VERSION ""

NS_ :

BS_:

BU_: External_Tool CADM LRRF MRRRL MRRRR

BO_ 954 MRR_RL_Radar_Reset_Msg: 1 MRRRL
 SG_ MRR_RL_Radar_Reset : 7|1@0+ (1,0) [0|1] ""  CADM

BO_ 1978 MRR_RR_Radar_Reset_msg: 1 MRRRR
 SG_ MRR_RR_Radar_Reset : 7|1@0+ (1,0) [0|1] ""  CADM

BO_ 93 LRRF1_Radar_Reset_Msg: 1 LRRF
 SG_ LRRF1_Radar_Reset : 7|1@0+ (1,0) [0|1] ""  CADM

BO_ 1698 MRR_RR_Radar_PartNumber: 64 MRRRR
 SG_ MRR_RR_EBOM_SW_PN_Part2 : 367|40@0+ (1,0) [0|1099511627775] ""  CADM
 SG_ MRR_RR_EBOM_SW_PN_Part1 : 327|40@0+ (1,0) [0|1099511627775] ""  CADM
 SG_ MRR_RR_ECU_SerialNumber_Part2 : 159|56@0+ (1,0) [0|7.20575940379279E+016] ""  CADM
 SG_ MRR_RR_ECU_SerialNumber_Part1 : 95|64@0+ (1,0) [0|1.84467440737096E+019] ""  CADM
 SG_ MRR_RR_EBOM_ECU_PN_Part2 : 447|40@0+ (1,0) [0|1099511627775] ""  CADM
 SG_ MRR_RR_EBOM_ECU_PN_Part1 : 407|40@0+ (1,0) [0|1099511627775] ""  CADM
 SG_ MRR_RR_SupplManuf_ECU_SW_VesrNum : 311|16@0+ (1,0) [0|65535] ""  CADM
 SG_ MRR_RR_SupplManuf_ECU_HW_VesrNum : 303|8@0+ (1,0) [0|255] ""  CADM
 SG_ MRR_RR_SupplManuf_ECU_SW_PN_2 : 263|40@0+ (1,0) [0|1099511627775] ""  CADM
 SG_ MRR_RR_SupplManuf_ECU_SW_PN_1 : 215|48@0+ (1,0) [0|281474976710655] ""  CADM
 SG_ MRR_RR_SupplManuf_ECU_HW_PN_2 : 55|40@0+ (1,0) [0|1099511627775] ""  CADM
 SG_ MRR_RR_SupplManuf_ECU_HW_PN_1 : 7|48@0+ (1,0) [0|281474976710655] ""  CADM

BO_ 690 MRR_RL_Radar_PartNumber: 64 MRRRL
 SG_ MRR_RL_EBOM_SW_PN_Part2 : 367|40@0+ (1,0) [0|1099511627775] ""  CADM
 SG_ MRR_RL_EBOM_SW_PN_Part1 : 327|40@0+ (1,0) [0|1099511627775] ""  CADM
 SG_ MRR_RL_ECU_SerialNumber_Part2 : 159|56@0+ (1,0) [0|7.20575940379279E+016] ""  CADM
 SG_ MRR_RL_ECU_SerialNumber_Part1 : 95|64@0+ (1,0) [0|1.84467440737096E+019] ""  CADM
 SG_ MRR_RL_EBOM_ECU_PN_Part2 : 447|40@0+ (1,0) [0|1099511627775] ""  CADM
 SG_ MRR_RL_EBOM_ECU_PN_Part1 : 407|40@0+ (1,0) [0|1099511627775] ""  CADM
 SG_ MRR_RL_SupplManuf_ECU_SW_VesrNum : 311|16@0+ (1,0) [0|65535] ""  CADM
 SG_ MRR_RL_SupplManuf_ECU_HW_VesrNum : 303|8@0+ (1,0) [0|255] ""  CADM
 SG_ MRR_RL_SupplManuf_ECU_SW_PN_2 : 263|40@0+ (1,0) [0|1099511627775] ""  CADM
 SG_ MRR_RL_SupplManuf_ECU_SW_PN_1 : 215|48@0+ (1,0) [0|281474976710655] ""  CADM
 SG_ MRR_RL_SupplManuf_ECU_HW_PN_2 : 55|40@0+ (1,0) [0|1099511627775] ""  CADM
 SG_ MRR_RL_SupplManuf_ECU_HW_PN_1 : 7|48@0+ (1,0) [0|281474976710655] ""  CADM

BO_ 94 LRRF1_Radar_PartNumber: 64 LRRF
 SG_ LRRF1_EBOM_SW_PN_Part2 : 367|40@0+ (1,0) [0|1099511627775] ""  CADM
 SG_ LRRF1_EBOM_SW_PN_Part1 : 327|40@0+ (1,0) [0|1099511627775] ""  CADM
 SG_ LRRF1_ECU_SerialNumber_Part2 : 159|56@0+ (1,0) [0|7.20575940379279E+016] ""  CADM
 SG_ LRRF1_ECU_SerialNumber_Part1 : 95|64@0+ (1,0) [0|1.84467440737096E+019] ""  CADM
 SG_ LRRF1_EBOM_ECU_PN_Part2 : 447|40@0+ (1,0) [0|1099511627775] ""  CADM
 SG_ LRRF1_EBOM_ECU_PN_Part1 : 407|40@0+ (1,0) [0|1099511627775] ""  CADM
 SG_ LRRF1_SupplManuf_ECU_SW_VesrNum : 311|16@0+ (1,0) [0|65535] ""  CADM
 SG_ LRRF1_SupplManuf_ECU_HW_VesrNum : 303|8@0+ (1,0) [0|255] ""  CADM
 SG_ LRRF1_SupplManuf_ECU_SW_PN_2 : 263|40@0+ (1,0) [0|1099511627775] ""  CADM
 SG_ LRRF1_SupplManuf_ECU_SW_PN_1 : 215|48@0+ (1,0) [0|281474976710655] ""  CADM
 SG_ LRRF1_SupplManuf_ECU_HW_PN_2 : 55|40@0+ (1,0) [0|1099511627775] ""  CADM
 SG_ LRRF1_SupplManuf_ECU_HW_PN_1 : 7|48@0+ (1,0) [0|281474976710655] ""  CADM

BO_ 39 MRR_RR_Angle_Adjustment_Table: 20 CADM
 SG_ MRR_RR_AAT_CRC : 151|16@0+ (1,0) [0|65535] ""  MRRRR
 SG_ MRR_RR_AAT_MC : 139|4@0+ (1,0) [0|15] ""  MRRRR
 SG_ MRR_RR_POS_80 : 135|8@0- (0.1,0) [-5|5] "deg"  MRRRR
 SG_ MRR_RR_POS_70 : 127|8@0- (0.1,0) [-5|5] "deg"  MRRRR
 SG_ MRR_RR_POS_60 : 119|8@0- (0.1,0) [-5|5] "deg"  MRRRR
 SG_ MRR_RR_POS_50 : 111|8@0- (0.1,0) [-5|5] "deg"  MRRRR
 SG_ MRR_RR_POS_40 : 103|8@0- (0.1,0) [-5|5] "deg"  MRRRR
 SG_ MRR_RR_POS_30 : 95|8@0- (0.1,0) [-5|5] "deg"  MRRRR
 SG_ MRR_RR_POS_20 : 87|8@0- (0.1,0) [-5|5] "deg"  MRRRR
 SG_ MRR_RR_POS_10 : 79|8@0- (0.1,0) [-5|5] "deg"  MRRRR
 SG_ MRR_RR_0 : 71|8@0- (0.1,0) [-5|5] "deg"  MRRRR
 SG_ MRR_RR_NEG_10 : 63|8@0- (0.1,0) [-5|5] "deg"  MRRRR
 SG_ MRR_RR_NEG_20 : 55|8@0- (0.1,0) [-5|5] "deg"  MRRRR
 SG_ MRR_RR_NEG_30 : 47|8@0- (0.1,0) [-5|5] "deg"  MRRRR
 SG_ MRR_RR_NEG_40 : 39|8@0- (0.1,0) [-5|5] "deg"  MRRRR
 SG_ MRR_RR_NEG_50 : 31|8@0- (0.1,0) [-5|5] "deg"  MRRRR
 SG_ MRR_RR_NEG_60 : 23|8@0- (0.1,0) [-5|5] "deg"  MRRRR
 SG_ MRR_RR_NEG_70 : 15|8@0- (0.1,0) [-5|5] "deg"  MRRRR
 SG_ MRR_RR_NEG_80 : 7|8@0- (0.1,0) [-5|5] "deg"  MRRRR

BO_ 38 MRR_RL_Angle_Adjustment_Table: 20 CADM
 SG_ MRR_RL_AAT_CRC : 151|16@0+ (1,0) [0|65535] ""  MRRRL
 SG_ MRR_RL_AAT_MC : 139|4@0+ (1,0) [0|15] ""  MRRRL
 SG_ MRR_RL_POS_80 : 135|8@0- (0.1,0) [-5|5] "deg"  MRRRL
 SG_ MRR_RL_POS_70 : 127|8@0- (0.1,0) [-5|5] "deg"  MRRRL
 SG_ MRR_RL_POS_60 : 119|8@0- (0.1,0) [-5|5] "deg"  MRRRL
 SG_ MRR_RL_POS_50 : 111|8@0- (0.1,0) [-5|5] "deg"  MRRRL
 SG_ MRR_RL_POS_40 : 103|8@0- (0.1,0) [-5|5] "deg"  MRRRL
 SG_ MRR_RL_POS_30 : 95|8@0- (0.1,0) [-5|5] "deg"  MRRRL
 SG_ MRR_RL_POS_20 : 87|8@0- (0.1,0) [-5|5] "deg"  MRRRL
 SG_ MRR_RL_POS_10 : 79|8@0- (0.1,0) [-5|5] "deg"  MRRRL
 SG_ MRR_RL_0 : 71|8@0- (0.1,0) [-5|5] "deg"  MRRRL
 SG_ MRR_RL_NEG_10 : 63|8@0- (0.1,0) [-5|5] "deg"  MRRRL
 SG_ MRR_RL_NEG_20 : 55|8@0- (0.1,0) [-5|5] "deg"  MRRRL
 SG_ MRR_RL_NEG_30 : 47|8@0- (0.1,0) [-5|5] "deg"  MRRRL
 SG_ MRR_RL_NEG_40 : 39|8@0- (0.1,0) [-5|5] "deg"  MRRRL
 SG_ MRR_RL_NEG_50 : 31|8@0- (0.1,0) [-5|5] "deg"  MRRRL
 SG_ MRR_RL_NEG_60 : 23|8@0- (0.1,0) [-5|5] "deg"  MRRRL
 SG_ MRR_RL_NEG_70 : 15|8@0- (0.1,0) [-5|5] "deg"  MRRRL
 SG_ MRR_RL_NEG_80 : 7|8@0- (0.1,0) [-5|5] "deg"  MRRRL

BO_ 35 LRRF1_Error_Status: 24 LRRF
 SG_ LRRF1_XBAR_cfg_failure : 191|1@0+ (1,0) [0|1] ""  External_Tool
 SG_ LRRF1_Stack_OVF_fault_reason : 183|3@0+ (1,0) [0|7] ""  External_Tool
 SG_ LRRF1_App_flash_checksum_reason : 180|3@0+ (1,0) [0|7] ""  External_Tool
 SG_ LRRF1_KAM_fault_reason : 177|2@0+ (1,0) [0|3] ""  External_Tool
 SG_ LRRF1_RRU_Self_Test_Faults_reaso : 175|8@0+ (1,0) [0|255] ""  External_Tool
 SG_ LRRF1_RRU_Core_Faults_reason3 : 167|8@0+ (1,0) [0|255] ""  External_Tool
 SG_ LRRF1_RRU_Core_Faults_reason2 : 103|64@0+ (1,0) [0|1.84467440737096E+019] ""  External_Tool
 SG_ LRRF1_RRU_Core_Faults_reason1 : 39|64@0+ (1,0) [0|1.84467440737096E+019] ""  External_Tool
 SG_ LRRF1_Rx_Radar_Mount_Msg_Fault : 25|1@0+ (1,0) [0|1] ""  External_Tool
 SG_ LRRF1_USC_Fault_Flag : 24|1@0+ (1,0) [0|1] ""  External_Tool
 SG_ LRRF1_SMC_Fault_Flag : 31|1@0+ (1,0) [0|1] ""  External_Tool
 SG_ LRRF1_Dolphin_Fault_Detection : 23|8@0+ (1,0) [0|63] ""  External_Tool
 SG_ LRRF1_RRU_Self_Test_Faults__0000 : 15|8@0+ (1,0) [0|255] ""  External_Tool
 SG_ LRRF1_RRU_Core_Faults_reason0 : 7|8@0+ (1,0) [0|255] ""  External_Tool

BO_ 69 LRRF1_HW_ID: 64 LRRF
 SG_ LRRF1_CAN_TX_HW_VERSION : 391|4@0+ (1,0) [0|15] ""  CADM
 SG_ LRRF1_Dolphin_Chip_ID_Part2 : 327|64@0+ (1,0) [0|1.84467440737096E+019] ""  CADM
 SG_ LRRF1_Dolphin_Chip_ID_Part1 : 263|64@0+ (1,0) [0|1.84467440737096E+019] ""  CADM
 SG_ LRRF1_RRU_Chip_ID_Part4 : 199|64@0+ (1,0) [0|1.84467440737096E+019] ""  CADM
 SG_ LRRF1_RRU_Chip_ID_Part3 : 135|64@0+ (1,0) [0|1.84467440737096E+019] ""  CADM
 SG_ LRRF1_RRU_Chip_ID_Part2 : 71|64@0+ (1,0) [0|1.84467440737096E+019] ""  CADM
 SG_ LRRF1_RRU_Chip_ID_Part1 : 7|64@0+ (1,0) [0|1.84467440737096E+019] ""  CADM

BO_ 1797 LRRF1_Radar_Cfg_Parameters: 24 CADM
 SG_ LRRF1_FA_HorizMisalignLim : 175|8@0+ (0.1,0) [0|13] "deg"  LRRF
 SG_ LRRF1_FA_TstTolerancePlateAngPos : 167|8@0+ (0.1,0) [0|13] "dBsm"  LRRF
 SG_ LRRF1_FA_TstTolerancePlateAng0 : 159|8@0+ (0.1,0) [0|13] "dBsm"  LRRF
 SG_ LRRF1_FA_TstTolerancePlateAngNeg : 151|8@0+ (0.1,0) [0|13] "dBsm"  LRRF
 SG_ LRRF1_FA_Negative_Angle : 141|6@0+ (0.1,-4) [-4|0] "deg"  LRRF
 SG_ LRRF1_FA_Positive_Angle : 133|6@0+ (0.1,0) [0|4] "deg"  LRRF
 SG_ LRRF1_FA_Target_Range2Mirror : 118|7@0+ (0.0625,0) [0|4] "m"  LRRF
 SG_ LRRF1_FA_Bdgt_Fascia_Attenuation : 126|7@0+ (0.1,-5) [-5|5] "dB"  LRRF
 SG_ LRRF1_Radar_CfgType : 33|2@0+ (1,0) [0|3] ""  LRRF
 SG_ SensorCfg_LRRF_AlignRngTolVert : 111|8@0- (0.0625,0) [-8|7.9375] "deg"  LRRF
 SG_ SensorCfg_LRRF_AlignRngTolHorz : 103|8@0- (0.0625,0) [-8|7.9375] "deg"  LRRF
 SG_ LRRF1_SENSR_CFG_CRC : 183|16@0+ (1,0) [0|65535] ""  LRRF
 SG_ SensorCfg_LRRF_LatPos : 63|16@0- (1,0) [-1000|1000] "mm"  LRRF
 SG_ SensorCfg_LRRF_LongPos : 79|16@0- (1,0) [-32768|32767] "mm"  LRRF
 SG_ SensorCfg_LRRF_VertPos : 47|16@0+ (1,0) [0|2550] "mm"  LRRF
 SG_ SensorCfg_LRRF_Pitch : 23|20@0- (1.526E-005,0) [-6|6] "deg"  LRRF
 SG_ SensorCfg_LRRF_Yaw : 7|16@0- (0.01,0) [-5|5] "deg"  LRRF
 SG_ SensorCfg_LRRF_Orientation : 95|8@0- (1,0) [-1|1] ""  LRRF

BO_ 81 LRRF1_Detection_050_056: 64 LRRF
 SG_ LRRF1_CAN_DET_Near_TARGET_56 : 454|1@0+ (1,0) [0|1] ""  CADM
 SG_ LRRF1_CAN_DET_Near_TARGET_55 : 453|1@0+ (1,0) [0|1] ""  CADM
 SG_ LRRF1_CAN_DET_Near_TARGET_54 : 452|1@0+ (1,0) [0|1] ""  CADM
 SG_ LRRF1_CAN_DET_Near_TARGET_53 : 451|1@0+ (1,0) [0|1] ""  CADM
 SG_ LRRF1_CAN_DET_Near_TARGET_52 : 450|1@0+ (1,0) [0|1] ""  CADM
 SG_ LRRF1_CAN_DET_Near_TARGET_51 : 449|1@0+ (1,0) [0|1] ""  CADM
 SG_ LRRF1_CAN_DET_Near_TARGET_50 : 448|1@0+ (1,0) [0|1] ""  CADM
 SG_ LRRF1_CAN_DET_VALID_LEVEL_51 : 64|1@0+ (1,0) [0|1] ""  CADM
 SG_ LRRF1_CAN_DET_VALID_LEVEL_52 : 128|1@0+ (1,0) [0|1] ""  CADM
 SG_ LRRF1_CAN_DET_VALID_LEVEL_53 : 192|1@0+ (1,0) [0|1] ""  CADM
 SG_ LRRF1_CAN_DET_VALID_LEVEL_54 : 256|1@0+ (1,0) [0|1] ""  CADM
 SG_ LRRF1_CAN_DET_VALID_LEVEL_55 : 320|1@0+ (1,0) [0|1] ""  CADM
 SG_ LRRF1_CAN_DET_VALID_LEVEL_56 : 384|1@0+ (1,0) [0|1] ""  CADM
 SG_ LRRF1_CAN_DET_AMPLITUDE_51 : 71|7@0+ (1,-64) [-64|63] "dBsm"  CADM
 SG_ LRRF1_CAN_DET_AMPLITUDE_52 : 135|7@0+ (1,-64) [-64|63] "dBsm"  CADM
 SG_ LRRF1_CAN_DET_AMPLITUDE_53 : 199|7@0+ (1,-64) [-64|63] "dBsm"  CADM
 SG_ LRRF1_CAN_DET_AMPLITUDE_54 : 263|7@0+ (1,-64) [-64|63] "dBsm"  CADM
 SG_ LRRF1_CAN_DET_AMPLITUDE_55 : 327|7@0+ (1,-64) [-64|63] "dBsm"  CADM
 SG_ LRRF1_CAN_DET_AMPLITUDE_56 : 391|7@0+ (1,-64) [-64|63] "dBsm"  CADM
 SG_ LRRF1_CAN_DET_AZIMUTH_51 : 111|14@0+ (0.0003834,-3.1416) [-3.1416|3.1396422] "rad"  CADM
 SG_ LRRF1_CAN_DET_AZIMUTH_52 : 175|14@0+ (0.0003834,-3.1416) [-3.1416|3.1396422] "rad"  CADM
 SG_ LRRF1_CAN_DET_AZIMUTH_53 : 239|14@0+ (0.0003834,-3.1416) [-3.1416|3.1396422] "rad"  CADM
 SG_ LRRF1_CAN_DET_AZIMUTH_54 : 303|14@0+ (0.0003834,-3.1416) [-3.1416|3.1396422] "rad"  CADM
 SG_ LRRF1_CAN_DET_AZIMUTH_55 : 367|14@0+ (0.0003834,-3.1416) [-3.1416|3.1396422] "rad"  CADM
 SG_ LRRF1_CAN_DET_AZIMUTH_56 : 431|14@0+ (0.0003834,-3.1416) [-3.1416|3.1396422] "rad"  CADM
 SG_ LRRF1_CAN_DET_CONFID_AZIMUTH_51 : 97|2@0+ (1,0) [0|3] ""  CADM
 SG_ LRRF1_CAN_DET_CONFID_AZIMUTH_52 : 161|2@0+ (1,0) [0|3] ""  CADM
 SG_ LRRF1_CAN_DET_CONFID_AZIMUTH_53 : 225|2@0+ (1,0) [0|3] ""  CADM
 SG_ LRRF1_CAN_DET_CONFID_AZIMUTH_54 : 289|2@0+ (1,0) [0|3] ""  CADM
 SG_ LRRF1_CAN_DET_CONFID_AZIMUTH_55 : 353|2@0+ (1,0) [0|3] ""  CADM
 SG_ LRRF1_CAN_DET_CONFID_AZIMUTH_56 : 417|2@0+ (1,0) [0|3] ""  CADM
 SG_ LRRF1_CAN_DET_CONFID_ELEVATION_5 : 120|1@0+ (1,0) [0|1] ""  CADM
 SG_ LRRF1_CAN_DET_CONFID_ELEVAT_0000 : 184|1@0+ (1,0) [0|1] ""  CADM
 SG_ LRRF1_CAN_DET_CONFID_ELEVAT_0001 : 248|1@0+ (1,0) [0|1] ""  CADM
 SG_ LRRF1_CAN_DET_CONFID_ELEVAT_0002 : 312|1@0+ (1,0) [0|1] ""  CADM
 SG_ LRRF1_CAN_DET_CONFID_ELEVAT_0003 : 376|1@0+ (1,0) [0|1] ""  CADM
 SG_ LRRF1_CAN_DET_CONFID_ELEVAT_0004 : 440|1@0+ (1,0) [0|1] ""  CADM
 SG_ LRRF1_CAN_DET_ELEVATION_51 : 127|7@0+ (0.002748,-0.1745) [-0.1745|0.174496] "rad"  CADM
 SG_ LRRF1_CAN_DET_ELEVATION_52 : 191|7@0+ (0.002748,-0.1745) [-0.1745|0.174496] "rad"  CADM
 SG_ LRRF1_CAN_DET_ELEVATION_53 : 255|7@0+ (0.002748,-0.1745) [-0.1745|0.174496] "rad"  CADM
 SG_ LRRF1_CAN_DET_ELEVATION_54 : 319|7@0+ (0.002748,-0.1745) [-0.1745|0.174496] "rad"  CADM
 SG_ LRRF1_CAN_DET_ELEVATION_55 : 383|7@0+ (0.002748,-0.1745) [-0.1745|0.174496] "rad"  CADM
 SG_ LRRF1_CAN_DET_ELEVATION_56 : 447|7@0+ (0.002748,-0.1745) [-0.1745|0.174496] "rad"  CADM
 SG_ LRRF1_CAN_DET_HOST_VEH_CLUTTER_5 : 113|1@0+ (1,0) [0|1] ""  CADM
 SG_ LRRF1_CAN_DET_HOST_VEH_CLUT_0000 : 177|1@0+ (1,0) [0|1] ""  CADM
 SG_ LRRF1_CAN_DET_HOST_VEH_CLUT_0001 : 241|1@0+ (1,0) [0|1] ""  CADM
 SG_ LRRF1_CAN_DET_HOST_VEH_CLUT_0002 : 305|1@0+ (1,0) [0|1] ""  CADM
 SG_ LRRF1_CAN_DET_HOST_VEH_CLUT_0003 : 369|1@0+ (1,0) [0|1] ""  CADM
 SG_ LRRF1_CAN_DET_HOST_VEH_CLUT_0004 : 433|1@0+ (1,0) [0|1] ""  CADM
 SG_ LRRF1_CAN_DET_SUPER_RES_TARGET_5 : 112|1@0+ (1,0) [0|1] ""  CADM
 SG_ LRRF1_CAN_DET_SUPER_RES_TAR_0000 : 176|1@0+ (1,0) [0|1] ""  CADM
 SG_ LRRF1_CAN_DET_SUPER_RES_TAR_0001 : 240|1@0+ (1,0) [0|1] ""  CADM
 SG_ LRRF1_CAN_DET_SUPER_RES_TAR_0002 : 304|1@0+ (1,0) [0|1] ""  CADM
 SG_ LRRF1_CAN_DET_SUPER_RES_TAR_0003 : 368|1@0+ (1,0) [0|1] ""  CADM
 SG_ LRRF1_CAN_DET_SUPER_RES_TAR_0004 : 432|1@0+ (1,0) [0|1] ""  CADM
 SG_ LRRF1_CAN_DET_RANGE_51 : 95|14@0+ (0.015625,0) [0|255.984375] "m"  CADM
 SG_ LRRF1_CAN_DET_RANGE_52 : 159|14@0+ (0.015625,0) [0|255.984375] "m"  CADM
 SG_ LRRF1_CAN_DET_RANGE_53 : 223|14@0+ (0.015625,0) [0|255.984375] "m"  CADM
 SG_ LRRF1_CAN_DET_RANGE_54 : 287|14@0+ (0.015625,0) [0|255.984375] "m"  CADM
 SG_ LRRF1_CAN_DET_RANGE_55 : 351|14@0+ (0.015625,0) [0|255.984375] "m"  CADM
 SG_ LRRF1_CAN_DET_RANGE_56 : 415|14@0+ (0.015625,0) [0|255.984375] "m"  CADM
 SG_ LRRF1_CAN_DET_RANGE_RATE_51 : 79|14@0+ (0.015625,-128) [-128|127.984375] "m/s"  CADM
 SG_ LRRF1_CAN_DET_RANGE_RATE_52 : 143|14@0+ (0.015625,-128) [-128|127.984375] "m/s"  CADM
 SG_ LRRF1_CAN_DET_RANGE_RATE_53 : 207|14@0+ (0.015625,-128) [-128|127.984375] "m/s"  CADM
 SG_ LRRF1_CAN_DET_RANGE_RATE_54 : 271|14@0+ (0.015625,-128) [-128|127.984375] "m/s"  CADM
 SG_ LRRF1_CAN_DET_RANGE_RATE_55 : 335|14@0+ (0.015625,-128) [-128|127.984375] "m/s"  CADM
 SG_ LRRF1_CAN_DET_RANGE_RATE_56 : 399|14@0+ (0.015625,-128) [-128|127.984375] "m/s"  CADM
 SG_ LRRF1_CAN_SCAN_INDEX_2LSB_51 : 81|2@0+ (1,0) [0|3] ""  CADM
 SG_ LRRF1_CAN_SCAN_INDEX_2LSB_52 : 145|2@0+ (1,0) [0|3] ""  CADM
 SG_ LRRF1_CAN_SCAN_INDEX_2LSB_53 : 209|2@0+ (1,0) [0|3] ""  CADM
 SG_ LRRF1_CAN_SCAN_INDEX_2LSB_54 : 273|2@0+ (1,0) [0|3] ""  CADM
 SG_ LRRF1_CAN_SCAN_INDEX_2LSB_55 : 337|2@0+ (1,0) [0|3] ""  CADM
 SG_ LRRF1_CAN_SCAN_INDEX_2LSB_56 : 401|2@0+ (1,0) [0|3] ""  CADM
 SG_ LRRF1_Det_MC_08 : 491|4@0+ (1,0) [0|15] ""  CADM
 SG_ LRRF1_Det_CRC_08 : 503|16@0+ (1,0) [0|65535] ""  CADM
 SG_ LRRF1_CAN_SCAN_INDEX_2LSB_50 : 17|2@0+ (1,0) [0|3] ""  CADM
 SG_ LRRF1_CAN_DET_AMPLITUDE_50 : 7|7@0+ (1,-64) [-64|63] "dBsm"  CADM
 SG_ LRRF1_CAN_DET_RANGE_RATE_50 : 15|14@0+ (0.015625,-128) [-128|127.984375] "m/s"  CADM
 SG_ LRRF1_CAN_DET_RANGE_50 : 31|14@0+ (0.015625,0) [0|255.984375] "m"  CADM
 SG_ LRRF1_CAN_DET_AZIMUTH_50 : 47|14@0+ (0.0003834,-3.1416) [-3.1416|3.1396422] "rad"  CADM
 SG_ LRRF1_CAN_DET_VALID_LEVEL_50 : 0|1@0+ (1,0) [0|1] ""  CADM
 SG_ LRRF1_CAN_DET_HOST_VEH_CLUT_0005 : 49|1@0+ (1,0) [0|1] ""  CADM
 SG_ LRRF1_CAN_DET_CONFID_ELEVAT_0005 : 48|1@0+ (1,0) [0|1] ""  CADM
 SG_ LRRF1_CAN_DET_SUPER_RES_TAR_0005 : 56|1@0+ (1,0) [0|1] ""  CADM
 SG_ LRRF1_CAN_DET_CONFID_AZIMUTH_50 : 33|2@0+ (1,0) [0|3] ""  CADM
 SG_ LRRF1_CAN_DET_ELEVATION_50 : 63|7@0+ (0.002748,-0.1745) [-0.1745|0.174496] "rad"  CADM

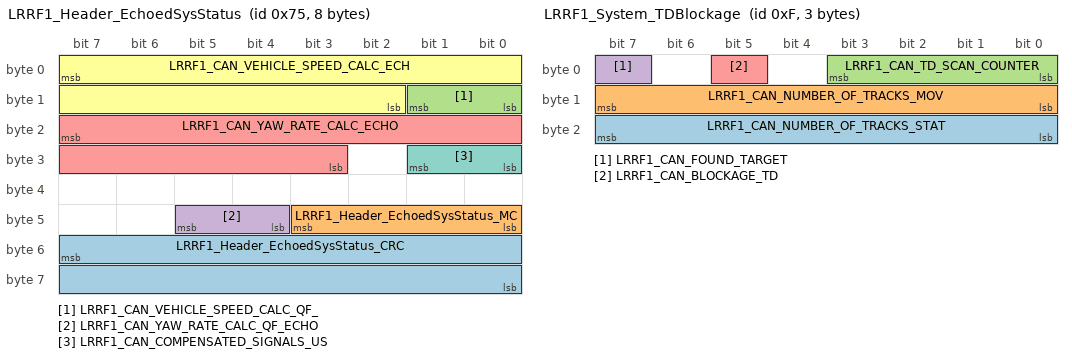
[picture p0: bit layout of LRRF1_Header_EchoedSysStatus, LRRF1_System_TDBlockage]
BO_ 117 LRRF1_Header_EchoedSysStatus: 8 LRRF
 SG_ LRRF1_Header_EchoedSysStatus_CRC : 55|16@0+ (1,0) [0|65535] ""  CADM
 SG_ LRRF1_Header_EchoedSysStatus_MC : 43|4@0+ (1,0) [0|15] ""  CADM
 SG_ LRRF1_CAN_VEHICLE_SPEED_CALC_QF_ : 9|2@0+ (1,0) [0|3] ""  CADM
 SG_ LRRF1_CAN_YAW_RATE_CALC_QF_ECHO : 45|2@0+ (1,0) [0|3] ""  CADM
 SG_ LRRF1_CAN_YAW_RATE_CALC_ECHO : 23|13@0+ (0.03125,-100) [-100|100] "deg/s"  CADM
 SG_ LRRF1_CAN_VEHICLE_SPEED_CALC_ECH : 7|14@0+ (0.01,0) [0|100] "m/s"  CADM
 SG_ LRRF1_CAN_COMPENSATED_SIGNALS_US : 25|2@0+ (1,0) [0|2] ""  CADM

BO_ 126 LRRF1_CADM_TracksChange: 1 CADM
 SG_ LRRF1_f_Radar_Unreasonable : 7|1@0+ (1,0) [0|1] ""  LRRF

BO_ 33 LRRF1_Active_Faults_Status: 20 LRRF
 SG_ LRRF2_SgnlRationalityCk_Flt : 114|1@0+ (1,0) [0|1] ""  External_Tool,CADM
 SG_ LRRF2_PCANDataRangeChk_Flt : 113|1@0+ (1,0) [0|1] ""  CADM,External_Tool
 SG_ LRRF2_PCANBusOff_Flt : 17|1@0+ (1,0) [0|1] ""  CADM,External_Tool
 SG_ LRRF1_TO_CADMSWVersion_Flt : 95|1@0+ (1,0) [0|1] ""  CADM,External_Tool
 SG_ LRRF2_TO_RADARCfgParameter_Flt : 112|1@0+ (1,0) [0|1] ""  CADM,External_Tool
 SG_ LRRF1_Active_Fault_Status_CRC : 151|16@0+ (1,0) [0|65535] ""  CADM,External_Tool
 SG_ LRRF1_Active_Fault_Status_MC : 139|4@0+ (1,0) [0|15] ""  CADM,External_Tool
 SG_ LRRF2_TO_SATCADMVIN_Flt : 111|1@0+ (1,0) [0|1] ""  CADM,External_Tool
 SG_ LRRF2_TO_CADMTracksChange_Flt : 110|1@0+ (1,0) [0|1] ""  CADM,External_Tool
 SG_ LRRF2_TO_CADMSWVersion_Flt : 109|1@0+ (1,0) [0|1] ""  CADM,External_Tool
 SG_ LRRF2_TO_TDBlockage_Flt : 106|1@0+ (1,0) [0|1] ""  CADM,External_Tool
 SG_ LRRF2_TO_CADMSgnlActlVal_Flt : 105|1@0+ (1,0) [0|1] ""  CADM,External_Tool
 SG_ LRRF2_TO_TrigControl_Flt : 104|1@0+ (1,0) [0|1] ""  CADM,External_Tool
 SG_ LRRF2_TO_VehicleState_Flt : 103|1@0+ (1,0) [0|1] ""  CADM,External_Tool
 SG_ LRRF2_MC_VehicleState_Flt : 102|1@0+ (1,0) [0|1] ""  CADM,External_Tool
 SG_ LRRF2_CRC_VehicleState_Flt : 101|1@0+ (1,0) [0|1] ""  CADM,External_Tool
 SG_ LRRF2_MC_TrigControl_Flt : 100|1@0+ (1,0) [0|1] ""  CADM,External_Tool
 SG_ LRRF2_CRC_TrigControl_Flt : 99|1@0+ (1,0) [0|1] ""  CADM,External_Tool
 SG_ LRRF2_CRC_RadarCfgParameter_Flt : 98|1@0+ (1,0) [0|1] ""  CADM,External_Tool
 SG_ LRRF2_MC_CADMSgnlActlVal_Flt : 97|1@0+ (1,0) [0|1] ""  CADM,External_Tool
 SG_ LRRF2_CRC_CADMSgnlActlVal_Flt : 96|1@0+ (1,0) [0|1] ""  CADM,External_Tool
 SG_ LRRF1_TO_RADARCfgParameter_Flt : 94|1@0+ (1,0) [0|1] ""  CADM,External_Tool
 SG_ LRRF1_TO_SATCADMVIN_Flt : 93|1@0+ (1,0) [0|1] ""  CADM,External_Tool
 SG_ LRRF1_TO_CADMTracksChange_Flt : 92|1@0+ (1,0) [0|1] ""  CADM,External_Tool
 SG_ LRRF1_TO_SystemTDBlockage_Flt : 87|1@0+ (1,0) [0|1] ""  CADM,External_Tool
 SG_ LRRF1_TO_CADMSgnlActlVal_Flt : 86|1@0+ (1,0) [0|1] ""  CADM,External_Tool
 SG_ LRRF1_TO_TrigControl_Flt : 85|1@0+ (1,0) [0|1] ""  CADM,External_Tool
 SG_ LRRF1_TO_VehicleState_Flt : 84|1@0+ (1,0) [0|1] ""  CADM,External_Tool
 SG_ LRRF1_MC_VehicleState_Flt : 81|1@0+ (1,0) [0|1] ""  CADM,External_Tool
 SG_ LRRF1_CRC_VehicleState_Flt : 80|1@0+ (1,0) [0|1] ""  CADM,External_Tool
 SG_ LRRF1_MC_TrigControl_Flt : 79|1@0+ (1,0) [0|1] ""  CADM,External_Tool
 SG_ LRRF1_CRC_TrigControl_Flt : 78|1@0+ (1,0) [0|1] ""  CADM,External_Tool
 SG_ LRRF1_CRC_RadarCfgParameter_Flt : 75|1@0+ (1,0) [0|1] ""  CADM,External_Tool
 SG_ LRRF1_MC_CADMSgnlActlVal_Flt : 74|1@0+ (1,0) [0|1] ""  CADM,External_Tool
 SG_ LRRF1_CRC_CADMSgnlActlVal_Flt : 73|1@0+ (1,0) [0|1] ""  CADM,External_Tool
 SG_ LRRF1_RRUBIST_Flt : 72|1@0+ (1,0) [0|1] ""  CADM,External_Tool
 SG_ LRRF1_Dolphin_Flt : 71|1@0+ (1,0) [0|1] ""  CADM,External_Tool
 SG_ LRRF1_RRUCore_Flt : 70|1@0+ (1,0) [0|1] ""  CADM,External_Tool
 SG_ LRRF1_PCANDataRangeChk_Flt : 68|1@0+ (1,0) [0|1] ""  CADM,External_Tool
 SG_ LRRF1_VINSignalCompare_Flt : 66|1@0+ (1,0) [0|1] ""  CADM,External_Tool
 SG_ LRRF1_BatteryLow_Flt : 63|1@0+ (1,0) [0|1] ""  CADM,External_Tool
 SG_ LRRF1_BatteryHigh_Flt : 62|1@0+ (1,0) [0|1] ""  CADM,External_Tool
 SG_ LRRF1_Core1_To_Core0_IPC_Flt : 61|1@0+ (1,0) [0|1] ""  CADM,External_Tool
 SG_ LRRF1_Core0_To_Core1_IPC_Flt : 60|1@0+ (1,0) [0|1] ""  CADM,External_Tool
 SG_ LRRF1_Core1_To_Core2_IPC_Flt : 59|1@0+ (1,0) [0|1] ""  CADM,External_Tool
 SG_ LRRF1_Core2_To_Core1_IPC_Flt : 58|1@0+ (1,0) [0|1] ""  CADM,External_Tool
 SG_ LRRF1_Core2_To_Core0_IPC_Flt : 57|1@0+ (1,0) [0|1] ""  CADM,External_Tool
 SG_ LRRF1_Core2Halted_Flt : 19|1@0+ (1,0) [0|1] ""  External_Tool,CADM
 SG_ LRRF1_Core1Halted_Flt : 18|1@0+ (1,0) [0|1] ""  External_Tool,CADM
 SG_ LRRF1_LocalOscPower_Flt : 50|1@0+ (1,0) [0|1] ""  External_Tool,CADM
 SG_ LRRF1_DSPLoopOverrun_Flt : 54|1@0+ (1,0) [0|1] ""  External_Tool,CADM
 SG_ LRRF1_TransmitterPower_Flt : 49|1@0+ (1,0) [0|1] ""  External_Tool,CADM
 SG_ LRRF1_Core0_To_Core2_IPC_Flt : 56|1@0+ (1,0) [0|1] ""  External_Tool,CADM
 SG_ LRRF1_XCVRDeviceSPI_Flt : 45|1@0+ (1,0) [0|1] ""  External_Tool,CADM
 SG_ LRRF1_SidelobeBlockage_Flt : 42|1@0+ (1,0) [0|1] ""  External_Tool,CADM
 SG_ LRRF1_MNRBlockage_Flt : 40|1@0+ (1,0) [0|1] ""  External_Tool,CADM
 SG_ LRRF1_TransmitterTempHigh_Flt : 38|1@0+ (1,0) [0|1] ""  External_Tool,CADM
 SG_ LRRF1_AlignRoutineFailed_Flt : 37|1@0+ (1,0) [0|1] ""  External_Tool,CADM
 SG_ LRRF1_MicroTempHigh_Flt : 35|1@0+ (1,0) [0|1] ""  External_Tool,CADM
 SG_ LRRF1_FactoryAlignmentMode_Flt : 32|1@0+ (1,0) [0|1] ""  External_Tool,CADM
 SG_ LRRF1_VAlignOutofRange_Flt : 34|1@0+ (1,0) [0|1] ""  External_Tool,CADM
 SG_ LRRF1_HAlignOutofRange_Flt : 33|1@0+ (1,0) [0|1] ""  External_Tool,CADM
 SG_ LRRF1_v1p1_SupplyOutOfRange_Flt : 30|1@0+ (1,0) [0|1] ""  External_Tool,CADM
 SG_ LRRF1_v1p25_SupplyOutOfRange_Flt : 29|1@0+ (1,0) [0|1] ""  External_Tool,CADM
 SG_ LRRF1_v1p8_SupplyOutOfRange_Flt : 28|1@0+ (1,0) [0|1] ""  External_Tool,CADM
 SG_ LRRF1_v2p3_SupplyOutOfRange_Flt : 27|1@0+ (1,0) [0|1] ""  External_Tool,CADM
 SG_ LRRF1_v_5_SupplyOutOfRange_Flt : 24|1@0+ (1,0) [0|1] ""  External_Tool,CADM
 SG_ LRRF1_TransmitterID_Flt : 23|1@0+ (1,0) [0|1] ""  External_Tool,CADM
 SG_ LRRF1_PCANBusOff_Flt : 16|1@0+ (1,0) [0|1] ""  External_Tool,CADM
 SG_ LRRF1_InstructionSetCheck_Flt : 13|1@0+ (1,0) [0|1] ""  External_Tool,CADM
 SG_ LRRF1_StackOverflow_Flt : 12|1@0+ (1,0) [0|1] ""  External_Tool,CADM
 SG_ LRRF1_Watchdog_Flt : 11|1@0+ (1,0) [0|1] ""  External_Tool,CADM
 SG_ LRRF1_PLLLock_Flt : 10|1@0+ (1,0) [0|1] ""  External_Tool,CADM
 SG_ LRRF1_RAMMemoryTest_Flt : 8|1@0+ (1,0) [0|1] ""  External_Tool,CADM
 SG_ LRRF1_USCValidation_Flt : 7|1@0+ (1,0) [0|1] ""  External_Tool,CADM
 SG_ LRRF1_SMC_Checksum_Flt : 4|1@0+ (1,0) [0|1] ""  External_Tool,CADM
 SG_ LRRF1_KeepAliveChecksum_Flt : 2|1@0+ (1,0) [0|1] ""  External_Tool,CADM
 SG_ LRRF1_ApplicationFlashChksum_Flt : 0|1@0+ (1,0) [0|1] ""  External_Tool,CADM

BO_ 122 LRRF1_XCP_DAQ_Resp: 64 LRRF
 SG_ LRRF1_XCP_DAQ_Resp_byte63 : 511|8@0+ (1,0) [0|255] ""  External_Tool
 SG_ LRRF1_XCP_DAQ_Resp_byte62 : 503|8@0+ (1,0) [0|255] ""  External_Tool
 SG_ LRRF1_XCP_DAQ_Resp_byte61 : 495|8@0+ (1,0) [0|255] ""  External_Tool
 SG_ LRRF1_XCP_DAQ_Resp_byte60 : 487|8@0+ (1,0) [0|255] ""  External_Tool
 SG_ LRRF1_XCP_DAQ_Resp_byte59 : 479|8@0+ (1,0) [0|255] ""  External_Tool
 SG_ LRRF1_XCP_DAQ_Resp_byte58 : 471|8@0+ (1,0) [0|255] ""  External_Tool
 SG_ LRRF1_XCP_DAQ_Resp_byte57 : 463|8@0+ (1,0) [0|255] ""  External_Tool
 SG_ LRRF1_XCP_DAQ_Resp_byte56 : 455|8@0+ (1,0) [0|255] ""  External_Tool
 SG_ LRRF1_XCP_DAQ_Resp_byte55 : 447|8@0+ (1,0) [0|255] ""  External_Tool
 SG_ LRRF1_XCP_DAQ_Resp_byte54 : 439|8@0+ (1,0) [0|255] ""  External_Tool
 SG_ LRRF1_XCP_DAQ_Resp_byte53 : 431|8@0+ (1,0) [0|255] ""  External_Tool
 SG_ LRRF1_XCP_DAQ_Resp_byte52 : 423|8@0+ (1,0) [0|255] ""  External_Tool
 SG_ LRRF1_XCP_DAQ_Resp_byte51 : 415|8@0+ (1,0) [0|255] ""  External_Tool
 SG_ LRRF1_XCP_DAQ_Resp_byte50 : 407|8@0+ (1,0) [0|255] ""  External_Tool
 SG_ LRRF1_XCP_DAQ_Resp_byte49 : 399|8@0+ (1,0) [0|255] ""  External_Tool
 SG_ LRRF1_XCP_DAQ_Resp_byte48 : 391|8@0+ (1,0) [0|255] ""  External_Tool
 SG_ LRRF1_XCP_DAQ_Resp_byte47 : 383|8@0+ (1,0) [0|255] ""  External_Tool
 SG_ LRRF1_XCP_DAQ_Resp_byte46 : 375|8@0+ (1,0) [0|255] ""  External_Tool
 SG_ LRRF1_XCP_DAQ_Resp_byte45 : 367|8@0+ (1,0) [0|255] ""  External_Tool
 SG_ LRRF1_XCP_DAQ_Resp_byte44 : 359|8@0+ (1,0) [0|255] ""  External_Tool
 SG_ LRRF1_XCP_DAQ_Resp_byte43 : 351|8@0+ (1,0) [0|255] ""  External_Tool
 SG_ LRRF1_XCP_DAQ_Resp_byte42 : 343|8@0+ (1,0) [0|255] ""  External_Tool
 SG_ LRRF1_XCP_DAQ_Resp_byte41 : 335|8@0+ (1,0) [0|255] ""  External_Tool
 SG_ LRRF1_XCP_DAQ_Resp_byte40 : 327|8@0+ (1,0) [0|255] ""  External_Tool
 SG_ LRRF1_XCP_DAQ_Resp_byte39 : 319|8@0+ (1,0) [0|255] ""  External_Tool
 SG_ LRRF1_XCP_DAQ_Resp_byte38 : 311|8@0+ (1,0) [0|255] ""  External_Tool
 SG_ LRRF1_XCP_DAQ_Resp_byte37 : 303|8@0+ (1,0) [0|255] ""  External_Tool
 SG_ LRRF1_XCP_DAQ_Resp_byte36 : 295|8@0+ (1,0) [0|255] ""  External_Tool
 SG_ LRRF1_XCP_DAQ_Resp_byte35 : 287|8@0+ (1,0) [0|255] ""  External_Tool
 SG_ LRRF1_XCP_DAQ_Resp_byte34 : 279|8@0+ (1,0) [0|255] ""  External_Tool
 SG_ LRRF1_XCP_DAQ_Resp_byte33 : 271|8@0+ (1,0) [0|255] ""  External_Tool
 SG_ LRRF1_XCP_DAQ_Resp_byte32 : 263|8@0+ (1,0) [0|255] ""  External_Tool
 SG_ LRRF1_XCP_DAQ_Resp_byte31 : 255|8@0+ (1,0) [0|255] ""  External_Tool
 SG_ LRRF1_XCP_DAQ_Resp_byte30 : 247|8@0+ (1,0) [0|255] ""  External_Tool
 SG_ LRRF1_XCP_DAQ_Resp_byte29 : 239|8@0+ (1,0) [0|255] ""  External_Tool
 SG_ LRRF1_XCP_DAQ_Resp_byte28 : 231|8@0+ (1,0) [0|255] ""  External_Tool
 SG_ LRRF1_XCP_DAQ_Resp_byte27 : 223|8@0+ (1,0) [0|255] ""  External_Tool
 SG_ LRRF1_XCP_DAQ_Resp_byte26 : 215|8@0+ (1,0) [0|255] ""  External_Tool
 SG_ LRRF1_XCP_DAQ_Resp_byte25 : 207|8@0+ (1,0) [0|255] ""  External_Tool
 SG_ LRRF1_XCP_DAQ_Resp_byte24 : 199|8@0+ (1,0) [0|255] ""  External_Tool
 SG_ LRRF1_XCP_DAQ_Resp_byte23 : 191|8@0+ (1,0) [0|255] ""  External_Tool
 SG_ LRRF1_XCP_DAQ_Resp_byte22 : 183|8@0+ (1,0) [0|255] ""  External_Tool
 SG_ LRRF1_XCP_DAQ_Resp_byte21 : 175|8@0+ (1,0) [0|255] ""  External_Tool
 SG_ LRRF1_XCP_DAQ_Resp_byte20 : 167|8@0+ (1,0) [0|255] ""  External_Tool
 SG_ LRRF1_XCP_DAQ_Resp_byte19 : 159|8@0+ (1,0) [0|255] ""  External_Tool
 SG_ LRRF1_XCP_DAQ_Resp_byte18 : 151|8@0+ (1,0) [0|255] ""  External_Tool
 SG_ LRRF1_XCP_DAQ_Resp_byte17 : 143|8@0+ (1,0) [0|255] ""  External_Tool
 SG_ LRRF1_XCP_DAQ_Resp_byte16 : 135|8@0+ (1,0) [0|255] ""  External_Tool
 SG_ LRRF1_XCP_DAQ_Resp_byte15 : 127|8@0+ (1,0) [0|255] ""  External_Tool
 SG_ LRRF1_XCP_DAQ_Resp_byte14 : 119|8@0+ (1,0) [0|255] ""  External_Tool
 SG_ LRRF1_XCP_DAQ_Resp_byte13 : 111|8@0+ (1,0) [0|255] ""  External_Tool
 SG_ LRRF1_XCP_DAQ_Resp_byte12 : 103|8@0+ (1,0) [0|255] ""  External_Tool
 SG_ LRRF1_XCP_DAQ_Resp_byte11 : 95|8@0+ (1,0) [0|255] ""  External_Tool
 SG_ LRRF1_XCP_DAQ_Resp_byte10 : 87|8@0+ (1,0) [0|255] ""  External_Tool
 SG_ LRRF1_XCP_DAQ_Resp_byte9 : 79|8@0+ (1,0) [0|255] ""  External_Tool
 SG_ LRRF1_XCP_DAQ_Resp_byte8 : 71|8@0+ (1,0) [0|255] ""  External_Tool
 SG_ LRRF1_XCP_DAQ_Resp_byte7 : 63|8@0+ (1,0) [0|255] ""  External_Tool
 SG_ LRRF1_XCP_DAQ_Resp_byte6 : 55|8@0+ (1,0) [0|255] ""  External_Tool
 SG_ LRRF1_XCP_DAQ_Resp_byte5 : 47|8@0+ (1,0) [0|255] ""  External_Tool
 SG_ LRRF1_XCP_DAQ_Resp_byte4 : 39|8@0+ (1,0) [0|255] ""  External_Tool
 SG_ LRRF1_XCP_DAQ_Resp_byte3 : 31|8@0+ (1,0) [0|255] ""  External_Tool
 SG_ LRRF1_XCP_DAQ_Resp_byte2 : 23|8@0+ (1,0) [0|255] ""  External_Tool
 SG_ LRRF1_XCP_DAQ_Resp_byte1 : 15|8@0+ (1,0) [0|255] ""  External_Tool
 SG_ LRRF1_XCP_DAQ_Resp_byte0 : 7|8@0+ (1,0) [0|255] ""  External_Tool

BO_ 121 LRRF1_XCP_DTO_Resp: 64 LRRF
 SG_ LRRF1_XCP_DTO_Resp_byte63 : 511|8@0+ (1,0) [0|255] ""  External_Tool
 SG_ LRRF1_XCP_DTO_Resp_byte62 : 503|8@0+ (1,0) [0|255] ""  External_Tool
 SG_ LRRF1_XCP_DTO_Resp_byte61 : 495|8@0+ (1,0) [0|255] ""  External_Tool
 SG_ LRRF1_XCP_DTO_Resp_byte60 : 487|8@0+ (1,0) [0|255] ""  External_Tool
 SG_ LRRF1_XCP_DTO_Resp_byte59 : 479|8@0+ (1,0) [0|255] ""  External_Tool
 SG_ LRRF1_XCP_DTO_Resp_byte58 : 471|8@0+ (1,0) [0|255] ""  External_Tool
 SG_ LRRF1_XCP_DTO_Resp_byte57 : 463|8@0+ (1,0) [0|255] ""  External_Tool
 SG_ LRRF1_XCP_DTO_Resp_byte56 : 455|8@0+ (1,0) [0|255] ""  External_Tool
 SG_ LRRF1_XCP_DTO_Resp_byte55 : 447|8@0+ (1,0) [0|255] ""  External_Tool
 SG_ LRRF1_XCP_DTO_Resp_byte54 : 439|8@0+ (1,0) [0|255] ""  External_Tool
 SG_ LRRF1_XCP_DTO_Resp_byte53 : 431|8@0+ (1,0) [0|255] ""  External_Tool
 SG_ LRRF1_XCP_DTO_Resp_byte52 : 423|8@0+ (1,0) [0|255] ""  External_Tool
 SG_ LRRF1_XCP_DTO_Resp_byte51 : 415|8@0+ (1,0) [0|255] ""  External_Tool
 SG_ LRRF1_XCP_DTO_Resp_byte50 : 407|8@0+ (1,0) [0|255] ""  External_Tool
 SG_ LRRF1_XCP_DTO_Resp_byte49 : 399|8@0+ (1,0) [0|255] ""  External_Tool
 SG_ LRRF1_XCP_DTO_Resp_byte48 : 391|8@0+ (1,0) [0|255] ""  External_Tool
 SG_ LRRF1_XCP_DTO_Resp_byte47 : 383|8@0+ (1,0) [0|255] ""  External_Tool
 SG_ LRRF1_XCP_DTO_Resp_byte46 : 375|8@0+ (1,0) [0|255] ""  External_Tool
 SG_ LRRF1_XCP_DTO_Resp_byte45 : 367|8@0+ (1,0) [0|255] ""  External_Tool
 SG_ LRRF1_XCP_DTO_Resp_byte44 : 359|8@0+ (1,0) [0|255] ""  External_Tool
 SG_ LRRF1_XCP_DTO_Resp_byte43 : 351|8@0+ (1,0) [0|255] ""  External_Tool
 SG_ LRRF1_XCP_DTO_Resp_byte42 : 343|8@0+ (1,0) [0|255] ""  External_Tool
 SG_ LRRF1_XCP_DTO_Resp_byte41 : 335|8@0+ (1,0) [0|255] ""  External_Tool
 SG_ LRRF1_XCP_DTO_Resp_byte40 : 327|8@0+ (1,0) [0|255] ""  External_Tool
 SG_ LRRF1_XCP_DTO_Resp_byte39 : 319|8@0+ (1,0) [0|255] ""  External_Tool
 SG_ LRRF1_XCP_DTO_Resp_byte38 : 311|8@0+ (1,0) [0|255] ""  External_Tool
 SG_ LRRF1_XCP_DTO_Resp_byte37 : 303|8@0+ (1,0) [0|255] ""  External_Tool
 SG_ LRRF1_XCP_DTO_Resp_byte36 : 295|8@0+ (1,0) [0|255] ""  External_Tool
 SG_ LRRF1_XCP_DTO_Resp_byte35 : 287|8@0+ (1,0) [0|255] ""  External_Tool
 SG_ LRRF1_XCP_DTO_Resp_byte34 : 279|8@0+ (1,0) [0|255] ""  External_Tool
 SG_ LRRF1_XCP_DTO_Resp_byte33 : 271|8@0+ (1,0) [0|255] ""  External_Tool
 SG_ LRRF1_XCP_DTO_Resp_byte32 : 263|8@0+ (1,0) [0|255] ""  External_Tool
 SG_ LRRF1_XCP_DTO_Resp_byte31 : 255|8@0+ (1,0) [0|255] ""  External_Tool
 SG_ LRRF1_XCP_DTO_Resp_byte30 : 247|8@0+ (1,0) [0|255] ""  External_Tool
 SG_ LRRF1_XCP_DTO_Resp_byte29 : 239|8@0+ (1,0) [0|255] ""  External_Tool
 SG_ LRRF1_XCP_DTO_Resp_byte28 : 231|8@0+ (1,0) [0|255] ""  External_Tool
 SG_ LRRF1_XCP_DTO_Resp_byte27 : 223|8@0+ (1,0) [0|255] ""  External_Tool
 SG_ LRRF1_XCP_DTO_Resp_byte26 : 215|8@0+ (1,0) [0|255] ""  External_Tool
 SG_ LRRF1_XCP_DTO_Resp_byte25 : 207|8@0+ (1,0) [0|255] ""  External_Tool
 SG_ LRRF1_XCP_DTO_Resp_byte24 : 199|8@0+ (1,0) [0|255] ""  External_Tool
 SG_ LRRF1_XCP_DTO_Resp_byte23 : 191|8@0+ (1,0) [0|255] ""  External_Tool
 SG_ LRRF1_XCP_DTO_Resp_byte22 : 183|8@0+ (1,0) [0|255] ""  External_Tool
 SG_ LRRF1_XCP_DTO_Resp_byte21 : 175|8@0+ (1,0) [0|255] ""  External_Tool
 SG_ LRRF1_XCP_DTO_Resp_byte20 : 167|8@0+ (1,0) [0|255] ""  External_Tool
 SG_ LRRF1_XCP_DTO_Resp_byte19 : 159|8@0+ (1,0) [0|255] ""  External_Tool
 SG_ LRRF1_XCP_DTO_Resp_byte18 : 151|8@0+ (1,0) [0|255] ""  External_Tool
 SG_ LRRF1_XCP_DTO_Resp_byte17 : 143|8@0+ (1,0) [0|255] ""  External_Tool
 SG_ LRRF1_XCP_DTO_Resp_byte16 : 135|8@0+ (1,0) [0|255] ""  External_Tool
 SG_ LRRF1_XCP_DTO_Resp_byte15 : 127|8@0+ (1,0) [0|255] ""  External_Tool
 SG_ LRRF1_XCP_DTO_Resp_byte14 : 119|8@0+ (1,0) [0|255] ""  External_Tool
 SG_ LRRF1_XCP_DTO_Resp_byte13 : 111|8@0+ (1,0) [0|255] ""  External_Tool
 SG_ LRRF1_XCP_DTO_Resp_byte12 : 103|8@0+ (1,0) [0|255] ""  External_Tool
 SG_ LRRF1_XCP_DTO_Resp_byte11 : 95|8@0+ (1,0) [0|255] ""  External_Tool
 SG_ LRRF1_XCP_DTO_Resp_byte10 : 87|8@0+ (1,0) [0|255] ""  External_Tool
 SG_ LRRF1_XCP_DTO_Resp_byte9 : 79|8@0+ (1,0) [0|255] ""  External_Tool
 SG_ LRRF1_XCP_DTO_Resp_byte8 : 71|8@0+ (1,0) [0|255] ""  External_Tool
 SG_ LRRF1_XCP_DTO_Resp_byte7 : 63|8@0+ (1,0) [0|255] ""  External_Tool
 SG_ LRRF1_XCP_DTO_Resp_byte6 : 55|8@0+ (1,0) [0|255] ""  External_Tool
 SG_ LRRF1_XCP_DTO_Resp_byte5 : 47|8@0+ (1,0) [0|255] ""  External_Tool
 SG_ LRRF1_XCP_DTO_Resp_byte4 : 39|8@0+ (1,0) [0|255] ""  External_Tool
 SG_ LRRF1_XCP_DTO_Resp_byte3 : 31|8@0+ (1,0) [0|255] ""  External_Tool
 SG_ LRRF1_XCP_DTO_Resp_byte2 : 23|8@0+ (1,0) [0|255] ""  External_Tool
 SG_ LRRF1_XCP_DTO_Resp_byte1 : 15|8@0+ (1,0) [0|255] ""  External_Tool
 SG_ LRRF1_XCP_DTO_Resp_byte0 : 7|8@0+ (1,0) [0|255] ""  External_Tool

BO_ 120 LRRF1_XCP_DTO_Req: 64 External_Tool
 SG_ LRRF1_XCP_DTO_CMD_byte63 : 511|8@0+ (1,0) [0|255] ""  LRRF
 SG_ LRRF1_XCP_DTO_CMD_byte62 : 503|8@0+ (1,0) [0|255] ""  LRRF
 SG_ LRRF1_XCP_DTO_CMD_byte61 : 495|8@0+ (1,0) [0|255] ""  LRRF
 SG_ LRRF1_XCP_DTO_CMD_byte60 : 487|8@0+ (1,0) [0|255] ""  LRRF
 SG_ LRRF1_XCP_DTO_CMD_byte59 : 479|8@0+ (1,0) [0|255] ""  LRRF
 SG_ LRRF1_XCP_DTO_CMD_byte58 : 471|8@0+ (1,0) [0|255] ""  LRRF
 SG_ LRRF1_XCP_DTO_CMD_byte57 : 463|8@0+ (1,0) [0|255] ""  LRRF
 SG_ LRRF1_XCP_DTO_CMD_byte56 : 455|8@0+ (1,0) [0|255] ""  LRRF
 SG_ LRRF1_XCP_DTO_CMD_byte55 : 447|8@0+ (1,0) [0|255] ""  LRRF
 SG_ LRRF1_XCP_DTO_CMD_byte54 : 439|8@0+ (1,0) [0|255] ""  LRRF
 SG_ LRRF1_XCP_DTO_CMD_byte53 : 431|8@0+ (1,0) [0|255] ""  LRRF
 SG_ LRRF1_XCP_DTO_CMD_byte52 : 423|8@0+ (1,0) [0|255] ""  LRRF
 SG_ LRRF1_XCP_DTO_CMD_byte51 : 415|8@0+ (1,0) [0|255] ""  LRRF
 SG_ LRRF1_XCP_DTO_CMD_byte50 : 407|8@0+ (1,0) [0|255] ""  LRRF
 SG_ LRRF1_XCP_DTO_CMD_byte49 : 399|8@0+ (1,0) [0|255] ""  LRRF
 SG_ LRRF1_XCP_DTO_CMD_byte48 : 391|8@0+ (1,0) [0|255] ""  LRRF
 SG_ LRRF1_XCP_DTO_CMD_byte47 : 383|8@0+ (1,0) [0|255] ""  LRRF
 SG_ LRRF1_XCP_DTO_CMD_byte46 : 375|8@0+ (1,0) [0|255] ""  LRRF
 SG_ LRRF1_XCP_DTO_CMD_byte45 : 367|8@0+ (1,0) [0|255] ""  LRRF
 SG_ LRRF1_XCP_DTO_CMD_byte44 : 359|8@0+ (1,0) [0|255] ""  LRRF
 SG_ LRRF1_XCP_DTO_CMD_byte43 : 351|8@0+ (1,0) [0|255] ""  LRRF
 SG_ LRRF1_XCP_DTO_CMD_byte42 : 343|8@0+ (1,0) [0|255] ""  LRRF
 SG_ LRRF1_XCP_DTO_CMD_byte41 : 335|8@0+ (1,0) [0|255] ""  LRRF
 SG_ LRRF1_XCP_DTO_CMD_byte40 : 327|8@0+ (1,0) [0|255] ""  LRRF
 SG_ LRRF1_XCP_DTO_CMD_byte39 : 319|8@0+ (1,0) [0|255] ""  LRRF
 SG_ LRRF1_XCP_DTO_CMD_byte38 : 311|8@0+ (1,0) [0|255] ""  LRRF
 SG_ LRRF1_XCP_DTO_CMD_byte37 : 303|8@0+ (1,0) [0|255] ""  LRRF
 SG_ LRRF1_XCP_DTO_CMD_byte36 : 295|8@0+ (1,0) [0|255] ""  LRRF
 SG_ LRRF1_XCP_DTO_CMD_byte35 : 287|8@0+ (1,0) [0|255] ""  LRRF
 SG_ LRRF1_XCP_DTO_CMD_byte34 : 279|8@0+ (1,0) [0|255] ""  LRRF
 SG_ LRRF1_XCP_DTO_CMD_byte33 : 271|8@0+ (1,0) [0|255] ""  LRRF
 SG_ LRRF1_XCP_DTO_CMD_byte32 : 263|8@0+ (1,0) [0|255] ""  LRRF
 SG_ LRRF1_XCP_DTO_CMD_byte31 : 255|8@0+ (1,0) [0|255] ""  LRRF
 SG_ LRRF1_XCP_DTO_CMD_byte30 : 247|8@0+ (1,0) [0|255] ""  LRRF
 SG_ LRRF1_XCP_DTO_CMD_byte29 : 239|8@0+ (1,0) [0|255] ""  LRRF
 SG_ LRRF1_XCP_DTO_CMD_byte28 : 231|8@0+ (1,0) [0|255] ""  LRRF
 SG_ LRRF1_XCP_DTO_CMD_byte27 : 223|8@0+ (1,0) [0|255] ""  LRRF
 SG_ LRRF1_XCP_DTO_CMD_byte26 : 215|8@0+ (1,0) [0|255] ""  LRRF
 SG_ LRRF1_XCP_DTO_CMD_byte25 : 207|8@0+ (1,0) [0|255] ""  LRRF
 SG_ LRRF1_XCP_DTO_CMD_byte24 : 199|8@0+ (1,0) [0|255] ""  LRRF
 SG_ LRRF1_XCP_DTO_CMD_byte23 : 191|8@0+ (1,0) [0|255] ""  LRRF
 SG_ LRRF1_XCP_DTO_CMD_byte22 : 183|8@0+ (1,0) [0|255] ""  LRRF
 SG_ LRRF1_XCP_DTO_CMD_byte21 : 175|8@0+ (1,0) [0|255] ""  LRRF
 SG_ LRRF1_XCP_DTO_CMD_byte20 : 167|8@0+ (1,0) [0|255] ""  LRRF
 SG_ LRRF1_XCP_DTO_CMD_byte19 : 159|8@0+ (1,0) [0|255] ""  LRRF
 SG_ LRRF1_XCP_DTO_CMD_byte18 : 151|8@0+ (1,0) [0|255] ""  LRRF
 SG_ LRRF1_XCP_DTO_CMD_byte17 : 143|8@0+ (1,0) [0|255] ""  LRRF
 SG_ LRRF1_XCP_DTO_CMD_byte16 : 135|8@0+ (1,0) [0|255] ""  LRRF
 SG_ LRRF1_XCP_DTO_CMD_byte15 : 127|8@0+ (1,0) [0|255] ""  LRRF
 SG_ LRRF1_XCP_DTO_CMD_byte14 : 119|8@0+ (1,0) [0|255] ""  LRRF
 SG_ LRRF1_XCP_DTO_CMD_byte13 : 111|8@0+ (1,0) [0|255] ""  LRRF
 SG_ LRRF1_XCP_DTO_CMD_byte12 : 103|8@0+ (1,0) [0|255] ""  LRRF
 SG_ LRRF1_XCP_DTO_CMD_byte11 : 95|8@0+ (1,0) [0|255] ""  LRRF
 SG_ LRRF1_XCP_DTO_CMD_byte10 : 87|8@0+ (1,0) [0|255] ""  LRRF
 SG_ LRRF1_XCP_DTO_CMD_byte9 : 79|8@0+ (1,0) [0|255] ""  LRRF
 SG_ LRRF1_XCP_DTO_CMD_byte8 : 71|8@0+ (1,0) [0|255] ""  LRRF
 SG_ LRRF1_XCP_DTO_CMD_byte7 : 63|8@0+ (1,0) [0|255] ""  LRRF
 SG_ LRRF1_XCP_DTO_CMD_byte6 : 55|8@0+ (1,0) [0|255] ""  LRRF
 SG_ LRRF1_XCP_DTO_CMD_byte5 : 47|8@0+ (1,0) [0|255] ""  LRRF
 SG_ LRRF1_XCP_DTO_CMD_byte4 : 39|8@0+ (1,0) [0|255] ""  LRRF
 SG_ LRRF1_XCP_DTO_CMD_byte3 : 31|8@0+ (1,0) [0|255] ""  LRRF
 SG_ LRRF1_XCP_DTO_CMD_byte2 : 23|8@0+ (1,0) [0|255] ""  LRRF
 SG_ LRRF1_XCP_DTO_CMD_byte1 : 15|8@0+ (1,0) [0|255] ""  LRRF
 SG_ LRRF1_XCP_DTO_CMD_byte0 : 7|8@0+ (1,0) [0|255] ""  LRRF

BO_ 119 LRRF1_XCP_CTO_Resp: 64 LRRF
 SG_ LRRF1_XCP_CTO_Resp_byte63 : 511|8@0+ (1,0) [0|255] ""  External_Tool
 SG_ LRRF1_XCP_CTO_Resp_byte62 : 503|8@0+ (1,0) [0|255] ""  External_Tool
 SG_ LRRF1_XCP_CTO_Resp_byte61 : 495|8@0+ (1,0) [0|255] ""  External_Tool
 SG_ LRRF1_XCP_CTO_Resp_byte60 : 487|8@0+ (1,0) [0|255] ""  External_Tool
 SG_ LRRF1_XCP_CTO_Resp_byte59 : 479|8@0+ (1,0) [0|255] ""  External_Tool
 SG_ LRRF1_XCP_CTO_Resp_byte58 : 471|8@0+ (1,0) [0|255] ""  External_Tool
 SG_ LRRF1_XCP_CTO_Resp_byte57 : 463|8@0+ (1,0) [0|255] ""  External_Tool
 SG_ LRRF1_XCP_CTO_Resp_byte56 : 455|8@0+ (1,0) [0|255] ""  External_Tool
 SG_ LRRF1_XCP_CTO_Resp_byte55 : 447|8@0+ (1,0) [0|255] ""  External_Tool
 SG_ LRRF1_XCP_CTO_Resp_byte54 : 439|8@0+ (1,0) [0|255] ""  External_Tool
 SG_ LRRF1_XCP_CTO_Resp_byte53 : 431|8@0+ (1,0) [0|255] ""  External_Tool
 SG_ LRRF1_XCP_CTO_Resp_byte52 : 423|8@0+ (1,0) [0|255] ""  External_Tool
 SG_ LRRF1_XCP_CTO_Resp_byte51 : 415|8@0+ (1,0) [0|255] ""  External_Tool
 SG_ LRRF1_XCP_CTO_Resp_byte50 : 407|8@0+ (1,0) [0|255] ""  External_Tool
 SG_ LRRF1_XCP_CTO_Resp_byte49 : 399|8@0+ (1,0) [0|255] ""  External_Tool
 SG_ LRRF1_XCP_CTO_Resp_byte48 : 391|8@0+ (1,0) [0|255] ""  External_Tool
 SG_ LRRF1_XCP_CTO_Resp_byte47 : 383|8@0+ (1,0) [0|255] ""  External_Tool
 SG_ LRRF1_XCP_CTO_Resp_byte46 : 375|8@0+ (1,0) [0|255] ""  External_Tool
 SG_ LRRF1_XCP_CTO_Resp_byte45 : 367|8@0+ (1,0) [0|255] ""  External_Tool
 SG_ LRRF1_XCP_CTO_Resp_byte44 : 359|8@0+ (1,0) [0|255] ""  External_Tool
 SG_ LRRF1_XCP_CTO_Resp_byte43 : 351|8@0+ (1,0) [0|255] ""  External_Tool
 SG_ LRRF1_XCP_CTO_Resp_byte42 : 343|8@0+ (1,0) [0|255] ""  External_Tool
 SG_ LRRF1_XCP_CTO_Resp_byte41 : 335|8@0+ (1,0) [0|255] ""  External_Tool
 SG_ LRRF1_XCP_CTO_Resp_byte40 : 327|8@0+ (1,0) [0|255] ""  External_Tool
 SG_ LRRF1_XCP_CTO_Resp_byte39 : 319|8@0+ (1,0) [0|255] ""  External_Tool
 SG_ LRRF1_XCP_CTO_Resp_byte38 : 311|8@0+ (1,0) [0|255] ""  External_Tool
 SG_ LRRF1_XCP_CTO_Resp_byte37 : 303|8@0+ (1,0) [0|255] ""  External_Tool
 SG_ LRRF1_XCP_CTO_Resp_byte36 : 295|8@0+ (1,0) [0|255] ""  External_Tool
 SG_ LRRF1_XCP_CTO_Resp_byte35 : 287|8@0+ (1,0) [0|255] ""  External_Tool
 SG_ LRRF1_XCP_CTO_Resp_byte34 : 279|8@0+ (1,0) [0|255] ""  External_Tool
 SG_ LRRF1_XCP_CTO_Resp_byte33 : 271|8@0+ (1,0) [0|255] ""  External_Tool
 SG_ LRRF1_XCP_CTO_Resp_byte32 : 263|8@0+ (1,0) [0|255] ""  External_Tool
 SG_ LRRF1_XCP_CTO_Resp_byte31 : 255|8@0+ (1,0) [0|255] ""  External_Tool
 SG_ LRRF1_XCP_CTO_Resp_byte30 : 247|8@0+ (1,0) [0|255] ""  External_Tool
 SG_ LRRF1_XCP_CTO_Resp_byte29 : 239|8@0+ (1,0) [0|255] ""  External_Tool
 SG_ LRRF1_XCP_CTO_Resp_byte28 : 231|8@0+ (1,0) [0|255] ""  External_Tool
 SG_ LRRF1_XCP_CTO_Resp_byte27 : 223|8@0+ (1,0) [0|255] ""  External_Tool
 SG_ LRRF1_XCP_CTO_Resp_byte26 : 215|8@0+ (1,0) [0|255] ""  External_Tool
 SG_ LRRF1_XCP_CTO_Resp_byte25 : 207|8@0+ (1,0) [0|255] ""  External_Tool
 SG_ LRRF1_XCP_CTO_Resp_byte24 : 199|8@0+ (1,0) [0|255] ""  External_Tool
 SG_ LRRF1_XCP_CTO_Resp_byte23 : 191|8@0+ (1,0) [0|255] ""  External_Tool
 SG_ LRRF1_XCP_CTO_Resp_byte22 : 183|8@0+ (1,0) [0|255] ""  External_Tool
 SG_ LRRF1_XCP_CTO_Resp_byte21 : 175|8@0+ (1,0) [0|255] ""  External_Tool
 SG_ LRRF1_XCP_CTO_Resp_byte20 : 167|8@0+ (1,0) [0|255] ""  External_Tool
 SG_ LRRF1_XCP_CTO_Resp_byte19 : 159|8@0+ (1,0) [0|255] ""  External_Tool
 SG_ LRRF1_XCP_CTO_Resp_byte18 : 151|8@0+ (1,0) [0|255] ""  External_Tool
 SG_ LRRF1_XCP_CTO_Resp_byte17 : 143|8@0+ (1,0) [0|255] ""  External_Tool
 SG_ LRRF1_XCP_CTO_Resp_byte16 : 135|8@0+ (1,0) [0|255] ""  External_Tool
 SG_ LRRF1_XCP_CTO_Resp_byte15 : 127|8@0+ (1,0) [0|255] ""  External_Tool
 SG_ LRRF1_XCP_CTO_Resp_byte14 : 119|8@0+ (1,0) [0|255] ""  External_Tool
 SG_ LRRF1_XCP_CTO_Resp_byte13 : 111|8@0+ (1,0) [0|255] ""  External_Tool
 SG_ LRRF1_XCP_CTO_Resp_byte12 : 103|8@0+ (1,0) [0|255] ""  External_Tool
 SG_ LRRF1_XCP_CTO_Resp_byte11 : 95|8@0+ (1,0) [0|255] ""  External_Tool
 SG_ LRRF1_XCP_CTO_Resp_byte10 : 87|8@0+ (1,0) [0|255] ""  External_Tool
 SG_ LRRF1_XCP_CTO_Resp_byte9 : 79|8@0+ (1,0) [0|255] ""  External_Tool
 SG_ LRRF1_XCP_CTO_Resp_byte8 : 71|8@0+ (1,0) [0|255] ""  External_Tool
 SG_ LRRF1_XCP_CTO_Resp_byte7 : 63|8@0+ (1,0) [0|255] ""  External_Tool
 SG_ LRRF1_XCP_CTO_Resp_byte6 : 55|8@0+ (1,0) [0|255] ""  External_Tool
 SG_ LRRF1_XCP_CTO_Resp_byte5 : 47|8@0+ (1,0) [0|255] ""  External_Tool
 SG_ LRRF1_XCP_CTO_Resp_byte4 : 39|8@0+ (1,0) [0|255] ""  External_Tool
 SG_ LRRF1_XCP_CTO_Resp_byte3 : 31|8@0+ (1,0) [0|255] ""  External_Tool
 SG_ LRRF1_XCP_CTO_Resp_byte2 : 23|8@0+ (1,0) [0|255] ""  External_Tool
 SG_ LRRF1_XCP_CTO_Resp_byte1 : 15|8@0+ (1,0) [0|255] ""  External_Tool
 SG_ LRRF1_XCP_CTO_Resp_byte0 : 7|8@0+ (1,0) [0|255] ""  External_Tool

BO_ 118 LRRF1_XCP_CTO_Req: 64 External_Tool
 SG_ LRRF1_XCP_CTO_CMD_byte63 : 511|8@0+ (1,0) [0|255] ""  LRRF
 SG_ LRRF1_XCP_CTO_CMD_byte62 : 503|8@0+ (1,0) [0|255] ""  LRRF
 SG_ LRRF1_XCP_CTO_CMD_byte61 : 495|8@0+ (1,0) [0|255] ""  LRRF
 SG_ LRRF1_XCP_CTO_CMD_byte60 : 487|8@0+ (1,0) [0|255] ""  LRRF
 SG_ LRRF1_XCP_CTO_CMD_byte59 : 479|8@0+ (1,0) [0|255] ""  LRRF
 SG_ LRRF1_XCP_CTO_CMD_byte58 : 471|8@0+ (1,0) [0|255] ""  LRRF
 SG_ LRRF1_XCP_CTO_CMD_byte57 : 463|8@0+ (1,0) [0|255] ""  LRRF
 SG_ LRRF1_XCP_CTO_CMD_byte56 : 455|8@0+ (1,0) [0|255] ""  LRRF
 SG_ LRRF1_XCP_CTO_CMD_byte55 : 447|8@0+ (1,0) [0|255] ""  LRRF
 SG_ LRRF1_XCP_CTO_CMD_byte54 : 439|8@0+ (1,0) [0|255] ""  LRRF
 SG_ LRRF1_XCP_CTO_CMD_byte53 : 431|8@0+ (1,0) [0|255] ""  LRRF
 SG_ LRRF1_XCP_CTO_CMD_byte52 : 423|8@0+ (1,0) [0|255] ""  LRRF
 SG_ LRRF1_XCP_CTO_CMD_byte51 : 415|8@0+ (1,0) [0|255] ""  LRRF
 SG_ LRRF1_XCP_CTO_CMD_byte50 : 407|8@0+ (1,0) [0|255] ""  LRRF
 SG_ LRRF1_XCP_CTO_CMD_byte49 : 399|8@0+ (1,0) [0|255] ""  LRRF
 SG_ LRRF1_XCP_CTO_CMD_byte48 : 391|8@0+ (1,0) [0|255] ""  LRRF
 SG_ LRRF1_XCP_CTO_CMD_byte47 : 383|8@0+ (1,0) [0|255] ""  LRRF
 SG_ LRRF1_XCP_CTO_CMD_byte46 : 375|8@0+ (1,0) [0|255] ""  LRRF
 SG_ LRRF1_XCP_CTO_CMD_byte45 : 367|8@0+ (1,0) [0|255] ""  LRRF
 SG_ LRRF1_XCP_CTO_CMD_byte44 : 359|8@0+ (1,0) [0|255] ""  LRRF
 SG_ LRRF1_XCP_CTO_CMD_byte43 : 351|8@0+ (1,0) [0|255] ""  LRRF
 SG_ LRRF1_XCP_CTO_CMD_byte42 : 343|8@0+ (1,0) [0|255] ""  LRRF
 SG_ LRRF1_XCP_CTO_CMD_byte41 : 335|8@0+ (1,0) [0|255] ""  LRRF
 SG_ LRRF1_XCP_CTO_CMD_byte40 : 327|8@0+ (1,0) [0|255] ""  LRRF
 SG_ LRRF1_XCP_CTO_CMD_byte39 : 319|8@0+ (1,0) [0|255] ""  LRRF
 SG_ LRRF1_XCP_CTO_CMD_byte38 : 311|8@0+ (1,0) [0|255] ""  LRRF
 SG_ LRRF1_XCP_CTO_CMD_byte37 : 303|8@0+ (1,0) [0|255] ""  LRRF
 SG_ LRRF1_XCP_CTO_CMD_byte36 : 295|8@0+ (1,0) [0|255] ""  LRRF
 SG_ LRRF1_XCP_CTO_CMD_byte35 : 287|8@0+ (1,0) [0|255] ""  LRRF
 SG_ LRRF1_XCP_CTO_CMD_byte34 : 279|8@0+ (1,0) [0|255] ""  LRRF
 SG_ LRRF1_XCP_CTO_CMD_byte33 : 271|8@0+ (1,0) [0|255] ""  LRRF
 SG_ LRRF1_XCP_CTO_CMD_byte32 : 263|8@0+ (1,0) [0|255] ""  LRRF
 SG_ LRRF1_XCP_CTO_CMD_byte31 : 255|8@0+ (1,0) [0|255] ""  LRRF
 SG_ LRRF1_XCP_CTO_CMD_byte30 : 247|8@0+ (1,0) [0|255] ""  LRRF
 SG_ LRRF1_XCP_CTO_CMD_byte29 : 239|8@0+ (1,0) [0|255] ""  LRRF
 SG_ LRRF1_XCP_CTO_CMD_byte28 : 231|8@0+ (1,0) [0|255] ""  LRRF
 SG_ LRRF1_XCP_CTO_CMD_byte27 : 223|8@0+ (1,0) [0|255] ""  LRRF
 SG_ LRRF1_XCP_CTO_CMD_byte26 : 215|8@0+ (1,0) [0|255] ""  LRRF
 SG_ LRRF1_XCP_CTO_CMD_byte25 : 207|8@0+ (1,0) [0|255] ""  LRRF
 SG_ LRRF1_XCP_CTO_CMD_byte24 : 199|8@0+ (1,0) [0|255] ""  LRRF
 SG_ LRRF1_XCP_CTO_CMD_byte23 : 191|8@0+ (1,0) [0|255] ""  LRRF
 SG_ LRRF1_XCP_CTO_CMD_byte22 : 183|8@0+ (1,0) [0|255] ""  LRRF
 SG_ LRRF1_XCP_CTO_CMD_byte21 : 175|8@0+ (1,0) [0|255] ""  LRRF
 SG_ LRRF1_XCP_CTO_CMD_byte20 : 167|8@0+ (1,0) [0|255] ""  LRRF
 SG_ LRRF1_XCP_CTO_CMD_byte19 : 159|8@0+ (1,0) [0|255] ""  LRRF
 SG_ LRRF1_XCP_CTO_CMD_byte18 : 151|8@0+ (1,0) [0|255] ""  LRRF
 SG_ LRRF1_XCP_CTO_CMD_byte17 : 143|8@0+ (1,0) [0|255] ""  LRRF
 SG_ LRRF1_XCP_CTO_CMD_byte16 : 135|8@0+ (1,0) [0|255] ""  LRRF
 SG_ LRRF1_XCP_CTO_CMD_byte15 : 127|8@0+ (1,0) [0|255] ""  LRRF
 SG_ LRRF1_XCP_CTO_CMD_byte14 : 119|8@0+ (1,0) [0|255] ""  LRRF
 SG_ LRRF1_XCP_CTO_CMD_byte13 : 111|8@0+ (1,0) [0|255] ""  LRRF
 SG_ LRRF1_XCP_CTO_CMD_byte12 : 103|8@0+ (1,0) [0|255] ""  LRRF
 SG_ LRRF1_XCP_CTO_CMD_byte11 : 95|8@0+ (1,0) [0|255] ""  LRRF
 SG_ LRRF1_XCP_CTO_CMD_byte10 : 87|8@0+ (1,0) [0|255] ""  LRRF
 SG_ LRRF1_XCP_CTO_CMD_byte9 : 79|8@0+ (1,0) [0|255] ""  LRRF
 SG_ LRRF1_XCP_CTO_CMD_byte8 : 71|8@0+ (1,0) [0|255] ""  LRRF
 SG_ LRRF1_XCP_CTO_CMD_byte7 : 63|8@0+ (1,0) [0|255] ""  LRRF
 SG_ LRRF1_XCP_CTO_CMD_byte6 : 55|8@0+ (1,0) [0|255] ""  LRRF
 SG_ LRRF1_XCP_CTO_CMD_byte5 : 47|8@0+ (1,0) [0|255] ""  LRRF
 SG_ LRRF1_XCP_CTO_CMD_byte4 : 39|8@0+ (1,0) [0|255] ""  LRRF
 SG_ LRRF1_XCP_CTO_CMD_byte3 : 31|8@0+ (1,0) [0|255] ""  LRRF
 SG_ LRRF1_XCP_CTO_CMD_byte2 : 23|8@0+ (1,0) [0|255] ""  LRRF
 SG_ LRRF1_XCP_CTO_CMD_byte1 : 15|8@0+ (1,0) [0|255] ""  LRRF
 SG_ LRRF1_XCP_CTO_CMD_byte0 : 7|8@0+ (1,0) [0|255] ""  LRRF

BO_ 1900 LRRF1_Diag_Resp_Phys: 64 LRRF
 SG_ LRRF1_TesterPhysicalResLRRF : 7|64@0+ (1,0) [0|1.84467E+019] ""  CADM

BO_ 1892 LRRF1_Diag_Req_Phys: 64 CADM
 SG_ LRRF1_TesterPhysicalReqLRRF : 7|64@0+ (1,0) [0|1.84467E+019] ""  LRRF

BO_ 185 VEHICLE_STATE_MSG: 24 CADM
 SG_ CAN_CADM_Master : 57|2@0+ (1,0) [0|3] ""  External_Tool,LRRF,MRRRL,MRRRR
 SG_ CAN_STEERING_ANGLE : 119|14@0+ (0.1,0) [0|1638.3] "deg"  MRRRR,MRRRL,External_Tool,LRRF
 SG_ CAN_WIPER_STATUS : 42|1@0+ (1,0) [0|1] ""  MRRRR,MRRRL,External_Tool,LRRF
 SG_ CAN_VEHICLE_MODE : 107|4@0+ (1,0) [0|15] ""  MRRRR,MRRRL,External_Tool,LRRF
 SG_ CAN_YAW_RATE : 103|12@0+ (0.0625,-128) [-128|127.9375] "deg/s"  MRRRR,MRRRL,External_Tool,LRRF
 SG_ CAN_YAW_RATE_VALIDITY : 5|1@0+ (1,0) [0|1] ""  MRRRR,MRRRL,External_Tool,LRRF
 SG_ CAN_STEERING_ANGLE_SIGN : 7|1@0+ (1,0) [0|1] ""  MRRRR,MRRRL,External_Tool,LRRF
 SG_ CAN_VEHICLE_SPEED : 135|11@0+ (0.0625,0) [0|127.9375] "m/s"  MRRRR,MRRRL,External_Tool,LRRF
 SG_ CAN_VEHICLE_SPEED_DIRECTION : 10|1@0+ (1,0) [0|1] ""  MRRRR,MRRRL,External_Tool,LRRF
 SG_ CAN_VEHICLE_SPEED_VALIDITY : 11|1@0+ (1,0) [0|1] ""  MRRRR,MRRRL,External_Tool,LRRF
 SG_ CAN_CADM_DrivingDirection : 9|2@0+ (1,0) [0|1] ""  MRRRR,MRRRL,External_Tool,LRRF
 SG_ CAN_VEHICLE_STAT : 6|1@0+ (1,0) [0|1] ""  MRRRR,MRRRL,External_Tool,LRRF
 SG_ CAN_VEHICLE_SPEED_CALC : 87|14@0+ (0.01,0) [0|100] "m/s"  MRRRR,MRRRL,External_Tool,LRRF
 SG_ CAN_VEHICLE_SPEED_CALC_QF : 41|2@0+ (1,0) [0|3] ""  MRRRR,MRRRL,External_Tool,LRRF
 SG_ CAN_YAW_RATE_CALC : 71|13@0+ (0.03125,-100) [-100|100] "deg/s"  MRRRR,MRRRL,External_Tool,LRRF
 SG_ CAN_YAW_RATE_CALC_QF : 59|2@0+ (1,0) [0|3] ""  MRRRR,MRRRL,External_Tool,LRRF
 SG_ VEH_STATE_MSG_CRC : 183|16@0+ (1,0) [0|65535] ""  MRRRR,MRRRL,External_Tool,LRRF
 SG_ VEH_STATE_MSG_MC : 171|4@0+ (1,0) [0|15] ""  MRRRR,MRRRL,External_Tool,LRRF
 SG_ Yaw_Rate_Reference_Valid : 12|1@0+ (1,0) [0|1] "boolean"  MRRRR,MRRRL,LRRF,External_Tool
 SG_ Yaw_Rate_Reference : 55|12@0- (0.03663,0) [-75|75] "deg/s"  MRRRR,MRRRL,LRRF,External_Tool
 SG_ CAN_VEH_LONG_ACCEL_QF : 14|2@0+ (1,0) [0|3] ""  MRRRR,MRRRL,LRRF,External_Tool
 SG_ CAN_VEH_LONG_ACCEL : 39|13@0+ (0.01,-40) [-40|41.89] "m/s^2"  MRRRR,MRRRL,LRRF,External_Tool
 SG_ CAN_STEERING_WHL_ANGLE : 23|15@0+ (0.1,-1600) [-1600|1676.7] "deg"  MRRRR,MRRRL,LRRF,External_Tool
 SG_ CAN_STEERING_WHL_ANGLE_QF : 2|1@0+ (1,0) [0|1] ""  MRRRR,MRRRL,LRRF,External_Tool
 SG_ CAN_BRAKE_PEDAL : 1|2@0+ (1,0) [0|2] ""  MRRRR,MRRRL,LRRF,External_Tool
 SG_ CAN_TURN_SIGNAL_STATUS : 4|2@0+ (1,0) [0|3] ""  MRRRR,MRRRL,LRRF,External_Tool

BO_ 66 LRRF1_Status_SerialNumber: 8 LRRF
 SG_ LRRF1_CAN_SEQUENCE_NUMBER : 55|16@0+ (1,0) [0|65535] ""  External_Tool
 SG_ LRRF1_CAN_SERIAL_NUMBER : 7|40@0+ (1,0) [0|1099511627800] ""  External_Tool

BO_ 12 LRRF1_System_Control: 8 External_Tool
 SG_ LRRF1_CAN_INST_MODE : 23|16@0+ (1,0) [0|65535] ""  LRRF

BO_ 67 LRRF1_Status_SwVersion: 32 LRRF
 SG_ LRRF1_CAN_USC_SECTION_COMPTBLITY : 207|16@0+ (1,0) [0|65535] ""  CADM,External_Tool
 SG_ LRRF1_CAN_PCAN_PROMOTE_LRRF1 : 199|8@0+ (1,0) [0|255] ""  CADM,External_Tool
 SG_ LRRF1_CAN_PCAN_MINOR_LRRF1 : 191|8@0+ (1,0) [0|255] ""  CADM,External_Tool
 SG_ LRRF1_CAN_PCAN_MAJOR_LRRF1 : 183|8@0+ (1,0) [0|255] ""  CADM,External_Tool
 SG_ LRRF1_Core_Radar_BB_Version_Majo : 127|8@0+ (1,0) [0|255] ""  CADM,External_Tool
 SG_ LRRF1_CAN_Dyn_Align_Algorithm_Ve : 175|8@0+ (1,0) [0|255] ""  CADM,External_Tool
 SG_ LRRF1_CAN_Dyn_Align_Algorit_0000 : 167|8@0+ (1,0) [0|255] ""  CADM,External_Tool
 SG_ LRRF1_CAN_Dyn_Align_Algorit_0001 : 159|8@0+ (1,0) [0|255] ""  CADM,External_Tool
 SG_ LRRF1_Core_Radar_BB_Version_Fiel : 151|8@0+ (1,0) [0|255] ""  CADM,External_Tool
 SG_ LRRF1_Core_Radar_BB_Version_Prom : 143|8@0+ (1,0) [0|255] ""  CADM,External_Tool
 SG_ LRRF1_Core_Radar_BB_Version_Mino : 135|8@0+ (1,0) [0|255] ""  CADM,External_Tool
 SG_ LRRF1_CAN_USC_Field : 119|8@0+ (1,0) [0|255] ""  CADM,External_Tool
 SG_ LRRF1_CAN_SMC_Field : 87|8@0+ (1,0) [0|255] ""  CADM,External_Tool
 SG_ LRRF1_CAN_USC_Major : 95|8@0+ (1,0) [0|255] ""  CADM,External_Tool
 SG_ LRRF1_CAN_USC_Minor : 103|8@0+ (1,0) [0|255] ""  CADM,External_Tool
 SG_ LRRF1_CAN_USC_Promote : 111|8@0+ (1,0) [0|255] ""  CADM,External_Tool
 SG_ LRRF1_CAN_SMC_Major : 63|8@0+ (1,0) [0|255] ""  CADM,External_Tool
 SG_ LRRF1_CAN_SMC_Minor : 71|8@0+ (1,0) [0|255] ""  CADM,External_Tool
 SG_ LRRF1_CAN_SMC_Promote : 79|8@0+ (1,0) [0|255] ""  CADM,External_Tool
 SG_ LRRF1_CAN_PBL_Field_Revision : 55|8@0+ (1,0) [0|255] ""  CADM,External_Tool
 SG_ LRRF1_CAN_PBL_Promote_Revision : 47|8@0+ (1,0) [0|255] ""  CADM,External_Tool
 SG_ LRRF1_CAN_SW_Field_Revision : 23|8@0+ (1,0) [0|255] ""  CADM,External_Tool
 SG_ LRRF1_CAN_SW_Promote_Revision : 15|8@0+ (1,0) [0|255] ""  CADM,External_Tool
 SG_ LRRF1_CAN_SW_Field : 31|8@0+ (1,0) [0|255] ""  CADM,External_Tool
 SG_ LRRF1_CAN_SW_Release_Revision : 7|8@0+ (1,0) [0|255] ""  CADM,External_Tool
 SG_ LRRF1_CAN_PBL_Release_Revision : 39|8@0+ (1,0) [0|255] ""  CADM,External_Tool

BO_ 15 LRRF1_System_TDBlockage: 3 CADM
 SG_ LRRF1_CAN_NUMBER_OF_TRACKS_STAT : 23|8@0+ (1,0) [0|255] ""  LRRF,External_Tool
 SG_ LRRF1_CAN_NUMBER_OF_TRACKS_MOV : 15|8@0+ (1,0) [0|255] ""  LRRF,External_Tool
 SG_ LRRF1_CAN_TD_SCAN_COUNTER : 3|4@0+ (1,0) [0|15] ""  External_Tool,LRRF
 SG_ LRRF1_CAN_FOUND_TARGET : 7|1@0+ (1,0) [0|1] ""  External_Tool,LRRF
 SG_ LRRF1_CAN_BLOCKAGE_TD : 5|1@0+ (1,0) [0|1] ""  External_Tool,LRRF

BO_ 1795 SAT_CADM_VIN: 32 CADM
 SG_ k_radar_azimuth_polarity : 207|8@0- (1,0) [-2|1] ""  MRRRL,MRRRR,LRRF
 SG_ CAN_FA_VERT_UPPER_LIMIT : 199|8@0- (0.0625,0) [-8|7.9375] ""  MRRRL,MRRRR,LRRF
 SG_ CAN_FA_VERT_LOWER_LIMIT : 191|8@0- (0.0625,0) [-8|7.9375] ""  MRRRL,MRRRR,LRRF
 SG_ CAN_FA_VERT_GROUND_OFFSET : 183|8@0- (0.0625,0) [-8|7.9375] ""  MRRRL,MRRRR,LRRF
 SG_ SAT_CAN_ODOMETER : 143|20@0+ (1,0) [0|1048575] "km"  LRRF,MRRRL,MRRRR
 SG_ SAT_VIN_part3 : 135|8@0+ (1,0) [0|255] ""  MRRRR,MRRRL,LRRF
 SG_ SAT_VIN_part2 : 71|64@0+ (1,0) [0|1.84467E+019] ""  MRRRR,MRRRL,LRRF
 SG_ SAT_VIN_part1 : 7|64@0+ (1,0) [0|1.84467E+019] ""  MRRRR,MRRRL,LRRF

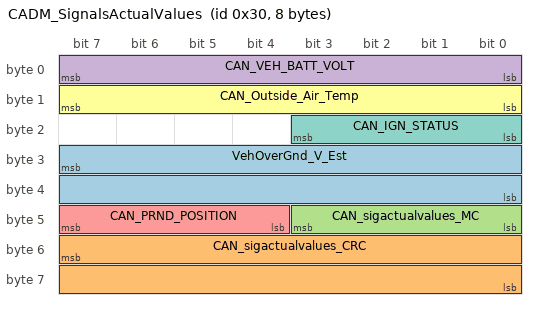
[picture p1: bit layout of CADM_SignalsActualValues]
BO_ 48 CADM_SignalsActualValues: 8 CADM
 SG_ VehOverGnd_V_Est : 31|16@0+ (0.01,0) [0|655.35] "kph"  MRRRR,MRRRL,External_Tool,LRRF
 SG_ CAN_sigactualvalues_CRC : 55|16@0+ (1,0) [0|65535] ""  MRRRR,MRRRL,LRRF
 SG_ CAN_sigactualvalues_MC : 43|4@0+ (1,0) [0|15] ""  MRRRR,MRRRL,LRRF
 SG_ CAN_VEH_BATT_VOLT : 7|8@0+ (0.0625,0) [0|15.875] "V"  MRRRR,MRRRL,LRRF
 SG_ CAN_PRND_POSITION : 47|4@0+ (1,0) [0|15] ""  MRRRR,MRRRL,LRRF
 SG_ CAN_Outside_Air_Temp : 15|8@0+ (0.5,-40) [-40|87.5] "C"  MRRRR,MRRRL,LRRF
 SG_ CAN_IGN_STATUS : 19|4@0+ (1,0) [0|15] ""  MRRRR,MRRRL,LRRF

BO_ 72 LRRF1_Header_SensorCoverage: 12 LRRF
 SG_ LRRF1_Header_SensorCoverage_CRC : 87|16@0+ (1,0) [0|65535] ""  CADM
 SG_ LRRF1_Header_SensorCoverage_MC : 75|4@0+ (1,0) [0|15] ""  CADM
 SG_ LRRF1_CAN_SENSOR_FOV_VER : 23|8@0+ (1,0) [0|255] "deg"  CADM
 SG_ LRRF1_CAN_SENSOR_FOV_HOR : 47|8@0+ (1,0) [0|255] "deg"  CADM
 SG_ LRRF1_CAN_DOPPLER_COVERAGE : 31|16@0- (0.0078125,0) [-256|255.9921875] "m/s"  CADM
 SG_ LRRF1_CAN_RANGE_COVERAGE : 7|16@0+ (0.0078125,0) [0|511.9921875] "m"  CADM

BO_ 70 LRRF1_Header_AlignmentState: 16 LRRF
 SG_ LRRF1_CAN_VRTCL_ALIGN_UPDATES_Nb : 71|16@0+ (1,0) [0|65535] ""  CADM,External_Tool
 SG_ LRRF1_CAN_HRZNTL_ALIGN_UPDATES_N : 87|16@0+ (1,0) [0|65535] ""  CADM,External_Tool
 SG_ LRRF1_Header_AlignmentState_CRC : 119|16@0+ (1,0) [0|65535] ""  CADM,External_Tool
 SG_ LRRF1_Header_AlignmentState_MC : 107|4@0+ (1,0) [0|15] ""  CADM,External_Tool
 SG_ LRRF1_Horizontal_Alignment_Statu : 27|4@0+ (1,0) [0|15] ""  CADM,External_Tool
 SG_ LRRF1_Vertical_Alignment_Status : 59|4@0+ (1,0) [0|15] ""  CADM,External_Tool
 SG_ LRRF1_Vertical_Alignment_State : 44|3@0+ (1,0) [0|7] ""  CADM,External_Tool
 SG_ LRRF1_Horizontal_Alignment_State : 12|3@0+ (1,0) [0|7] ""  CADM,External_Tool
 SG_ LRRF1_Align_Vertical_Ref : 55|10@0+ (0.000170608920038546,-0.0872664625997165) [-0.0872664625997165|0.0872664625997165] "Rad"  CADM,External_Tool
 SG_ LRRF1_Align_Vertical_QF : 41|2@0+ (1,0) [0|3] ""  CADM,External_Tool
 SG_ LRRF1_Align_Vertical_Angle : 39|10@0+ (0.000170608920038546,-0.0872664625997165) [-0.0872664625997165|0.0872664625997165] "Rad"  CADM,External_Tool
 SG_ LRRF1_Align_Horizontal_Angle : 7|10@0+ (0.000341217840077093,-0.174532925199433) [-0.174532925199433|0.174532925199433] "Rad"  CADM,External_Tool
 SG_ LRRF1_Align_Horizontal_Ref : 23|10@0+ (0.000341217840077093,-0.174532925199433) [-0.174532925199433|0.174532925199433] "Rad"  CADM,External_Tool
 SG_ LRRF1_Align_Horizontal_QF : 9|2@0+ (1,0) [0|3] ""  CADM,External_Tool

BO_ 71 LRRF1_Header_Timestamps: 16 LRRF
 SG_ LRRF1_CAN_NUMBER_OF_DET : 103|8@0+ (1,0) [0|255] ""  CADM
 SG_ LRRF1_LRRF1_CAN_SCAN_INDEX : 87|16@0+ (1,0) [0|65535] ""  CADM
 SG_ LRRF1_CAN_LOOK_INDEX : 71|16@0+ (1,0) [0|65535] ""  CADM
 SG_ LRRF1_CAN_LOOK_ID : 44|3@0+ (1,0) [0|7] ""  CADM
 SG_ LRRF1_Header_Timestamps_CRC : 119|16@0+ (1,0) [0|65535] ""  CADM
 SG_ LRRF1_Header_Timestamps_MC : 107|4@0+ (1,0) [0|15] ""  CADM
 SG_ LRRF1_CAN_ReSync_counter : 55|16@0+ (1,0) [0|65535] ""  CADM
 SG_ LRRF1_CAN_DET_TIME_SINCE_MEAS : 39|11@0+ (0.1,0) [0|204.7] "ms"  CADM
 SG_ LRRF1_CAN_SENSOR_TIME_STAMP : 7|32@0+ (1,0) [0|4294967295] "us"  CADM

BO_ 68 LRRF1_Status_Temp_Volt: 12 LRRF
 SG_ LRRF1_CAN_Dolphin_AFC : 87|8@0+ (1,-50) [-50|205] "C"  CADM,External_Tool
 SG_ LRRF1_CAN_Dolphin_Tx3 : 79|8@0+ (1,-50) [-50|205] "C"  CADM,External_Tool
 SG_ LRRF1_CAN_Dolphin_Tx2 : 71|8@0+ (1,-50) [-50|205] "C"  CADM,External_Tool
 SG_ LRRF1_CAN_1_8_V : 23|8@0+ (0.08,0) [0|20.4] "V"  External_Tool
 SG_ LRRF1_CAN_BATT_VOLTS : 63|8@0+ (0.08,0) [0|20.4] "V"  External_Tool
 SG_ LRRF1_CAN_1_25_V : 55|8@0+ (0.08,0) [0|20.4] "V"  External_Tool
 SG_ LRRF1_CAN_5_V : 47|8@0+ (0.08,0) [0|20.4] "V"  External_Tool
 SG_ LRRF1_CAN_1_1_V : 31|8@0+ (0.08,0) [0|20.4] "V"  External_Tool
 SG_ LRRF1_CAN_2_3_V : 15|8@0+ (0.08,0) [0|20.4] "V"  External_Tool
 SG_ LRRF1_CAN_Dolphin_Tx1 : 39|8@0+ (1,-50) [-50|205] "C"  CADM,External_Tool
 SG_ LRRF1_CAN_RRU_Temp1 : 7|8@0+ (1,-50) [-50|205] "C"  CADM,External_Tool

BO_ 92 LRRF1_Detection_127_128: 20 LRRF
 SG_ LRRF1_CAN_DET_Near_TARGET_128 : 129|1@0+ (1,0) [0|1] ""  CADM
 SG_ LRRF1_CAN_DET_Near_TARGET_127 : 128|1@0+ (1,0) [0|1] ""  CADM
 SG_ LRRF1_Det_CRC_19 : 151|16@0+ (1,0) [0|65535] ""  CADM
 SG_ LRRF1_Det_MC_19 : 139|4@0+ (1,0) [0|15] ""  CADM
 SG_ LRRF1_CAN_DET_ELEVATION_128 : 127|7@0+ (0.002748,-0.1745) [-0.1745|0.174496] "rad"  CADM
 SG_ LRRF1_CAN_DET_SUPER_RES_TARGET_1 : 120|1@0+ (1,0) [0|1] ""  CADM
 SG_ LRRF1_CAN_DET_AZIMUTH_128 : 111|14@0+ (0.0003834,-3.1416) [-3.1416|3.1396422] "rad"  CADM
 SG_ LRRF1_CAN_DET_HOST_VEH_CLUTTER_1 : 113|1@0+ (1,0) [0|1] ""  CADM
 SG_ LRRF1_CAN_DET_CONFID_ELEVATION_1 : 112|1@0+ (1,0) [0|1] ""  CADM
 SG_ LRRF1_CAN_DET_RANGE_128 : 95|14@0+ (0.015625,0) [0|255.984375] "m"  CADM
 SG_ LRRF1_CAN_DET_CONFID_AZIMUTH_128 : 97|2@0+ (1,0) [0|3] ""  CADM
 SG_ LRRF1_CAN_DET_RANGE_RATE_128 : 79|14@0+ (0.015625,-128) [-128|127.984375] "m/s"  CADM
 SG_ LRRF1_CAN_SCAN_INDEX_2LSB_128 : 81|2@0+ (1,0) [0|3] ""  CADM
 SG_ LRRF1_CAN_DET_AMPLITUDE_128 : 71|7@0+ (1,-64) [-64|63] "dBsm"  CADM
 SG_ LRRF1_CAN_DET_VALID_LEVEL_128 : 64|1@0+ (1,0) [0|1] ""  CADM
 SG_ LRRF1_CAN_DET_ELEVATION_127 : 63|7@0+ (0.002748,-0.1745) [-0.1745|0.174496] "rad"  CADM
 SG_ LRRF1_CAN_DET_CONFID_AZIMUTH_127 : 33|2@0+ (1,0) [0|3] ""  CADM
 SG_ LRRF1_CAN_DET_SUPER_RES_TAR_0006 : 56|1@0+ (1,0) [0|1] ""  CADM
 SG_ LRRF1_CAN_DET_CONFID_ELEVAT_0006 : 48|1@0+ (1,0) [0|1] ""  CADM
 SG_ LRRF1_CAN_DET_HOST_VEH_CLUT_0006 : 49|1@0+ (1,0) [0|1] ""  CADM
 SG_ LRRF1_CAN_DET_VALID_LEVEL_127 : 0|1@0+ (1,0) [0|1] ""  CADM
 SG_ LRRF1_CAN_DET_AZIMUTH_127 : 47|14@0+ (0.0003834,-3.1416) [-3.1416|3.1396422] "rad"  CADM
 SG_ LRRF1_CAN_DET_RANGE_127 : 31|14@0+ (0.015625,0) [0|255.984375] "m"  CADM
 SG_ LRRF1_CAN_DET_RANGE_RATE_127 : 15|14@0+ (0.015625,-128) [-128|127.984375] "m/s"  CADM
 SG_ LRRF1_CAN_DET_AMPLITUDE_127 : 7|7@0+ (1,-64) [-64|63] "dBsm"  CADM
 SG_ LRRF1_CAN_SCAN_INDEX_2LSB_127 : 17|2@0+ (1,0) [0|3] ""  CADM

CM_ "CAN bus that communicates the Short Range Radars with CADM";
BA_DEF_ SG_  "NWM_WakeupAllowed" ENUM  "0 No","1 Yes";
BA_DEF_ BO_  "GenMsgTimeoutTime" INT 0 2500;
BA_DEF_ BO_  "WakeupMessage" ENUM  "0 No","1 Yes";
BA_DEF_ BU_  "NmNodeType" ENUM  "0 Master","1 Slave15","2 Slave30","3 None";
BA_DEF_ SG_  "SignalDescription" STRING ;
BA_DEF_ SG_  "GenSigTimeoutTime_ABS_ESC" INT 0 100000;
BA_DEF_ SG_  "UsedOnPgmDBC" ENUM  "No","Yes";
BA_DEF_ BU_  "IL" ENUM  "No","Yes";
BA_DEF_  "VersionNumber_B" STRING ;
BA_DEF_ BU_  "NodeLayerModules" STRING ;
BA_DEF_ BO_  "VFrameFormat" ENUM  "StandardCAN","ExtendedCAN","reserved","reserved","reserved","reserved","reserved","reserved","reserved","reserved","reserved","reserved","reserved","reserved","StandardCAN_FD","ExtendedCAN_FD";
BA_DEF_ BO_  "DiagConnection" INT 0 65535;
BA_DEF_ BO_  "CanTpBs" INT 0 255;
BA_DEF_ BO_  "EventRateOfChange" INT 10 10000;
BA_DEF_ BO_  "DiagState" ENUM  "No","Yes";
BA_DEF_ BO_  "DiagRequest" ENUM  "No","Yes";
BA_DEF_ BO_  "DiagResponse" ENUM  "No","Yes";
BA_DEF_ BU_  "NmNode" ENUM  "No","Yes";
BA_DEF_ BU_  "TpOwnSystemEcuNumber" HEX 0 255;
BA_DEF_  "NetworkSpeed" ENUM  "500kBits/s","125kBit/s","2MBits/s";
BA_DEF_  "NmAsrMessageCount" INT 1 256;
BA_DEF_  "NmAsrBaseAddress" HEX 1280 1343;
BA_DEF_  "VersionDay" INT 1 31;
BA_DEF_  "Manufacturer" STRING ;
BA_DEF_  "VersionMonth" INT 1 12;
BA_DEF_  "VersionYear" INT 2000 3000;
BA_DEF_ SG_  "GenSigCycleTime" INT 0 0;
BA_DEF_ SG_  "GenSigMarked" STRING ;
BA_DEF_ SG_  "GenSigVtName" STRING ;
BA_DEF_ SG_  "GenSigVtEn" STRING ;
BA_DEF_  "GenNetworkMuxEn" STRING ;
BA_DEF_  "GenNetworkBaudrate" STRING ;
BA_DEF_  "GenNetworkName" STRING ;
BA_DEF_ SG_  "GenSigCmt" STRING ;
BA_DEF_  "GenRevisionDate" STRING ;
BA_DEF_  "GenRevision" STRING ;
BA_DEF_  "GenDescription" STRING ;
BA_DEF_  "GenCompany" STRING ;
BA_DEF_  "GenAuthor" STRING ;
BA_DEF_ SG_  "GenSigSendType" ENUM  "Cyclic","OnWrite","vector_leerstring","OnChange","vector_leerstring","IfActive","vector_leerstring","NoSigSendType";
BA_DEF_ SG_  "GenSigInactiveValue" INT 0 100000;
BA_DEF_ SG_  "GenSigMissingSourceValue" INT 0 1000000000;
BA_DEF_ SG_  "GenSigStartValue" INT 0 1000000000;
BA_DEF_ BO_  "GenMsgILSupport" ENUM  "No","Yes";
BA_DEF_ BO_  "GenMsgSendType" ENUM  "FixedPeriodic","Event","EnabledPeriodic","NotUsed","NotUsed","EventPeriodic","NotUsed","NotUsed","NoMsgSendType";
BA_DEF_ BO_  "GenMsgCycleTime" INT 0 100000;
BA_DEF_ BO_  "GenMsgDelayTime" INT 0 10000;
BA_DEF_ BO_  "GenMsgNrOfRepetition" INT 0 100;
BA_DEF_ BO_  "GenMsgStartDelayTime" INT 0 10000;
BA_DEF_ BO_  "NetworkInitialization" ENUM  "No","Yes";
BA_DEF_ BU_  "PowerType" ENUM  "Switched","Latched","Sleep","vector_leerstring","vector_leerstring";
BA_DEF_ BU_  "NodeStartUpTime" INT 0 10000;
BA_DEF_ BU_  "NodeWakeUpTime" INT 0 10000;
BA_DEF_  "DBName" STRING ;
BA_DEF_  "BusType" STRING ;
BA_DEF_ SG_  "SystemSignalLongSymbol" STRING ;
BA_DEF_DEF_  "NWM_WakeupAllowed" "0 No";
BA_DEF_DEF_  "GenMsgTimeoutTime" 2500;
BA_DEF_DEF_  "WakeupMessage" "0 No";
BA_DEF_DEF_  "NmNodeType" "3 None";
BA_DEF_DEF_  "SignalDescription" "";
BA_DEF_DEF_  "GenSigTimeoutTime_ABS_ESC" 0;
BA_DEF_DEF_  "UsedOnPgmDBC" "Yes";
BA_DEF_DEF_  "IL" "Yes";
BA_DEF_DEF_  "VersionNumber_B" "B_1";
BA_DEF_DEF_  "NodeLayerModules" "CANoeILNLFiat.dll";
BA_DEF_DEF_  "VFrameFormat" "StandardCAN_FD";
BA_DEF_DEF_  "DiagConnection" 0;
BA_DEF_DEF_  "CanTpBs" 255;
BA_DEF_DEF_  "EventRateOfChange" 10000;
BA_DEF_DEF_  "DiagState" "No";
BA_DEF_DEF_  "DiagRequest" "No";
BA_DEF_DEF_  "DiagResponse" "No";
BA_DEF_DEF_  "NmNode" "Yes";
BA_DEF_DEF_  "TpOwnSystemEcuNumber" 0;
BA_DEF_DEF_  "NetworkSpeed" "2MBits/s";
BA_DEF_DEF_  "NmAsrMessageCount" 256;
BA_DEF_DEF_  "NmAsrBaseAddress" 1280;
BA_DEF_DEF_  "VersionDay" 29;
BA_DEF_DEF_  "Manufacturer" "FCA";
BA_DEF_DEF_  "VersionMonth" 6;
BA_DEF_DEF_  "VersionYear" 2020;
BA_DEF_DEF_  "GenSigCycleTime" 0;
BA_DEF_DEF_  "GenSigMarked" "";
BA_DEF_DEF_  "GenSigVtName" "";
BA_DEF_DEF_  "GenSigVtEn" "";
BA_DEF_DEF_  "GenNetworkMuxEn" "FALSE";
BA_DEF_DEF_  "GenNetworkBaudrate" "500 kbps";
BA_DEF_DEF_  "GenNetworkName" "CADM_PCAN_SB1";
BA_DEF_DEF_  "GenSigCmt" "";
BA_DEF_DEF_  "GenRevisionDate" "29th June 2020";
BA_DEF_DEF_  "GenRevision" "v07.01.00";
BA_DEF_DEF_  "GenDescription" "SB1 CAN bus that supports communication between Radars and CADM";
BA_DEF_DEF_  "GenCompany" "APTIV";
BA_DEF_DEF_  "GenAuthor" "Pradyumna Vasudevan";
BA_DEF_DEF_  "GenSigSendType" "NoSigSendType";
BA_DEF_DEF_  "GenSigInactiveValue" 0;
BA_DEF_DEF_  "GenSigMissingSourceValue" 0;
BA_DEF_DEF_  "GenSigStartValue" 0;
BA_DEF_DEF_  "GenMsgILSupport" "Yes";
BA_DEF_DEF_  "GenMsgSendType" "NoMsgSendType";
BA_DEF_DEF_  "GenMsgCycleTime" 0;
BA_DEF_DEF_  "GenMsgDelayTime" 0;
BA_DEF_DEF_  "GenMsgNrOfRepetition" 0;
BA_DEF_DEF_  "GenMsgStartDelayTime" 0;
BA_DEF_DEF_  "NetworkInitialization" "No";
BA_DEF_DEF_  "PowerType" "Switched";
BA_DEF_DEF_  "NodeStartUpTime" 250;
BA_DEF_DEF_  "NodeWakeUpTime" 10;
BA_DEF_DEF_  "DBName" "";
BA_DEF_DEF_  "BusType" "CAN FD";
BA_DEF_DEF_  "SystemSignalLongSymbol" "";
BA_ "GenAuthor" "Bipin Radadiya";
BA_ "GenCompany" "Aptiv";
BA_ "GenDescription" "The CAN that communicates  data between Corner Radars/long range Radar and CADM";
BA_ "GenNetworkBaudrate" "500000";
BA_ "GenRevisionDate" "November 3rd 2020";
BA_ "VersionDay" 3;
BA_ "VersionMonth" 11;
BA_ "GenRevision" "v07.02.00";
BA_ "DBName" "CADM_PCAN_SB1";
BA_ "GenMsgTimeoutTime" BO_ 954 0;
BA_ "GenMsgSendType" BO_ 954 0;
BA_ "GenMsgCycleTime" BO_ 954 100;
BA_ "GenMsgTimeoutTime" BO_ 1978 0;
BA_ "GenMsgSendType" BO_ 1978 0;
BA_ "GenMsgCycleTime" BO_ 1978 100;
BA_ "GenMsgTimeoutTime" BO_ 93 0;
BA_ "GenMsgCycleTime" BO_ 93 100;
BA_ "GenMsgSendType" BO_ 93 0;
BA_ "GenMsgTimeoutTime" BO_ 1698 0;
BA_ "GenMsgSendType" BO_ 1698 0;
BA_ "GenMsgCycleTime" BO_ 1698 1000;
BA_ "GenMsgTimeoutTime" BO_ 690 0;
BA_ "GenMsgSendType" BO_ 690 0;
BA_ "GenMsgCycleTime" BO_ 690 1000;
BA_ "GenMsgTimeoutTime" BO_ 94 0;
BA_ "GenMsgSendType" BO_ 94 0;
BA_ "GenMsgCycleTime" BO_ 94 1000;
BA_ "GenMsgTimeoutTime" BO_ 39 0;
BA_ "GenMsgSendType" BO_ 39 0;
BA_ "GenMsgCycleTime" BO_ 39 50;
BA_ "GenMsgTimeoutTime" BO_ 38 0;
BA_ "GenMsgSendType" BO_ 38 0;
BA_ "GenMsgCycleTime" BO_ 38 50;
BA_ "GenMsgCycleTime" BO_ 35 20;
BA_ "GenMsgSendType" BO_ 35 0;
BA_ "GenMsgTimeoutTime" BO_ 35 0;
BA_ "GenMsgTimeoutTime" BO_ 69 0;
BA_ "GenMsgSendType" BO_ 69 0;
BA_ "GenMsgCycleTime" BO_ 69 1000;
BA_ "GenMsgTimeoutTime" BO_ 1797 0;
BA_ "GenMsgSendType" BO_ 1797 0;
BA_ "GenMsgCycleTime" BO_ 1797 1000;
BA_ "GenMsgTimeoutTime" BO_ 81 0;
BA_ "GenMsgSendType" BO_ 81 1;
BA_ "GenMsgDelayTime" BO_ 81 20;
BA_ "GenMsgTimeoutTime" BO_ 117 0;
BA_ "NetworkInitialization" BO_ 117 1;
BA_ "GenMsgSendType" BO_ 117 1;
BA_ "GenMsgTimeoutTime" BO_ 126 0;
BA_ "GenMsgSendType" BO_ 126 0;
BA_ "GenMsgCycleTime" BO_ 126 1000;
BA_ "GenMsgTimeoutTime" BO_ 33 0;
BA_ "GenMsgSendType" BO_ 33 0;
BA_ "GenMsgCycleTime" BO_ 33 20;
BA_ "GenMsgTimeoutTime" BO_ 122 0;
BA_ "GenMsgSendType" BO_ 122 1;
BA_ "GenMsgTimeoutTime" BO_ 121 0;
BA_ "GenMsgSendType" BO_ 121 1;
BA_ "GenMsgTimeoutTime" BO_ 120 0;
BA_ "GenMsgSendType" BO_ 120 1;
BA_ "GenMsgTimeoutTime" BO_ 119 0;
BA_ "GenMsgSendType" BO_ 119 1;
BA_ "GenMsgTimeoutTime" BO_ 118 0;
BA_ "GenMsgSendType" BO_ 118 1;
BA_ "GenMsgTimeoutTime" BO_ 1900 0;
BA_ "DiagResponse" BO_ 1900 1;
BA_ "GenMsgSendType" BO_ 1900 1;
BA_ "GenMsgTimeoutTime" BO_ 1892 0;
BA_ "DiagRequest" BO_ 1892 1;
BA_ "GenMsgSendType" BO_ 1892 1;
BA_ "GenMsgTimeoutTime" BO_ 185 0;
BA_ "GenMsgCycleTime" BO_ 185 10;
BA_ "GenMsgSendType" BO_ 185 0;
BA_ "GenMsgTimeoutTime" BO_ 66 0;
BA_ "GenMsgCycleTime" BO_ 66 1000;
BA_ "GenMsgSendType" BO_ 66 0;
BA_ "GenMsgTimeoutTime" BO_ 12 0;
BA_ "GenMsgSendType" BO_ 12 1;
BA_ "GenMsgTimeoutTime" BO_ 67 0;
BA_ "GenMsgSendType" BO_ 67 0;
BA_ "GenMsgCycleTime" BO_ 67 1000;
BA_ "GenMsgTimeoutTime" BO_ 15 0;
BA_ "GenMsgSendType" BO_ 15 0;
BA_ "GenMsgCycleTime" BO_ 15 25;
BA_ "GenMsgTimeoutTime" BO_ 1795 0;
BA_ "GenMsgCycleTime" BO_ 1795 1000;
BA_ "GenMsgSendType" BO_ 1795 0;
BA_ "GenMsgTimeoutTime" BO_ 48 0;
BA_ "GenMsgSendType" BO_ 48 0;
BA_ "GenMsgCycleTime" BO_ 48 25;
BA_ "GenMsgTimeoutTime" BO_ 72 0;
BA_ "GenMsgSendType" BO_ 72 1;
BA_ "GenMsgTimeoutTime" BO_ 70 0;
BA_ "GenMsgSendType" BO_ 70 1;
BA_ "GenMsgTimeoutTime" BO_ 71 0;
BA_ "GenMsgSendType" BO_ 71 1;
BA_ "GenMsgTimeoutTime" BO_ 68 0;
BA_ "GenMsgCycleTime" BO_ 68 100;
BA_ "GenMsgSendType" BO_ 68 0;
BA_ "GenMsgTimeoutTime" BO_ 92 0;
BA_ "GenMsgSendType" BO_ 92 1;
BA_ "GenSigSendType" SG_ 954 MRR_RL_Radar_Reset 0;
BA_ "GenSigCycleTime" SG_ 954 MRR_RL_Radar_Reset 100;
BA_ "GenSigSendType" SG_ 1978 MRR_RR_Radar_Reset 0;
BA_ "GenSigCycleTime" SG_ 1978 MRR_RR_Radar_Reset 100;
BA_ "GenSigCycleTime" SG_ 93 LRRF1_Radar_Reset 100;
BA_ "GenSigSendType" SG_ 93 LRRF1_Radar_Reset 0;
BA_ "GenSigSendType" SG_ 1698 MRR_RR_EBOM_SW_PN_Part2 0;
BA_ "GenSigCycleTime" SG_ 1698 MRR_RR_EBOM_SW_PN_Part2 1000;
BA_ "GenSigCycleTime" SG_ 1698 MRR_RR_EBOM_SW_PN_Part1 1000;
BA_ "GenSigSendType" SG_ 1698 MRR_RR_EBOM_SW_PN_Part1 0;
BA_ "GenSigCycleTime" SG_ 1698 MRR_RR_ECU_SerialNumber_Part2 1000;
BA_ "GenSigSendType" SG_ 1698 MRR_RR_ECU_SerialNumber_Part2 0;
BA_ "GenSigCycleTime" SG_ 1698 MRR_RR_ECU_SerialNumber_Part1 1000;
BA_ "GenSigSendType" SG_ 1698 MRR_RR_ECU_SerialNumber_Part1 0;
BA_ "GenSigCycleTime" SG_ 1698 MRR_RR_EBOM_ECU_PN_Part2 1000;
BA_ "GenSigSendType" SG_ 1698 MRR_RR_EBOM_ECU_PN_Part2 0;
BA_ "GenSigCycleTime" SG_ 1698 MRR_RR_EBOM_ECU_PN_Part1 1000;
BA_ "GenSigSendType" SG_ 1698 MRR_RR_EBOM_ECU_PN_Part1 0;
BA_ "GenSigSendType" SG_ 1698 MRR_RR_SupplManuf_ECU_SW_VesrNum 0;
BA_ "GenSigCycleTime" SG_ 1698 MRR_RR_SupplManuf_ECU_SW_VesrNum 1000;
BA_ "GenSigCycleTime" SG_ 1698 MRR_RR_SupplManuf_ECU_HW_VesrNum 1000;
BA_ "GenSigSendType" SG_ 1698 MRR_RR_SupplManuf_ECU_HW_VesrNum 0;
BA_ "GenSigCycleTime" SG_ 1698 MRR_RR_SupplManuf_ECU_SW_PN_2 1000;
BA_ "GenSigSendType" SG_ 1698 MRR_RR_SupplManuf_ECU_SW_PN_2 0;
BA_ "GenSigCycleTime" SG_ 1698 MRR_RR_SupplManuf_ECU_SW_PN_1 1000;
BA_ "GenSigSendType" SG_ 1698 MRR_RR_SupplManuf_ECU_SW_PN_1 0;
BA_ "GenSigCycleTime" SG_ 1698 MRR_RR_SupplManuf_ECU_HW_PN_2 1000;
BA_ "GenSigSendType" SG_ 1698 MRR_RR_SupplManuf_ECU_HW_PN_2 0;
BA_ "GenSigCycleTime" SG_ 1698 MRR_RR_SupplManuf_ECU_HW_PN_1 1000;
BA_ "GenSigSendType" SG_ 1698 MRR_RR_SupplManuf_ECU_HW_PN_1 0;
BA_ "GenSigSendType" SG_ 690 MRR_RL_EBOM_SW_PN_Part2 0;
BA_ "GenSigCycleTime" SG_ 690 MRR_RL_EBOM_SW_PN_Part2 1000;
BA_ "GenSigCycleTime" SG_ 690 MRR_RL_EBOM_SW_PN_Part1 1000;
BA_ "GenSigSendType" SG_ 690 MRR_RL_EBOM_SW_PN_Part1 0;
BA_ "GenSigCycleTime" SG_ 690 MRR_RL_ECU_SerialNumber_Part2 1000;
BA_ "GenSigSendType" SG_ 690 MRR_RL_ECU_SerialNumber_Part2 0;
BA_ "GenSigCycleTime" SG_ 690 MRR_RL_ECU_SerialNumber_Part1 1000;
BA_ "GenSigSendType" SG_ 690 MRR_RL_ECU_SerialNumber_Part1 0;
BA_ "GenSigCycleTime" SG_ 690 MRR_RL_EBOM_ECU_PN_Part2 1000;
BA_ "GenSigSendType" SG_ 690 MRR_RL_EBOM_ECU_PN_Part2 0;
BA_ "GenSigCycleTime" SG_ 690 MRR_RL_EBOM_ECU_PN_Part1 1000;
BA_ "GenSigSendType" SG_ 690 MRR_RL_EBOM_ECU_PN_Part1 0;
BA_ "GenSigSendType" SG_ 690 MRR_RL_SupplManuf_ECU_SW_VesrNum 0;
BA_ "GenSigCycleTime" SG_ 690 MRR_RL_SupplManuf_ECU_SW_VesrNum 1000;
BA_ "GenSigCycleTime" SG_ 690 MRR_RL_SupplManuf_ECU_HW_VesrNum 1000;
BA_ "GenSigSendType" SG_ 690 MRR_RL_SupplManuf_ECU_HW_VesrNum 0;
BA_ "GenSigCycleTime" SG_ 690 MRR_RL_SupplManuf_ECU_SW_PN_2 1000;
BA_ "GenSigSendType" SG_ 690 MRR_RL_SupplManuf_ECU_SW_PN_2 0;
BA_ "GenSigCycleTime" SG_ 690 MRR_RL_SupplManuf_ECU_SW_PN_1 1000;
BA_ "GenSigSendType" SG_ 690 MRR_RL_SupplManuf_ECU_SW_PN_1 0;
BA_ "GenSigCycleTime" SG_ 690 MRR_RL_SupplManuf_ECU_HW_PN_2 1000;
BA_ "GenSigSendType" SG_ 690 MRR_RL_SupplManuf_ECU_HW_PN_2 0;
BA_ "GenSigCycleTime" SG_ 690 MRR_RL_SupplManuf_ECU_HW_PN_1 1000;
BA_ "GenSigSendType" SG_ 690 MRR_RL_SupplManuf_ECU_HW_PN_1 0;
BA_ "GenSigSendType" SG_ 94 LRRF1_EBOM_SW_PN_Part2 0;
BA_ "GenSigCycleTime" SG_ 94 LRRF1_EBOM_SW_PN_Part2 1000;
BA_ "GenSigCycleTime" SG_ 94 LRRF1_EBOM_SW_PN_Part1 1000;
BA_ "GenSigSendType" SG_ 94 LRRF1_EBOM_SW_PN_Part1 0;
BA_ "GenSigCycleTime" SG_ 94 LRRF1_ECU_SerialNumber_Part2 1000;
BA_ "GenSigSendType" SG_ 94 LRRF1_ECU_SerialNumber_Part2 0;
BA_ "GenSigCycleTime" SG_ 94 LRRF1_ECU_SerialNumber_Part1 1000;
BA_ "GenSigSendType" SG_ 94 LRRF1_ECU_SerialNumber_Part1 0;
BA_ "GenSigCycleTime" SG_ 94 LRRF1_EBOM_ECU_PN_Part2 1000;
BA_ "GenSigSendType" SG_ 94 LRRF1_EBOM_ECU_PN_Part2 0;
BA_ "GenSigCycleTime" SG_ 94 LRRF1_EBOM_ECU_PN_Part1 1000;
BA_ "GenSigSendType" SG_ 94 LRRF1_EBOM_ECU_PN_Part1 0;
BA_ "GenSigCycleTime" SG_ 94 LRRF1_SupplManuf_ECU_SW_VesrNum 1000;
BA_ "GenSigSendType" SG_ 94 LRRF1_SupplManuf_ECU_SW_VesrNum 0;
BA_ "GenSigSendType" SG_ 94 LRRF1_SupplManuf_ECU_HW_VesrNum 0;
BA_ "GenSigCycleTime" SG_ 94 LRRF1_SupplManuf_ECU_HW_VesrNum 1000;
BA_ "GenSigSendType" SG_ 94 LRRF1_SupplManuf_ECU_SW_PN_2 0;
BA_ "GenSigCycleTime" SG_ 94 LRRF1_SupplManuf_ECU_SW_PN_2 1000;
BA_ "GenSigSendType" SG_ 94 LRRF1_SupplManuf_ECU_SW_PN_1 0;
BA_ "GenSigCycleTime" SG_ 94 LRRF1_SupplManuf_ECU_SW_PN_1 1000;
BA_ "GenSigSendType" SG_ 94 LRRF1_SupplManuf_ECU_HW_PN_2 0;
BA_ "GenSigCycleTime" SG_ 94 LRRF1_SupplManuf_ECU_HW_PN_2 1000;
BA_ "GenSigSendType" SG_ 94 LRRF1_SupplManuf_ECU_HW_PN_1 0;
BA_ "GenSigCycleTime" SG_ 94 LRRF1_SupplManuf_ECU_HW_PN_1 1000;
BA_ "GenSigSendType" SG_ 39 MRR_RR_AAT_CRC 0;
BA_ "GenSigCycleTime" SG_ 39 MRR_RR_AAT_CRC 50;
BA_ "GenSigSendType" SG_ 39 MRR_RR_AAT_MC 0;
BA_ "GenSigCycleTime" SG_ 39 MRR_RR_AAT_MC 50;
BA_ "GenSigCycleTime" SG_ 39 MRR_RR_POS_80 50;
BA_ "GenSigSendType" SG_ 39 MRR_RR_POS_80 0;
BA_ "GenSigCycleTime" SG_ 39 MRR_RR_POS_70 50;
BA_ "GenSigSendType" SG_ 39 MRR_RR_POS_70 0;
BA_ "GenSigCycleTime" SG_ 39 MRR_RR_POS_60 50;
BA_ "GenSigSendType" SG_ 39 MRR_RR_POS_60 0;
BA_ "GenSigCycleTime" SG_ 39 MRR_RR_POS_50 50;
BA_ "GenSigSendType" SG_ 39 MRR_RR_POS_50 0;
BA_ "GenSigCycleTime" SG_ 39 MRR_RR_POS_40 50;
BA_ "GenSigSendType" SG_ 39 MRR_RR_POS_40 0;
BA_ "GenSigCycleTime" SG_ 39 MRR_RR_POS_30 50;
BA_ "GenSigSendType" SG_ 39 MRR_RR_POS_30 0;
BA_ "GenSigCycleTime" SG_ 39 MRR_RR_POS_20 50;
BA_ "GenSigSendType" SG_ 39 MRR_RR_POS_20 0;
BA_ "GenSigCycleTime" SG_ 39 MRR_RR_POS_10 50;
BA_ "GenSigSendType" SG_ 39 MRR_RR_POS_10 0;
BA_ "GenSigCycleTime" SG_ 39 MRR_RR_0 50;
BA_ "GenSigSendType" SG_ 39 MRR_RR_0 0;
BA_ "GenSigCycleTime" SG_ 39 MRR_RR_NEG_10 50;
BA_ "GenSigSendType" SG_ 39 MRR_RR_NEG_10 0;
BA_ "GenSigCycleTime" SG_ 39 MRR_RR_NEG_20 50;
BA_ "GenSigSendType" SG_ 39 MRR_RR_NEG_20 0;
BA_ "GenSigCycleTime" SG_ 39 MRR_RR_NEG_30 50;
BA_ "GenSigSendType" SG_ 39 MRR_RR_NEG_30 0;
BA_ "GenSigCycleTime" SG_ 39 MRR_RR_NEG_40 50;
BA_ "GenSigSendType" SG_ 39 MRR_RR_NEG_40 0;
BA_ "GenSigCycleTime" SG_ 39 MRR_RR_NEG_50 50;
BA_ "GenSigSendType" SG_ 39 MRR_RR_NEG_50 0;
BA_ "GenSigCycleTime" SG_ 39 MRR_RR_NEG_60 50;
BA_ "GenSigSendType" SG_ 39 MRR_RR_NEG_60 0;
BA_ "GenSigCycleTime" SG_ 39 MRR_RR_NEG_70 50;
BA_ "GenSigSendType" SG_ 39 MRR_RR_NEG_70 0;
BA_ "GenSigCycleTime" SG_ 39 MRR_RR_NEG_80 50;
BA_ "GenSigSendType" SG_ 39 MRR_RR_NEG_80 0;
BA_ "GenSigSendType" SG_ 38 MRR_RL_AAT_CRC 0;
BA_ "GenSigCycleTime" SG_ 38 MRR_RL_AAT_CRC 50;
BA_ "GenSigSendType" SG_ 38 MRR_RL_AAT_MC 0;
BA_ "GenSigCycleTime" SG_ 38 MRR_RL_AAT_MC 50;
BA_ "GenSigCycleTime" SG_ 38 MRR_RL_POS_80 50;
BA_ "GenSigSendType" SG_ 38 MRR_RL_POS_80 0;
BA_ "GenSigCycleTime" SG_ 38 MRR_RL_POS_70 50;
BA_ "GenSigSendType" SG_ 38 MRR_RL_POS_70 0;
BA_ "GenSigCycleTime" SG_ 38 MRR_RL_POS_60 50;
BA_ "GenSigSendType" SG_ 38 MRR_RL_POS_60 0;
BA_ "GenSigCycleTime" SG_ 38 MRR_RL_POS_50 50;
BA_ "GenSigSendType" SG_ 38 MRR_RL_POS_50 0;
BA_ "GenSigCycleTime" SG_ 38 MRR_RL_POS_40 50;
BA_ "GenSigSendType" SG_ 38 MRR_RL_POS_40 0;
BA_ "GenSigCycleTime" SG_ 38 MRR_RL_POS_30 50;
BA_ "GenSigSendType" SG_ 38 MRR_RL_POS_30 0;
BA_ "GenSigCycleTime" SG_ 38 MRR_RL_POS_20 50;
BA_ "GenSigSendType" SG_ 38 MRR_RL_POS_20 0;
BA_ "GenSigCycleTime" SG_ 38 MRR_RL_POS_10 50;
BA_ "GenSigSendType" SG_ 38 MRR_RL_POS_10 0;
BA_ "GenSigCycleTime" SG_ 38 MRR_RL_0 50;
BA_ "GenSigSendType" SG_ 38 MRR_RL_0 0;
BA_ "GenSigCycleTime" SG_ 38 MRR_RL_NEG_10 50;
BA_ "GenSigSendType" SG_ 38 MRR_RL_NEG_10 0;
BA_ "GenSigCycleTime" SG_ 38 MRR_RL_NEG_20 50;
BA_ "GenSigSendType" SG_ 38 MRR_RL_NEG_20 0;
BA_ "GenSigCycleTime" SG_ 38 MRR_RL_NEG_30 50;
BA_ "GenSigSendType" SG_ 38 MRR_RL_NEG_30 0;
BA_ "GenSigCycleTime" SG_ 38 MRR_RL_NEG_40 50;
BA_ "GenSigSendType" SG_ 38 MRR_RL_NEG_40 0;
BA_ "GenSigCycleTime" SG_ 38 MRR_RL_NEG_50 50;
BA_ "GenSigSendType" SG_ 38 MRR_RL_NEG_50 0;
BA_ "GenSigCycleTime" SG_ 38 MRR_RL_NEG_60 50;
BA_ "GenSigSendType" SG_ 38 MRR_RL_NEG_60 0;
BA_ "GenSigCycleTime" SG_ 38 MRR_RL_NEG_70 50;
BA_ "GenSigSendType" SG_ 38 MRR_RL_NEG_70 0;
BA_ "GenSigCycleTime" SG_ 38 MRR_RL_NEG_80 50;
BA_ "GenSigSendType" SG_ 38 MRR_RL_NEG_80 0;
BA_ "GenSigSendType" SG_ 35 LRRF1_XBAR_cfg_failure 0;
BA_ "GenSigCycleTime" SG_ 35 LRRF1_XBAR_cfg_failure 20;
BA_ "GenSigSendType" SG_ 35 LRRF1_Stack_OVF_fault_reason 0;
BA_ "GenSigCycleTime" SG_ 35 LRRF1_Stack_OVF_fault_reason 20;
BA_ "GenSigSendType" SG_ 35 LRRF1_App_flash_checksum_reason 0;
BA_ "GenSigCycleTime" SG_ 35 LRRF1_App_flash_checksum_reason 20;
BA_ "GenSigSendType" SG_ 35 LRRF1_KAM_fault_reason 0;
BA_ "GenSigCycleTime" SG_ 35 LRRF1_KAM_fault_reason 20;
BA_ "GenSigCycleTime" SG_ 35 LRRF1_RRU_Self_Test_Faults_reaso 20;
BA_ "GenSigSendType" SG_ 35 LRRF1_RRU_Self_Test_Faults_reaso 0;
BA_ "SystemSignalLongSymbol" SG_ 35 LRRF1_RRU_Self_Test_Faults_reaso "LRRF1_RRU_Self_Test_Faults_reason1";
BA_ "GenSigCycleTime" SG_ 35 LRRF1_RRU_Core_Faults_reason3 20;
BA_ "GenSigSendType" SG_ 35 LRRF1_RRU_Core_Faults_reason3 0;
BA_ "GenSigCycleTime" SG_ 35 LRRF1_RRU_Core_Faults_reason2 20;
BA_ "GenSigSendType" SG_ 35 LRRF1_RRU_Core_Faults_reason2 0;
BA_ "GenSigCycleTime" SG_ 35 LRRF1_RRU_Core_Faults_reason1 20;
BA_ "GenSigSendType" SG_ 35 LRRF1_RRU_Core_Faults_reason1 0;
BA_ "GenSigCycleTime" SG_ 35 LRRF1_Rx_Radar_Mount_Msg_Fault 20;
BA_ "GenSigSendType" SG_ 35 LRRF1_Rx_Radar_Mount_Msg_Fault 0;
BA_ "GenSigCycleTime" SG_ 35 LRRF1_USC_Fault_Flag 20;
BA_ "GenSigSendType" SG_ 35 LRRF1_USC_Fault_Flag 0;
BA_ "GenSigCycleTime" SG_ 35 LRRF1_SMC_Fault_Flag 20;
BA_ "GenSigSendType" SG_ 35 LRRF1_SMC_Fault_Flag 0;
BA_ "GenSigCycleTime" SG_ 35 LRRF1_Dolphin_Fault_Detection 20;
BA_ "GenSigSendType" SG_ 35 LRRF1_Dolphin_Fault_Detection 0;
BA_ "GenSigCycleTime" SG_ 35 LRRF1_RRU_Self_Test_Faults__0000 20;
BA_ "GenSigSendType" SG_ 35 LRRF1_RRU_Self_Test_Faults__0000 0;
BA_ "SystemSignalLongSymbol" SG_ 35 LRRF1_RRU_Self_Test_Faults__0000 "LRRF1_RRU_Self_Test_Faults_reason0";
BA_ "GenSigCycleTime" SG_ 35 LRRF1_RRU_Core_Faults_reason0 20;
BA_ "GenSigSendType" SG_ 35 LRRF1_RRU_Core_Faults_reason0 0;
BA_ "GenSigSendType" SG_ 69 LRRF1_CAN_TX_HW_VERSION 0;
BA_ "GenSigCycleTime" SG_ 69 LRRF1_CAN_TX_HW_VERSION 1000;
BA_ "GenSigCycleTime" SG_ 69 LRRF1_Dolphin_Chip_ID_Part2 1000;
BA_ "GenSigSendType" SG_ 69 LRRF1_Dolphin_Chip_ID_Part2 0;
BA_ "GenSigCycleTime" SG_ 69 LRRF1_Dolphin_Chip_ID_Part1 1000;
BA_ "GenSigSendType" SG_ 69 LRRF1_Dolphin_Chip_ID_Part1 0;
BA_ "GenSigCycleTime" SG_ 69 LRRF1_RRU_Chip_ID_Part4 1000;
BA_ "GenSigSendType" SG_ 69 LRRF1_RRU_Chip_ID_Part4 0;
BA_ "GenSigCycleTime" SG_ 69 LRRF1_RRU_Chip_ID_Part3 1000;
BA_ "GenSigSendType" SG_ 69 LRRF1_RRU_Chip_ID_Part3 0;
BA_ "GenSigCycleTime" SG_ 69 LRRF1_RRU_Chip_ID_Part2 1000;
BA_ "GenSigSendType" SG_ 69 LRRF1_RRU_Chip_ID_Part2 0;
BA_ "GenSigCycleTime" SG_ 69 LRRF1_RRU_Chip_ID_Part1 1000;
BA_ "GenSigSendType" SG_ 69 LRRF1_RRU_Chip_ID_Part1 0;
BA_ "GenSigSendType" SG_ 1797 LRRF1_FA_HorizMisalignLim 0;
BA_ "GenSigCycleTime" SG_ 1797 LRRF1_FA_HorizMisalignLim 1000;
BA_ "SignalDescription" SG_ 1797 LRRF1_FA_HorizMisalignLim "Horizontal Misalignment Limit for Factory Alignment";
BA_ "GenSigSendType" SG_ 1797 LRRF1_FA_TstTolerancePlateAngPos 0;
BA_ "GenSigCycleTime" SG_ 1797 LRRF1_FA_TstTolerancePlateAngPos 1000;
BA_ "SignalDescription" SG_ 1797 LRRF1_FA_TstTolerancePlateAngPos "RCS Gain Test Tolerance for Positive angle of the Plate";
BA_ "GenSigSendType" SG_ 1797 LRRF1_FA_TstTolerancePlateAng0 0;
BA_ "GenSigCycleTime" SG_ 1797 LRRF1_FA_TstTolerancePlateAng0 1000;
BA_ "SignalDescription" SG_ 1797 LRRF1_FA_TstTolerancePlateAng0 "RCS Gain Test Tolerance for Zero angle of the Plate";
BA_ "GenSigSendType" SG_ 1797 LRRF1_FA_TstTolerancePlateAngNeg 0;
BA_ "GenSigCycleTime" SG_ 1797 LRRF1_FA_TstTolerancePlateAngNeg 1000;
BA_ "SignalDescription" SG_ 1797 LRRF1_FA_TstTolerancePlateAngNeg "RCS Gain Test Tolerance for Negative angle of the Plate";
BA_ "GenSigCycleTime" SG_ 1797 LRRF1_FA_Negative_Angle 1000;
BA_ "GenSigSendType" SG_ 1797 LRRF1_FA_Negative_Angle 0;
BA_ "GenSigStartValue" SG_ 1797 LRRF1_FA_Negative_Angle 40;
BA_ "SignalDescription" SG_ 1797 LRRF1_FA_Negative_Angle "Factory Alignment Negative Angle of Plate";
BA_ "GenSigCycleTime" SG_ 1797 LRRF1_FA_Positive_Angle 1000;
BA_ "GenSigSendType" SG_ 1797 LRRF1_FA_Positive_Angle 0;
BA_ "SignalDescription" SG_ 1797 LRRF1_FA_Positive_Angle "Factory Alignment Positive Angle of Plate";
BA_ "GenSigCycleTime" SG_ 1797 LRRF1_FA_Target_Range2Mirror 1000;
BA_ "GenSigSendType" SG_ 1797 LRRF1_FA_Target_Range2Mirror 0;
BA_ "SignalDescription" SG_ 1797 LRRF1_FA_Target_Range2Mirror "Factory Alignment Target to Mirror Distance";
BA_ "GenSigCycleTime" SG_ 1797 LRRF1_FA_Bdgt_Fascia_Attenuation 1000;
BA_ "GenSigSendType" SG_ 1797 LRRF1_FA_Bdgt_Fascia_Attenuation 0;
BA_ "SignalDescription" SG_ 1797 LRRF1_FA_Bdgt_Fascia_Attenuation "Factory Alignment Budgeted Fascia Attenuation";
BA_ "GenSigStartValue" SG_ 1797 LRRF1_FA_Bdgt_Fascia_Attenuation 50;
BA_ "GenSigCycleTime" SG_ 1797 LRRF1_Radar_CfgType 1000;
BA_ "GenSigSendType" SG_ 1797 LRRF1_Radar_CfgType 0;
BA_ "GenSigSendType" SG_ 1797 SensorCfg_LRRF_AlignRngTolVert 0;
BA_ "GenSigCycleTime" SG_ 1797 SensorCfg_LRRF_AlignRngTolVert 1000;
BA_ "GenSigSendType" SG_ 1797 SensorCfg_LRRF_AlignRngTolHorz 0;
BA_ "GenSigCycleTime" SG_ 1797 SensorCfg_LRRF_AlignRngTolHorz 1000;
BA_ "GenSigCycleTime" SG_ 1797 LRRF1_SENSR_CFG_CRC 1000;
BA_ "GenSigSendType" SG_ 1797 LRRF1_SENSR_CFG_CRC 0;
BA_ "SignalDescription" SG_ 1797 LRRF1_SENSR_CFG_CRC "Cyclic Redundancy Check for Detection Message Number 1";
BA_ "GenSigCycleTime" SG_ 1797 SensorCfg_LRRF_LatPos 1000;
BA_ "GenSigSendType" SG_ 1797 SensorCfg_LRRF_LatPos 0;
BA_ "GenSigCycleTime" SG_ 1797 SensorCfg_LRRF_LongPos 1000;
BA_ "GenSigSendType" SG_ 1797 SensorCfg_LRRF_LongPos 0;
BA_ "GenSigCycleTime" SG_ 1797 SensorCfg_LRRF_VertPos 1000;
BA_ "GenSigSendType" SG_ 1797 SensorCfg_LRRF_VertPos 0;
BA_ "GenSigCycleTime" SG_ 1797 SensorCfg_LRRF_Pitch 1000;
BA_ "GenSigSendType" SG_ 1797 SensorCfg_LRRF_Pitch 0;
BA_ "GenSigCycleTime" SG_ 1797 SensorCfg_LRRF_Yaw 1000;
BA_ "GenSigSendType" SG_ 1797 SensorCfg_LRRF_Yaw 0;
BA_ "GenSigCycleTime" SG_ 1797 SensorCfg_LRRF_Orientation 1000;
BA_ "GenSigSendType" SG_ 1797 SensorCfg_LRRF_Orientation 0;
BA_ "GenSigSendType" SG_ 81 LRRF1_CAN_DET_Near_TARGET_56 1;
BA_ "SignalDescription" SG_ 81 LRRF1_CAN_DET_Near_TARGET_56 "Near_Target_Discrimination";
BA_ "SignalDescription" SG_ 81 LRRF1_CAN_DET_Near_TARGET_55 "Near_Target_Discrimination";
BA_ "SignalDescription" SG_ 81 LRRF1_CAN_DET_Near_TARGET_54 "Near_Target_Discrimination";
BA_ "SignalDescription" SG_ 81 LRRF1_CAN_DET_Near_TARGET_53 "Near_Target_Discrimination";
BA_ "SignalDescription" SG_ 81 LRRF1_CAN_DET_Near_TARGET_52 "Near_Target_Discrimination";
BA_ "SignalDescription" SG_ 81 LRRF1_CAN_DET_Near_TARGET_51 "Near_Target_Discrimination";
BA_ "SignalDescription" SG_ 81 LRRF1_CAN_DET_Near_TARGET_50 "Near_Target_Discrimination";
BA_ "SignalDescription" SG_ 81 LRRF1_CAN_DET_VALID_LEVEL_51 "Detected object valid level 51";
BA_ "SignalDescription" SG_ 81 LRRF1_CAN_DET_VALID_LEVEL_52 "Detected object valid level 52";
BA_ "SignalDescription" SG_ 81 LRRF1_CAN_DET_VALID_LEVEL_53 "Detected object valid level 53";
BA_ "SignalDescription" SG_ 81 LRRF1_CAN_DET_VALID_LEVEL_54 "Detected object valid level 54";
BA_ "SignalDescription" SG_ 81 LRRF1_CAN_DET_VALID_LEVEL_55 "Detected object valid level 55";
BA_ "SignalDescription" SG_ 81 LRRF1_CAN_DET_VALID_LEVEL_56 "Detected object valid level 56";
BA_ "SignalDescription" SG_ 81 LRRF1_CAN_DET_AMPLITUDE_51 "Detected object amplitude 51";
BA_ "SignalDescription" SG_ 81 LRRF1_CAN_DET_AMPLITUDE_52 "Detected object amplitude 52";
BA_ "SignalDescription" SG_ 81 LRRF1_CAN_DET_AMPLITUDE_53 "Detected object amplitude 53";
BA_ "SignalDescription" SG_ 81 LRRF1_CAN_DET_AMPLITUDE_54 "Detected object amplitude 54";
BA_ "SignalDescription" SG_ 81 LRRF1_CAN_DET_AMPLITUDE_55 "Detected object amplitude 55";
BA_ "SignalDescription" SG_ 81 LRRF1_CAN_DET_AMPLITUDE_56 "Detected object amplitude 56";
BA_ "GenSigStartValue" SG_ 81 LRRF1_CAN_DET_AZIMUTH_51 8194.05320813772;
BA_ "SignalDescription" SG_ 81 LRRF1_CAN_DET_AZIMUTH_51 "Detected object azimuth position 51";
BA_ "GenSigStartValue" SG_ 81 LRRF1_CAN_DET_AZIMUTH_52 8194.05320813772;
BA_ "SignalDescription" SG_ 81 LRRF1_CAN_DET_AZIMUTH_52 "Detected object azimuth position 52";
BA_ "GenSigStartValue" SG_ 81 LRRF1_CAN_DET_AZIMUTH_53 8194.05320813772;
BA_ "SignalDescription" SG_ 81 LRRF1_CAN_DET_AZIMUTH_53 "Detected object azimuth position 53";
BA_ "GenSigStartValue" SG_ 81 LRRF1_CAN_DET_AZIMUTH_54 8194.05320813772;
BA_ "SignalDescription" SG_ 81 LRRF1_CAN_DET_AZIMUTH_54 "Detected object azimuth position 54";
BA_ "GenSigStartValue" SG_ 81 LRRF1_CAN_DET_AZIMUTH_55 8194.05320813772;
BA_ "SignalDescription" SG_ 81 LRRF1_CAN_DET_AZIMUTH_55 "Detected object azimuth position 55";
BA_ "GenSigStartValue" SG_ 81 LRRF1_CAN_DET_AZIMUTH_56 8194.05320813772;
BA_ "SignalDescription" SG_ 81 LRRF1_CAN_DET_AZIMUTH_56 "Detected object azimuth position 56";
BA_ "GenSigVtEn" SG_ 81 LRRF1_CAN_DET_CONFID_AZIMUTH_51 "TRUE";
BA_ "SignalDescription" SG_ 81 LRRF1_CAN_DET_CONFID_AZIMUTH_51 "Signal to noise level 51";
BA_ "GenSigVtEn" SG_ 81 LRRF1_CAN_DET_CONFID_AZIMUTH_52 "TRUE";
BA_ "SignalDescription" SG_ 81 LRRF1_CAN_DET_CONFID_AZIMUTH_52 "Signal to noise level 52";
BA_ "GenSigVtEn" SG_ 81 LRRF1_CAN_DET_CONFID_AZIMUTH_53 "TRUE";
BA_ "SignalDescription" SG_ 81 LRRF1_CAN_DET_CONFID_AZIMUTH_53 "Signal to noise level 53";
BA_ "GenSigVtEn" SG_ 81 LRRF1_CAN_DET_CONFID_AZIMUTH_54 "TRUE";
BA_ "SignalDescription" SG_ 81 LRRF1_CAN_DET_CONFID_AZIMUTH_54 "Signal to noise level 54";
BA_ "GenSigVtEn" SG_ 81 LRRF1_CAN_DET_CONFID_AZIMUTH_55 "TRUE";
BA_ "SignalDescription" SG_ 81 LRRF1_CAN_DET_CONFID_AZIMUTH_55 "Signal to noise level 55";
BA_ "GenSigVtEn" SG_ 81 LRRF1_CAN_DET_CONFID_AZIMUTH_56 "TRUE";
BA_ "SignalDescription" SG_ 81 LRRF1_CAN_DET_CONFID_AZIMUTH_56 "Signal to noise level 56";
BA_ "SignalDescription" SG_ 81 LRRF1_CAN_DET_CONFID_ELEVATION_5 "Elevation Angle Confidence 51";
BA_ "SystemSignalLongSymbol" SG_ 81 LRRF1_CAN_DET_CONFID_ELEVATION_5 "LRRF1_CAN_DET_CONFID_ELEVATION_51";
BA_ "SignalDescription" SG_ 81 LRRF1_CAN_DET_CONFID_ELEVAT_0000 "Elevation Angle Confidence 52";
BA_ "SystemSignalLongSymbol" SG_ 81 LRRF1_CAN_DET_CONFID_ELEVAT_0000 "LRRF1_CAN_DET_CONFID_ELEVATION_52";
BA_ "SignalDescription" SG_ 81 LRRF1_CAN_DET_CONFID_ELEVAT_0001 "Elevation Angle Confidence 53";
BA_ "SystemSignalLongSymbol" SG_ 81 LRRF1_CAN_DET_CONFID_ELEVAT_0001 "LRRF1_CAN_DET_CONFID_ELEVATION_53";
BA_ "SignalDescription" SG_ 81 LRRF1_CAN_DET_CONFID_ELEVAT_0002 "Elevation Angle Confidence 54";
BA_ "SystemSignalLongSymbol" SG_ 81 LRRF1_CAN_DET_CONFID_ELEVAT_0002 "LRRF1_CAN_DET_CONFID_ELEVATION_54";
BA_ "SignalDescription" SG_ 81 LRRF1_CAN_DET_CONFID_ELEVAT_0003 "Elevation Angle Confidence 55";
BA_ "SystemSignalLongSymbol" SG_ 81 LRRF1_CAN_DET_CONFID_ELEVAT_0003 "LRRF1_CAN_DET_CONFID_ELEVATION_55";
BA_ "SignalDescription" SG_ 81 LRRF1_CAN_DET_CONFID_ELEVAT_0004 "Elevation Angle Confidence 56";
BA_ "SystemSignalLongSymbol" SG_ 81 LRRF1_CAN_DET_CONFID_ELEVAT_0004 "LRRF1_CAN_DET_CONFID_ELEVATION_56";
BA_ "GenSigStartValue" SG_ 81 LRRF1_CAN_DET_ELEVATION_51 63.8646288209607;
BA_ "SignalDescription" SG_ 81 LRRF1_CAN_DET_ELEVATION_51 "Detected object elevation position 51";
BA_ "GenSigStartValue" SG_ 81 LRRF1_CAN_DET_ELEVATION_52 63.8646288209607;
BA_ "SignalDescription" SG_ 81 LRRF1_CAN_DET_ELEVATION_52 "Detected object elevation position 52";
BA_ "GenSigStartValue" SG_ 81 LRRF1_CAN_DET_ELEVATION_53 63.8646288209607;
BA_ "SignalDescription" SG_ 81 LRRF1_CAN_DET_ELEVATION_53 "Detected object elevation position 53";
BA_ "GenSigStartValue" SG_ 81 LRRF1_CAN_DET_ELEVATION_54 63.8646288209607;
BA_ "SignalDescription" SG_ 81 LRRF1_CAN_DET_ELEVATION_54 "Detected object elevation position 54";
BA_ "GenSigStartValue" SG_ 81 LRRF1_CAN_DET_ELEVATION_55 63.8646288209607;
BA_ "SignalDescription" SG_ 81 LRRF1_CAN_DET_ELEVATION_55 "Detected object elevation position 55";
BA_ "SignalDescription" SG_ 81 LRRF1_CAN_DET_ELEVATION_56 "Detected object elevation position 56";
BA_ "GenSigStartValue" SG_ 81 LRRF1_CAN_DET_ELEVATION_56 63.8646288209607;
BA_ "SignalDescription" SG_ 81 LRRF1_CAN_DET_HOST_VEH_CLUTTER_5 "Host vehicle clutter 51";
BA_ "SystemSignalLongSymbol" SG_ 81 LRRF1_CAN_DET_HOST_VEH_CLUTTER_5 "LRRF1_CAN_DET_HOST_VEH_CLUTTER_51";
BA_ "SignalDescription" SG_ 81 LRRF1_CAN_DET_HOST_VEH_CLUT_0000 "Host vehicle clutter 52";
BA_ "SystemSignalLongSymbol" SG_ 81 LRRF1_CAN_DET_HOST_VEH_CLUT_0000 "LRRF1_CAN_DET_HOST_VEH_CLUTTER_52";
BA_ "SignalDescription" SG_ 81 LRRF1_CAN_DET_HOST_VEH_CLUT_0001 "Host vehicle clutter 53";
BA_ "SystemSignalLongSymbol" SG_ 81 LRRF1_CAN_DET_HOST_VEH_CLUT_0001 "LRRF1_CAN_DET_HOST_VEH_CLUTTER_53";
BA_ "SignalDescription" SG_ 81 LRRF1_CAN_DET_HOST_VEH_CLUT_0002 "Host vehicle clutter 54";
BA_ "SystemSignalLongSymbol" SG_ 81 LRRF1_CAN_DET_HOST_VEH_CLUT_0002 "LRRF1_CAN_DET_HOST_VEH_CLUTTER_54";
BA_ "SignalDescription" SG_ 81 LRRF1_CAN_DET_HOST_VEH_CLUT_0003 "Host vehicle clutter 55";
BA_ "SystemSignalLongSymbol" SG_ 81 LRRF1_CAN_DET_HOST_VEH_CLUT_0003 "LRRF1_CAN_DET_HOST_VEH_CLUTTER_55";
BA_ "SignalDescription" SG_ 81 LRRF1_CAN_DET_HOST_VEH_CLUT_0004 "Host vehicle clutter 56";
BA_ "SystemSignalLongSymbol" SG_ 81 LRRF1_CAN_DET_HOST_VEH_CLUT_0004 "LRRF1_CAN_DET_HOST_VEH_CLUTTER_56";
BA_ "SignalDescription" SG_ 81 LRRF1_CAN_DET_SUPER_RES_TARGET_5 "Super resolution target 51";
BA_ "SystemSignalLongSymbol" SG_ 81 LRRF1_CAN_DET_SUPER_RES_TARGET_5 "LRRF1_CAN_DET_SUPER_RES_TARGET_51";
BA_ "SignalDescription" SG_ 81 LRRF1_CAN_DET_SUPER_RES_TAR_0000 "Super resolution target 52";
BA_ "SystemSignalLongSymbol" SG_ 81 LRRF1_CAN_DET_SUPER_RES_TAR_0000 "LRRF1_CAN_DET_SUPER_RES_TARGET_52";
BA_ "SignalDescription" SG_ 81 LRRF1_CAN_DET_SUPER_RES_TAR_0001 "Super resolution target 53";
BA_ "SystemSignalLongSymbol" SG_ 81 LRRF1_CAN_DET_SUPER_RES_TAR_0001 "LRRF1_CAN_DET_SUPER_RES_TARGET_53";
BA_ "SignalDescription" SG_ 81 LRRF1_CAN_DET_SUPER_RES_TAR_0002 "Super resolution target 54";
BA_ "SystemSignalLongSymbol" SG_ 81 LRRF1_CAN_DET_SUPER_RES_TAR_0002 "LRRF1_CAN_DET_SUPER_RES_TARGET_54";
BA_ "SignalDescription" SG_ 81 LRRF1_CAN_DET_SUPER_RES_TAR_0003 "Super resolution target 55";
BA_ "SystemSignalLongSymbol" SG_ 81 LRRF1_CAN_DET_SUPER_RES_TAR_0003 "LRRF1_CAN_DET_SUPER_RES_TARGET_55";
BA_ "SignalDescription" SG_ 81 LRRF1_CAN_DET_SUPER_RES_TAR_0004 "Super resolution target 56";
BA_ "SystemSignalLongSymbol" SG_ 81 LRRF1_CAN_DET_SUPER_RES_TAR_0004 "LRRF1_CAN_DET_SUPER_RES_TARGET_56";
BA_ "SignalDescription" SG_ 81 LRRF1_CAN_DET_RANGE_51 "Detected object range 51";
BA_ "SignalDescription" SG_ 81 LRRF1_CAN_DET_RANGE_52 "Detected object range 52";
BA_ "SignalDescription" SG_ 81 LRRF1_CAN_DET_RANGE_53 "Detected object range 53";
BA_ "SignalDescription" SG_ 81 LRRF1_CAN_DET_RANGE_54 "Detected object range 54";
BA_ "SignalDescription" SG_ 81 LRRF1_CAN_DET_RANGE_55 "Detected object range 55";
BA_ "SignalDescription" SG_ 81 LRRF1_CAN_DET_RANGE_56 "Detected object range 56";
BA_ "GenSigStartValue" SG_ 81 LRRF1_CAN_DET_RANGE_RATE_51 8192;
BA_ "SignalDescription" SG_ 81 LRRF1_CAN_DET_RANGE_RATE_51 "Detected object range rate 51";
BA_ "GenSigStartValue" SG_ 81 LRRF1_CAN_DET_RANGE_RATE_52 8192;
BA_ "SignalDescription" SG_ 81 LRRF1_CAN_DET_RANGE_RATE_52 "Detected object range rate 52";
BA_ "GenSigStartValue" SG_ 81 LRRF1_CAN_DET_RANGE_RATE_53 8192;
BA_ "SignalDescription" SG_ 81 LRRF1_CAN_DET_RANGE_RATE_53 "Detected object range rate 53";
BA_ "GenSigStartValue" SG_ 81 LRRF1_CAN_DET_RANGE_RATE_54 8192;
BA_ "SignalDescription" SG_ 81 LRRF1_CAN_DET_RANGE_RATE_54 "Detected object range rate 54";
BA_ "GenSigStartValue" SG_ 81 LRRF1_CAN_DET_RANGE_RATE_55 8192;
BA_ "SignalDescription" SG_ 81 LRRF1_CAN_DET_RANGE_RATE_55 "Detected object range rate 55";
BA_ "GenSigStartValue" SG_ 81 LRRF1_CAN_DET_RANGE_RATE_56 8192;
BA_ "SignalDescription" SG_ 81 LRRF1_CAN_DET_RANGE_RATE_56 "Detected object range rate 56";
BA_ "SignalDescription" SG_ 81 LRRF1_CAN_SCAN_INDEX_2LSB_51 "The two LSB of scan index 51";
BA_ "SignalDescription" SG_ 81 LRRF1_CAN_SCAN_INDEX_2LSB_52 "The two LSB of scan index 52";
BA_ "SignalDescription" SG_ 81 LRRF1_CAN_SCAN_INDEX_2LSB_53 "The two LSB of scan index 53";
BA_ "SignalDescription" SG_ 81 LRRF1_CAN_SCAN_INDEX_2LSB_54 "The two LSB of scan index 54";
BA_ "SignalDescription" SG_ 81 LRRF1_CAN_SCAN_INDEX_2LSB_55 "The two LSB of scan index 55";
BA_ "SignalDescription" SG_ 81 LRRF1_CAN_SCAN_INDEX_2LSB_56 "The two LSB of scan index 56";
BA_ "SignalDescription" SG_ 81 LRRF1_Det_MC_08 "Message Count for Detection Message Number 8";
BA_ "SignalDescription" SG_ 81 LRRF1_Det_CRC_08 "Cyclic Redundancy Check for Detection Message Number 8";
BA_ "SignalDescription" SG_ 81 LRRF1_CAN_SCAN_INDEX_2LSB_50 "The two LSB of scan index 50";
BA_ "SignalDescription" SG_ 81 LRRF1_CAN_DET_AMPLITUDE_50 "Detected object amplitude 50";
BA_ "GenSigStartValue" SG_ 81 LRRF1_CAN_DET_RANGE_RATE_50 8192;
BA_ "SignalDescription" SG_ 81 LRRF1_CAN_DET_RANGE_RATE_50 "Detected object range rate 50";
BA_ "SignalDescription" SG_ 81 LRRF1_CAN_DET_RANGE_50 "Detected object range 50";
BA_ "GenSigStartValue" SG_ 81 LRRF1_CAN_DET_AZIMUTH_50 8194.05320813772;
BA_ "SignalDescription" SG_ 81 LRRF1_CAN_DET_AZIMUTH_50 "Detected object azimuth position 50";
BA_ "SignalDescription" SG_ 81 LRRF1_CAN_DET_VALID_LEVEL_50 "Detected object valid level 50";
BA_ "SignalDescription" SG_ 81 LRRF1_CAN_DET_HOST_VEH_CLUT_0005 "Host vehicle clutter 50";
BA_ "SystemSignalLongSymbol" SG_ 81 LRRF1_CAN_DET_HOST_VEH_CLUT_0005 "LRRF1_CAN_DET_HOST_VEH_CLUTTER_50";
BA_ "SignalDescription" SG_ 81 LRRF1_CAN_DET_CONFID_ELEVAT_0005 "Elevation Angle Confidence 50";
BA_ "SystemSignalLongSymbol" SG_ 81 LRRF1_CAN_DET_CONFID_ELEVAT_0005 "LRRF1_CAN_DET_CONFID_ELEVATION_50";
BA_ "SignalDescription" SG_ 81 LRRF1_CAN_DET_SUPER_RES_TAR_0005 "Super resolution target 50";
BA_ "SystemSignalLongSymbol" SG_ 81 LRRF1_CAN_DET_SUPER_RES_TAR_0005 "LRRF1_CAN_DET_SUPER_RES_TARGET_50";
BA_ "GenSigVtEn" SG_ 81 LRRF1_CAN_DET_CONFID_AZIMUTH_50 "TRUE";
BA_ "SignalDescription" SG_ 81 LRRF1_CAN_DET_CONFID_AZIMUTH_50 "Signal to noise level 50";
BA_ "GenSigStartValue" SG_ 81 LRRF1_CAN_DET_ELEVATION_50 63.8646288209607;
BA_ "SignalDescription" SG_ 81 LRRF1_CAN_DET_ELEVATION_50 "Detected object elevation position 50";
BA_ "GenSigSendType" SG_ 117 LRRF1_CAN_VEHICLE_SPEED_CALC_QF_ 1;
BA_ "SystemSignalLongSymbol" SG_ 117 LRRF1_CAN_VEHICLE_SPEED_CALC_QF_ "LRRF1_CAN_VEHICLE_SPEED_CALC_QF_ECHO";
BA_ "SignalDescription" SG_ 117 LRRF1_CAN_YAW_RATE_CALC_ECHO "Vehicle Yaw Rate Echo";
BA_ "GenSigStartValue" SG_ 117 LRRF1_CAN_YAW_RATE_CALC_ECHO 3200;
BA_ "SignalDescription" SG_ 117 LRRF1_CAN_VEHICLE_SPEED_CALC_ECH "Vehcile Speed Echo";
BA_ "SystemSignalLongSymbol" SG_ 117 LRRF1_CAN_VEHICLE_SPEED_CALC_ECH "LRRF1_CAN_VEHICLE_SPEED_CALC_ECHO";
BA_ "SystemSignalLongSymbol" SG_ 117 LRRF1_CAN_COMPENSATED_SIGNALS_US "LRRF1_CAN_COMPENSATED_SIGNALS_USED";
BA_ "GenSigCycleTime" SG_ 126 LRRF1_f_Radar_Unreasonable 1000;
BA_ "GenSigSendType" SG_ 126 LRRF1_f_Radar_Unreasonable 0;
BA_ "GenSigVtEn" SG_ 126 LRRF1_f_Radar_Unreasonable "TRUE";
BA_ "SignalDescription" SG_ 33 LRRF2_SgnlRationalityCk_Flt "Monitors the difference in value of signals between SB1 and SB3 at a given instance of time";
BA_ "GenSigCycleTime" SG_ 33 LRRF2_SgnlRationalityCk_Flt 20;
BA_ "GenSigSendType" SG_ 33 LRRF2_SgnlRationalityCk_Flt 0;
BA_ "GenSigSendType" SG_ 33 LRRF2_PCANDataRangeChk_Flt 0;
BA_ "GenSigCycleTime" SG_ 33 LRRF2_PCANDataRangeChk_Flt 20;
BA_ "GenSigSendType" SG_ 33 LRRF2_PCANBusOff_Flt 0;
BA_ "GenSigCycleTime" SG_ 33 LRRF2_PCANBusOff_Flt 20;
BA_ "GenSigCycleTime" SG_ 33 LRRF1_TO_CADMSWVersion_Flt 20;
BA_ "GenSigSendType" SG_ 33 LRRF1_TO_CADMSWVersion_Flt 0;
BA_ "GenSigSendType" SG_ 33 LRRF2_TO_RADARCfgParameter_Flt 0;
BA_ "GenSigCycleTime" SG_ 33 LRRF2_TO_RADARCfgParameter_Flt 20;
BA_ "GenSigCycleTime" SG_ 33 LRRF1_Active_Fault_Status_CRC 20;
BA_ "GenSigSendType" SG_ 33 LRRF1_Active_Fault_Status_CRC 0;
BA_ "GenSigCycleTime" SG_ 33 LRRF1_Active_Fault_Status_MC 20;
BA_ "GenSigSendType" SG_ 33 LRRF1_Active_Fault_Status_MC 0;
BA_ "GenSigSendType" SG_ 33 LRRF2_TO_SATCADMVIN_Flt 0;
BA_ "GenSigCycleTime" SG_ 33 LRRF2_TO_SATCADMVIN_Flt 20;
BA_ "GenSigSendType" SG_ 33 LRRF2_TO_CADMTracksChange_Flt 0;
BA_ "GenSigCycleTime" SG_ 33 LRRF2_TO_CADMTracksChange_Flt 20;
BA_ "GenSigSendType" SG_ 33 LRRF2_TO_CADMSWVersion_Flt 0;
BA_ "GenSigCycleTime" SG_ 33 LRRF2_TO_CADMSWVersion_Flt 20;
BA_ "GenSigSendType" SG_ 33 LRRF2_TO_TDBlockage_Flt 0;
BA_ "GenSigCycleTime" SG_ 33 LRRF2_TO_TDBlockage_Flt 20;
BA_ "GenSigSendType" SG_ 33 LRRF2_TO_CADMSgnlActlVal_Flt 0;
BA_ "GenSigCycleTime" SG_ 33 LRRF2_TO_CADMSgnlActlVal_Flt 20;
BA_ "GenSigSendType" SG_ 33 LRRF2_TO_TrigControl_Flt 0;
BA_ "GenSigCycleTime" SG_ 33 LRRF2_TO_TrigControl_Flt 20;
BA_ "GenSigSendType" SG_ 33 LRRF2_TO_VehicleState_Flt 0;
BA_ "GenSigCycleTime" SG_ 33 LRRF2_TO_VehicleState_Flt 20;
BA_ "GenSigSendType" SG_ 33 LRRF2_MC_VehicleState_Flt 0;
BA_ "GenSigCycleTime" SG_ 33 LRRF2_MC_VehicleState_Flt 20;
BA_ "GenSigSendType" SG_ 33 LRRF2_CRC_VehicleState_Flt 0;
BA_ "GenSigCycleTime" SG_ 33 LRRF2_CRC_VehicleState_Flt 20;
BA_ "GenSigSendType" SG_ 33 LRRF2_MC_TrigControl_Flt 0;
BA_ "GenSigCycleTime" SG_ 33 LRRF2_MC_TrigControl_Flt 20;
BA_ "GenSigSendType" SG_ 33 LRRF2_CRC_TrigControl_Flt 0;
BA_ "GenSigCycleTime" SG_ 33 LRRF2_CRC_TrigControl_Flt 20;
BA_ "GenSigSendType" SG_ 33 LRRF2_CRC_RadarCfgParameter_Flt 0;
BA_ "GenSigCycleTime" SG_ 33 LRRF2_CRC_RadarCfgParameter_Flt 20;
BA_ "GenSigSendType" SG_ 33 LRRF2_MC_CADMSgnlActlVal_Flt 0;
BA_ "GenSigCycleTime" SG_ 33 LRRF2_MC_CADMSgnlActlVal_Flt 20;
BA_ "GenSigSendType" SG_ 33 LRRF2_CRC_CADMSgnlActlVal_Flt 0;
BA_ "GenSigCycleTime" SG_ 33 LRRF2_CRC_CADMSgnlActlVal_Flt 20;
BA_ "GenSigSendType" SG_ 33 LRRF1_TO_RADARCfgParameter_Flt 0;
BA_ "GenSigCycleTime" SG_ 33 LRRF1_TO_RADARCfgParameter_Flt 20;
BA_ "GenSigSendType" SG_ 33 LRRF1_TO_SATCADMVIN_Flt 0;
BA_ "GenSigCycleTime" SG_ 33 LRRF1_TO_SATCADMVIN_Flt 20;
BA_ "GenSigSendType" SG_ 33 LRRF1_TO_CADMTracksChange_Flt 0;
BA_ "GenSigCycleTime" SG_ 33 LRRF1_TO_CADMTracksChange_Flt 20;
BA_ "GenSigSendType" SG_ 33 LRRF1_TO_SystemTDBlockage_Flt 0;
BA_ "GenSigCycleTime" SG_ 33 LRRF1_TO_SystemTDBlockage_Flt 20;
BA_ "GenSigSendType" SG_ 33 LRRF1_TO_CADMSgnlActlVal_Flt 0;
BA_ "GenSigCycleTime" SG_ 33 LRRF1_TO_CADMSgnlActlVal_Flt 20;
BA_ "GenSigSendType" SG_ 33 LRRF1_TO_TrigControl_Flt 0;
BA_ "GenSigCycleTime" SG_ 33 LRRF1_TO_TrigControl_Flt 20;
BA_ "GenSigCycleTime" SG_ 33 LRRF1_TO_VehicleState_Flt 20;
BA_ "GenSigSendType" SG_ 33 LRRF1_TO_VehicleState_Flt 0;
BA_ "GenSigSendType" SG_ 33 LRRF1_MC_VehicleState_Flt 0;
BA_ "GenSigCycleTime" SG_ 33 LRRF1_MC_VehicleState_Flt 20;
BA_ "GenSigSendType" SG_ 33 LRRF1_CRC_VehicleState_Flt 0;
BA_ "GenSigCycleTime" SG_ 33 LRRF1_CRC_VehicleState_Flt 20;
BA_ "GenSigSendType" SG_ 33 LRRF1_MC_TrigControl_Flt 0;
BA_ "GenSigCycleTime" SG_ 33 LRRF1_MC_TrigControl_Flt 20;
BA_ "GenSigSendType" SG_ 33 LRRF1_CRC_TrigControl_Flt 0;
BA_ "GenSigCycleTime" SG_ 33 LRRF1_CRC_TrigControl_Flt 20;
BA_ "GenSigSendType" SG_ 33 LRRF1_CRC_RadarCfgParameter_Flt 0;
BA_ "GenSigCycleTime" SG_ 33 LRRF1_CRC_RadarCfgParameter_Flt 20;
BA_ "GenSigSendType" SG_ 33 LRRF1_MC_CADMSgnlActlVal_Flt 0;
BA_ "GenSigCycleTime" SG_ 33 LRRF1_MC_CADMSgnlActlVal_Flt 20;
BA_ "GenSigSendType" SG_ 33 LRRF1_CRC_CADMSgnlActlVal_Flt 0;
BA_ "GenSigCycleTime" SG_ 33 LRRF1_CRC_CADMSgnlActlVal_Flt 20;
BA_ "GenSigSendType" SG_ 33 LRRF1_RRUBIST_Flt 0;
BA_ "GenSigCycleTime" SG_ 33 LRRF1_RRUBIST_Flt 20;
BA_ "GenSigSendType" SG_ 33 LRRF1_Dolphin_Flt 0;
BA_ "GenSigCycleTime" SG_ 33 LRRF1_Dolphin_Flt 20;
BA_ "GenSigSendType" SG_ 33 LRRF1_RRUCore_Flt 0;
BA_ "GenSigCycleTime" SG_ 33 LRRF1_RRUCore_Flt 20;
BA_ "GenSigSendType" SG_ 33 LRRF1_PCANDataRangeChk_Flt 0;
BA_ "GenSigCycleTime" SG_ 33 LRRF1_PCANDataRangeChk_Flt 20;
BA_ "GenSigSendType" SG_ 33 LRRF1_VINSignalCompare_Flt 0;
BA_ "GenSigVtEn" SG_ 33 LRRF1_VINSignalCompare_Flt "TRUE";
BA_ "GenSigCycleTime" SG_ 33 LRRF1_VINSignalCompare_Flt 20;
BA_ "GenSigSendType" SG_ 33 LRRF1_BatteryLow_Flt 0;
BA_ "GenSigVtEn" SG_ 33 LRRF1_BatteryLow_Flt "TRUE";
BA_ "GenSigCycleTime" SG_ 33 LRRF1_BatteryLow_Flt 20;
BA_ "GenSigSendType" SG_ 33 LRRF1_BatteryHigh_Flt 0;
BA_ "GenSigVtEn" SG_ 33 LRRF1_BatteryHigh_Flt "TRUE";
BA_ "GenSigCycleTime" SG_ 33 LRRF1_BatteryHigh_Flt 20;
BA_ "GenSigSendType" SG_ 33 LRRF1_Core1_To_Core0_IPC_Flt 0;
BA_ "GenSigVtEn" SG_ 33 LRRF1_Core1_To_Core0_IPC_Flt "TRUE";
BA_ "GenSigCycleTime" SG_ 33 LRRF1_Core1_To_Core0_IPC_Flt 20;
BA_ "GenSigCycleTime" SG_ 33 LRRF1_Core0_To_Core1_IPC_Flt 20;
BA_ "GenSigSendType" SG_ 33 LRRF1_Core0_To_Core1_IPC_Flt 0;
BA_ "GenSigVtEn" SG_ 33 LRRF1_Core0_To_Core1_IPC_Flt "TRUE";
BA_ "GenSigVtEn" SG_ 33 LRRF1_Core1_To_Core2_IPC_Flt "TRUE";
BA_ "GenSigCycleTime" SG_ 33 LRRF1_Core1_To_Core2_IPC_Flt 20;
BA_ "GenSigSendType" SG_ 33 LRRF1_Core1_To_Core2_IPC_Flt 0;
BA_ "GenSigVtEn" SG_ 33 LRRF1_Core2_To_Core1_IPC_Flt "TRUE";
BA_ "GenSigCycleTime" SG_ 33 LRRF1_Core2_To_Core1_IPC_Flt 20;
BA_ "GenSigSendType" SG_ 33 LRRF1_Core2_To_Core1_IPC_Flt 0;
BA_ "GenSigVtEn" SG_ 33 LRRF1_Core2_To_Core0_IPC_Flt "TRUE";
BA_ "GenSigCycleTime" SG_ 33 LRRF1_Core2_To_Core0_IPC_Flt 20;
BA_ "GenSigSendType" SG_ 33 LRRF1_Core2_To_Core0_IPC_Flt 0;
BA_ "GenSigCycleTime" SG_ 33 LRRF1_Core2Halted_Flt 20;
BA_ "GenSigSendType" SG_ 33 LRRF1_Core2Halted_Flt 0;
BA_ "GenSigCycleTime" SG_ 33 LRRF1_Core1Halted_Flt 20;
BA_ "GenSigSendType" SG_ 33 LRRF1_Core1Halted_Flt 0;
BA_ "GenSigCycleTime" SG_ 33 LRRF1_LocalOscPower_Flt 20;
BA_ "GenSigVtEn" SG_ 33 LRRF1_LocalOscPower_Flt "TRUE";
BA_ "GenSigSendType" SG_ 33 LRRF1_LocalOscPower_Flt 0;
BA_ "GenSigCycleTime" SG_ 33 LRRF1_DSPLoopOverrun_Flt 20;
BA_ "GenSigVtEn" SG_ 33 LRRF1_DSPLoopOverrun_Flt "TRUE";
BA_ "GenSigSendType" SG_ 33 LRRF1_DSPLoopOverrun_Flt 0;
BA_ "GenSigCycleTime" SG_ 33 LRRF1_TransmitterPower_Flt 20;
BA_ "GenSigVtEn" SG_ 33 LRRF1_TransmitterPower_Flt "TRUE";
BA_ "GenSigSendType" SG_ 33 LRRF1_TransmitterPower_Flt 0;
BA_ "GenSigCycleTime" SG_ 33 LRRF1_Core0_To_Core2_IPC_Flt 20;
BA_ "GenSigVtEn" SG_ 33 LRRF1_Core0_To_Core2_IPC_Flt "TRUE";
BA_ "GenSigSendType" SG_ 33 LRRF1_Core0_To_Core2_IPC_Flt 0;
BA_ "GenSigCycleTime" SG_ 33 LRRF1_XCVRDeviceSPI_Flt 20;
BA_ "GenSigVtEn" SG_ 33 LRRF1_XCVRDeviceSPI_Flt "TRUE";
BA_ "GenSigSendType" SG_ 33 LRRF1_XCVRDeviceSPI_Flt 0;
BA_ "GenSigCycleTime" SG_ 33 LRRF1_SidelobeBlockage_Flt 20;
BA_ "GenSigVtEn" SG_ 33 LRRF1_SidelobeBlockage_Flt "TRUE";
BA_ "GenSigSendType" SG_ 33 LRRF1_SidelobeBlockage_Flt 0;
BA_ "GenSigCycleTime" SG_ 33 LRRF1_MNRBlockage_Flt 20;
BA_ "GenSigVtEn" SG_ 33 LRRF1_MNRBlockage_Flt "TRUE";
BA_ "GenSigSendType" SG_ 33 LRRF1_MNRBlockage_Flt 0;
BA_ "GenSigCycleTime" SG_ 33 LRRF1_TransmitterTempHigh_Flt 20;
BA_ "GenSigVtEn" SG_ 33 LRRF1_TransmitterTempHigh_Flt "TRUE";
BA_ "GenSigSendType" SG_ 33 LRRF1_TransmitterTempHigh_Flt 0;
BA_ "GenSigCycleTime" SG_ 33 LRRF1_AlignRoutineFailed_Flt 20;
BA_ "GenSigVtEn" SG_ 33 LRRF1_AlignRoutineFailed_Flt "TRUE";
BA_ "GenSigSendType" SG_ 33 LRRF1_AlignRoutineFailed_Flt 0;
BA_ "GenSigCycleTime" SG_ 33 LRRF1_MicroTempHigh_Flt 20;
BA_ "GenSigVtEn" SG_ 33 LRRF1_MicroTempHigh_Flt "TRUE";
BA_ "GenSigSendType" SG_ 33 LRRF1_MicroTempHigh_Flt 0;
BA_ "GenSigCycleTime" SG_ 33 LRRF1_FactoryAlignmentMode_Flt 20;
BA_ "GenSigVtEn" SG_ 33 LRRF1_FactoryAlignmentMode_Flt "TRUE";
BA_ "GenSigSendType" SG_ 33 LRRF1_FactoryAlignmentMode_Flt 0;
BA_ "GenSigCycleTime" SG_ 33 LRRF1_VAlignOutofRange_Flt 20;
BA_ "GenSigVtEn" SG_ 33 LRRF1_VAlignOutofRange_Flt "TRUE";
BA_ "GenSigSendType" SG_ 33 LRRF1_VAlignOutofRange_Flt 0;
BA_ "GenSigCycleTime" SG_ 33 LRRF1_HAlignOutofRange_Flt 20;
BA_ "GenSigVtEn" SG_ 33 LRRF1_HAlignOutofRange_Flt "TRUE";
BA_ "GenSigSendType" SG_ 33 LRRF1_HAlignOutofRange_Flt 0;
BA_ "GenSigCycleTime" SG_ 33 LRRF1_v1p1_SupplyOutOfRange_Flt 20;
BA_ "GenSigVtEn" SG_ 33 LRRF1_v1p1_SupplyOutOfRange_Flt "TRUE";
BA_ "GenSigSendType" SG_ 33 LRRF1_v1p1_SupplyOutOfRange_Flt 0;
BA_ "GenSigCycleTime" SG_ 33 LRRF1_v1p25_SupplyOutOfRange_Flt 20;
BA_ "GenSigVtEn" SG_ 33 LRRF1_v1p25_SupplyOutOfRange_Flt "TRUE";
BA_ "GenSigSendType" SG_ 33 LRRF1_v1p25_SupplyOutOfRange_Flt 0;
BA_ "GenSigCycleTime" SG_ 33 LRRF1_v1p8_SupplyOutOfRange_Flt 20;
BA_ "GenSigVtEn" SG_ 33 LRRF1_v1p8_SupplyOutOfRange_Flt "TRUE";
BA_ "GenSigSendType" SG_ 33 LRRF1_v1p8_SupplyOutOfRange_Flt 0;
BA_ "GenSigCycleTime" SG_ 33 LRRF1_v2p3_SupplyOutOfRange_Flt 20;
BA_ "GenSigVtEn" SG_ 33 LRRF1_v2p3_SupplyOutOfRange_Flt "TRUE";
BA_ "GenSigSendType" SG_ 33 LRRF1_v2p3_SupplyOutOfRange_Flt 0;
BA_ "GenSigCycleTime" SG_ 33 LRRF1_v_5_SupplyOutOfRange_Flt 20;
BA_ "GenSigVtEn" SG_ 33 LRRF1_v_5_SupplyOutOfRange_Flt "TRUE";
BA_ "GenSigSendType" SG_ 33 LRRF1_v_5_SupplyOutOfRange_Flt 0;
BA_ "GenSigCycleTime" SG_ 33 LRRF1_TransmitterID_Flt 20;
BA_ "GenSigVtEn" SG_ 33 LRRF1_TransmitterID_Flt "TRUE";
BA_ "GenSigSendType" SG_ 33 LRRF1_TransmitterID_Flt 0;
BA_ "GenSigCycleTime" SG_ 33 LRRF1_PCANBusOff_Flt 20;
BA_ "GenSigVtEn" SG_ 33 LRRF1_PCANBusOff_Flt "TRUE";
BA_ "GenSigSendType" SG_ 33 LRRF1_PCANBusOff_Flt 0;
BA_ "GenSigCycleTime" SG_ 33 LRRF1_InstructionSetCheck_Flt 20;
BA_ "GenSigVtEn" SG_ 33 LRRF1_InstructionSetCheck_Flt "TRUE";
BA_ "GenSigSendType" SG_ 33 LRRF1_InstructionSetCheck_Flt 0;
BA_ "GenSigCycleTime" SG_ 33 LRRF1_StackOverflow_Flt 20;
BA_ "GenSigVtEn" SG_ 33 LRRF1_StackOverflow_Flt "TRUE";
BA_ "GenSigSendType" SG_ 33 LRRF1_StackOverflow_Flt 0;
BA_ "GenSigCycleTime" SG_ 33 LRRF1_Watchdog_Flt 20;
BA_ "GenSigVtEn" SG_ 33 LRRF1_Watchdog_Flt "TRUE";
BA_ "GenSigSendType" SG_ 33 LRRF1_Watchdog_Flt 0;
BA_ "GenSigCycleTime" SG_ 33 LRRF1_PLLLock_Flt 20;
BA_ "GenSigVtEn" SG_ 33 LRRF1_PLLLock_Flt "TRUE";
BA_ "GenSigSendType" SG_ 33 LRRF1_PLLLock_Flt 0;
BA_ "GenSigCycleTime" SG_ 33 LRRF1_RAMMemoryTest_Flt 20;
BA_ "GenSigVtEn" SG_ 33 LRRF1_RAMMemoryTest_Flt "TRUE";
BA_ "GenSigSendType" SG_ 33 LRRF1_RAMMemoryTest_Flt 0;
BA_ "GenSigCycleTime" SG_ 33 LRRF1_USCValidation_Flt 20;
BA_ "GenSigVtEn" SG_ 33 LRRF1_USCValidation_Flt "TRUE";
BA_ "GenSigSendType" SG_ 33 LRRF1_USCValidation_Flt 0;
BA_ "GenSigCycleTime" SG_ 33 LRRF1_SMC_Checksum_Flt 20;
BA_ "GenSigVtEn" SG_ 33 LRRF1_SMC_Checksum_Flt "TRUE";
BA_ "GenSigSendType" SG_ 33 LRRF1_SMC_Checksum_Flt 0;
BA_ "GenSigCycleTime" SG_ 33 LRRF1_KeepAliveChecksum_Flt 20;
BA_ "GenSigVtEn" SG_ 33 LRRF1_KeepAliveChecksum_Flt "TRUE";
BA_ "GenSigSendType" SG_ 33 LRRF1_KeepAliveChecksum_Flt 0;
BA_ "GenSigCycleTime" SG_ 33 LRRF1_ApplicationFlashChksum_Flt 20;
BA_ "GenSigVtEn" SG_ 33 LRRF1_ApplicationFlashChksum_Flt "TRUE";
BA_ "GenSigSendType" SG_ 33 LRRF1_ApplicationFlashChksum_Flt 0;
BA_ "GenSigSendType" SG_ 122 LRRF1_XCP_DAQ_Resp_byte63 1;
BA_ "SignalDescription" SG_ 122 LRRF1_XCP_DAQ_Resp_byte63 "XCP DAQ response byte 63";
BA_ "SignalDescription" SG_ 122 LRRF1_XCP_DAQ_Resp_byte62 "XCP DAQ response byte 62";
BA_ "SignalDescription" SG_ 122 LRRF1_XCP_DAQ_Resp_byte61 "XCP DAQ response byte 61";
BA_ "SignalDescription" SG_ 122 LRRF1_XCP_DAQ_Resp_byte60 "XCP DAQ response byte 60";
BA_ "SignalDescription" SG_ 122 LRRF1_XCP_DAQ_Resp_byte59 "XCP DAQ response byte 59";
BA_ "SignalDescription" SG_ 122 LRRF1_XCP_DAQ_Resp_byte58 "XCP DAQ response byte 58";
BA_ "SignalDescription" SG_ 122 LRRF1_XCP_DAQ_Resp_byte57 "XCP DAQ response byte 57";
BA_ "SignalDescription" SG_ 122 LRRF1_XCP_DAQ_Resp_byte56 "XCP DAQ response byte 56";
BA_ "SignalDescription" SG_ 122 LRRF1_XCP_DAQ_Resp_byte55 "XCP DAQ response byte 55";
BA_ "SignalDescription" SG_ 122 LRRF1_XCP_DAQ_Resp_byte54 "XCP DAQ response byte 54";
BA_ "SignalDescription" SG_ 122 LRRF1_XCP_DAQ_Resp_byte53 "XCP DAQ response byte 53";
BA_ "SignalDescription" SG_ 122 LRRF1_XCP_DAQ_Resp_byte52 "XCP DAQ response byte 52";
BA_ "SignalDescription" SG_ 122 LRRF1_XCP_DAQ_Resp_byte51 "XCP DAQ response byte 51";
BA_ "SignalDescription" SG_ 122 LRRF1_XCP_DAQ_Resp_byte50 "XCP DAQ response byte 50";
BA_ "SignalDescription" SG_ 122 LRRF1_XCP_DAQ_Resp_byte49 "XCP DAQ response byte 49";
BA_ "SignalDescription" SG_ 122 LRRF1_XCP_DAQ_Resp_byte48 "XCP DAQ response byte 48";
BA_ "SignalDescription" SG_ 122 LRRF1_XCP_DAQ_Resp_byte47 "XCP DAQ response byte 47";
BA_ "SignalDescription" SG_ 122 LRRF1_XCP_DAQ_Resp_byte46 "XCP DAQ response byte 46";
BA_ "SignalDescription" SG_ 122 LRRF1_XCP_DAQ_Resp_byte45 "XCP DAQ response byte 45";
BA_ "SignalDescription" SG_ 122 LRRF1_XCP_DAQ_Resp_byte44 "XCP DAQ response byte 44";
BA_ "SignalDescription" SG_ 122 LRRF1_XCP_DAQ_Resp_byte43 "XCP DAQ response byte 43";
BA_ "SignalDescription" SG_ 122 LRRF1_XCP_DAQ_Resp_byte42 "XCP DAQ response byte 42";
BA_ "SignalDescription" SG_ 122 LRRF1_XCP_DAQ_Resp_byte41 "XCP DAQ response byte 41";
BA_ "SignalDescription" SG_ 122 LRRF1_XCP_DAQ_Resp_byte40 "XCP DAQ response byte 40";
BA_ "SignalDescription" SG_ 122 LRRF1_XCP_DAQ_Resp_byte39 "XCP DAQ response byte 39";
BA_ "SignalDescription" SG_ 122 LRRF1_XCP_DAQ_Resp_byte38 "XCP DAQ response byte 38";
BA_ "SignalDescription" SG_ 122 LRRF1_XCP_DAQ_Resp_byte37 "XCP DAQ response byte 37";
BA_ "SignalDescription" SG_ 122 LRRF1_XCP_DAQ_Resp_byte36 "XCP DAQ response byte 36";
BA_ "SignalDescription" SG_ 122 LRRF1_XCP_DAQ_Resp_byte35 "XCP DAQ response byte 35";
BA_ "SignalDescription" SG_ 122 LRRF1_XCP_DAQ_Resp_byte34 "XCP DAQ response byte 34";
BA_ "SignalDescription" SG_ 122 LRRF1_XCP_DAQ_Resp_byte33 "XCP DAQ response byte 33";
BA_ "SignalDescription" SG_ 122 LRRF1_XCP_DAQ_Resp_byte32 "XCP DAQ response byte 32";
BA_ "SignalDescription" SG_ 122 LRRF1_XCP_DAQ_Resp_byte31 "XCP DAQ response byte 31";
BA_ "SignalDescription" SG_ 122 LRRF1_XCP_DAQ_Resp_byte30 "XCP DAQ response byte 30";
BA_ "SignalDescription" SG_ 122 LRRF1_XCP_DAQ_Resp_byte29 "XCP DAQ response byte 29";
BA_ "SignalDescription" SG_ 122 LRRF1_XCP_DAQ_Resp_byte28 "XCP DAQ response byte 28";
BA_ "SignalDescription" SG_ 122 LRRF1_XCP_DAQ_Resp_byte27 "XCP DAQ response byte 27";
BA_ "SignalDescription" SG_ 122 LRRF1_XCP_DAQ_Resp_byte26 "XCP DAQ response byte 26";
BA_ "SignalDescription" SG_ 122 LRRF1_XCP_DAQ_Resp_byte25 "XCP DAQ response byte 25";
BA_ "SignalDescription" SG_ 122 LRRF1_XCP_DAQ_Resp_byte24 "XCP DAQ response byte 24";
BA_ "SignalDescription" SG_ 122 LRRF1_XCP_DAQ_Resp_byte23 "XCP DAQ response byte 23";
BA_ "SignalDescription" SG_ 122 LRRF1_XCP_DAQ_Resp_byte22 "XCP DAQ response byte 22";
BA_ "SignalDescription" SG_ 122 LRRF1_XCP_DAQ_Resp_byte21 "XCP DAQ response byte 21";
BA_ "SignalDescription" SG_ 122 LRRF1_XCP_DAQ_Resp_byte20 "XCP DAQ response byte 20";
BA_ "SignalDescription" SG_ 122 LRRF1_XCP_DAQ_Resp_byte19 "XCP DAQ response byte 19";
BA_ "SignalDescription" SG_ 122 LRRF1_XCP_DAQ_Resp_byte18 "XCP DAQ response byte 18";
BA_ "SignalDescription" SG_ 122 LRRF1_XCP_DAQ_Resp_byte17 "XCP DAQ response byte 17";
BA_ "SignalDescription" SG_ 122 LRRF1_XCP_DAQ_Resp_byte16 "XCP DAQ response byte 16";
BA_ "SignalDescription" SG_ 122 LRRF1_XCP_DAQ_Resp_byte15 "XCP DAQ response byte 15";
BA_ "SignalDescription" SG_ 122 LRRF1_XCP_DAQ_Resp_byte14 "XCP DAQ response byte 14";
BA_ "SignalDescription" SG_ 122 LRRF1_XCP_DAQ_Resp_byte13 "XCP DAQ response byte 13";
BA_ "SignalDescription" SG_ 122 LRRF1_XCP_DAQ_Resp_byte12 "XCP DAQ response byte 12";
BA_ "SignalDescription" SG_ 122 LRRF1_XCP_DAQ_Resp_byte11 "XCP DAQ response byte 11";
BA_ "SignalDescription" SG_ 122 LRRF1_XCP_DAQ_Resp_byte10 "XCP DAQ response byte 10";
BA_ "SignalDescription" SG_ 122 LRRF1_XCP_DAQ_Resp_byte9 "XCP DAQ response byte 9";
BA_ "SignalDescription" SG_ 122 LRRF1_XCP_DAQ_Resp_byte8 "XCP DAQ response byte 8";
BA_ "SignalDescription" SG_ 122 LRRF1_XCP_DAQ_Resp_byte7 "XCP DAQ response byte 7";
BA_ "SignalDescription" SG_ 122 LRRF1_XCP_DAQ_Resp_byte6 "XCP DAQ response byte 6";
BA_ "SignalDescription" SG_ 122 LRRF1_XCP_DAQ_Resp_byte5 "XCP DAQ response byte 5";
BA_ "SignalDescription" SG_ 122 LRRF1_XCP_DAQ_Resp_byte4 "XCP DAQ response byte 4";
BA_ "SignalDescription" SG_ 122 LRRF1_XCP_DAQ_Resp_byte3 "XCP DAQ response byte 3";
BA_ "SignalDescription" SG_ 122 LRRF1_XCP_DAQ_Resp_byte2 "XCP DAQ response byte 2";
BA_ "SignalDescription" SG_ 122 LRRF1_XCP_DAQ_Resp_byte1 "XCP DAQ response byte 1";
BA_ "SignalDescription" SG_ 122 LRRF1_XCP_DAQ_Resp_byte0 "XCP DAQ response byte 0";
BA_ "GenSigSendType" SG_ 121 LRRF1_XCP_DTO_Resp_byte63 1;
BA_ "SignalDescription" SG_ 121 LRRF1_XCP_DTO_Resp_byte63 "XCP DTO response byte 63";
BA_ "SignalDescription" SG_ 121 LRRF1_XCP_DTO_Resp_byte62 "XCP DTO response byte 62";
BA_ "SignalDescription" SG_ 121 LRRF1_XCP_DTO_Resp_byte61 "XCP DTO response byte 61";
BA_ "SignalDescription" SG_ 121 LRRF1_XCP_DTO_Resp_byte60 "XCP DTO response byte 60";
BA_ "SignalDescription" SG_ 121 LRRF1_XCP_DTO_Resp_byte59 "XCP DTO response byte 59";
BA_ "SignalDescription" SG_ 121 LRRF1_XCP_DTO_Resp_byte58 "XCP DTO response byte 58";
BA_ "SignalDescription" SG_ 121 LRRF1_XCP_DTO_Resp_byte57 "XCP DTO response byte 57";
BA_ "SignalDescription" SG_ 121 LRRF1_XCP_DTO_Resp_byte56 "XCP DTO response byte 56";
BA_ "SignalDescription" SG_ 121 LRRF1_XCP_DTO_Resp_byte55 "XCP DTO response byte 55";
BA_ "SignalDescription" SG_ 121 LRRF1_XCP_DTO_Resp_byte54 "XCP DTO response byte 54";
BA_ "SignalDescription" SG_ 121 LRRF1_XCP_DTO_Resp_byte53 "XCP DTO response byte 53";
BA_ "SignalDescription" SG_ 121 LRRF1_XCP_DTO_Resp_byte52 "XCP DTO response byte 52";
BA_ "SignalDescription" SG_ 121 LRRF1_XCP_DTO_Resp_byte51 "XCP DTO response byte 51";
BA_ "SignalDescription" SG_ 121 LRRF1_XCP_DTO_Resp_byte50 "XCP DTO response byte 50";
BA_ "SignalDescription" SG_ 121 LRRF1_XCP_DTO_Resp_byte49 "XCP DTO response byte 49";
BA_ "SignalDescription" SG_ 121 LRRF1_XCP_DTO_Resp_byte48 "XCP DTO response byte 48";
BA_ "SignalDescription" SG_ 121 LRRF1_XCP_DTO_Resp_byte47 "XCP DTO response byte 47";
BA_ "SignalDescription" SG_ 121 LRRF1_XCP_DTO_Resp_byte46 "XCP DTO response byte 46";
BA_ "SignalDescription" SG_ 121 LRRF1_XCP_DTO_Resp_byte45 "XCP DTO response byte 45";
BA_ "SignalDescription" SG_ 121 LRRF1_XCP_DTO_Resp_byte44 "XCP DTO response byte 44";
BA_ "SignalDescription" SG_ 121 LRRF1_XCP_DTO_Resp_byte43 "XCP DTO response byte 43";
BA_ "SignalDescription" SG_ 121 LRRF1_XCP_DTO_Resp_byte42 "XCP DTO response byte 42";
BA_ "SignalDescription" SG_ 121 LRRF1_XCP_DTO_Resp_byte41 "XCP DTO response byte 41";
BA_ "SignalDescription" SG_ 121 LRRF1_XCP_DTO_Resp_byte40 "XCP DTO response byte 40";
BA_ "SignalDescription" SG_ 121 LRRF1_XCP_DTO_Resp_byte39 "XCP DTO response byte 39";
BA_ "SignalDescription" SG_ 121 LRRF1_XCP_DTO_Resp_byte38 "XCP DTO response byte 38";
BA_ "SignalDescription" SG_ 121 LRRF1_XCP_DTO_Resp_byte37 "XCP DTO response byte 37";
BA_ "SignalDescription" SG_ 121 LRRF1_XCP_DTO_Resp_byte36 "XCP DTO response byte 36";
BA_ "SignalDescription" SG_ 121 LRRF1_XCP_DTO_Resp_byte35 "XCP DTO response byte 35";
BA_ "SignalDescription" SG_ 121 LRRF1_XCP_DTO_Resp_byte34 "XCP DTO response byte 34";
BA_ "SignalDescription" SG_ 121 LRRF1_XCP_DTO_Resp_byte33 "XCP DTO response byte 33";
BA_ "SignalDescription" SG_ 121 LRRF1_XCP_DTO_Resp_byte32 "XCP DTO response byte 32";
BA_ "SignalDescription" SG_ 121 LRRF1_XCP_DTO_Resp_byte31 "XCP DTO response byte 31";
BA_ "SignalDescription" SG_ 121 LRRF1_XCP_DTO_Resp_byte30 "XCP DTO response byte 30";
BA_ "SignalDescription" SG_ 121 LRRF1_XCP_DTO_Resp_byte29 "XCP DTO response byte 29";
BA_ "SignalDescription" SG_ 121 LRRF1_XCP_DTO_Resp_byte28 "XCP DTO response byte 28";
BA_ "SignalDescription" SG_ 121 LRRF1_XCP_DTO_Resp_byte27 "XCP DTO response byte 27";
BA_ "SignalDescription" SG_ 121 LRRF1_XCP_DTO_Resp_byte26 "XCP DTO response byte 26";
BA_ "SignalDescription" SG_ 121 LRRF1_XCP_DTO_Resp_byte25 "XCP DTO response byte 25";
BA_ "SignalDescription" SG_ 121 LRRF1_XCP_DTO_Resp_byte24 "XCP DTO response byte 24";
BA_ "SignalDescription" SG_ 121 LRRF1_XCP_DTO_Resp_byte23 "XCP DTO response byte 23";
BA_ "SignalDescription" SG_ 121 LRRF1_XCP_DTO_Resp_byte22 "XCP DTO response byte 22";
BA_ "SignalDescription" SG_ 121 LRRF1_XCP_DTO_Resp_byte21 "XCP DTO response byte 21";
BA_ "SignalDescription" SG_ 121 LRRF1_XCP_DTO_Resp_byte20 "XCP DTO response byte 20";
BA_ "SignalDescription" SG_ 121 LRRF1_XCP_DTO_Resp_byte19 "XCP DTO response byte 19";
BA_ "SignalDescription" SG_ 121 LRRF1_XCP_DTO_Resp_byte18 "XCP DTO response byte 18";
BA_ "SignalDescription" SG_ 121 LRRF1_XCP_DTO_Resp_byte17 "XCP DTO response byte 17";
BA_ "SignalDescription" SG_ 121 LRRF1_XCP_DTO_Resp_byte16 "XCP DTO response byte 16";
BA_ "SignalDescription" SG_ 121 LRRF1_XCP_DTO_Resp_byte15 "XCP DTO response byte 15";
BA_ "SignalDescription" SG_ 121 LRRF1_XCP_DTO_Resp_byte14 "XCP DTO response byte 14";
BA_ "SignalDescription" SG_ 121 LRRF1_XCP_DTO_Resp_byte13 "XCP DTO response byte 13";
BA_ "SignalDescription" SG_ 121 LRRF1_XCP_DTO_Resp_byte12 "XCP DTO response byte 12";
BA_ "SignalDescription" SG_ 121 LRRF1_XCP_DTO_Resp_byte11 "XCP DTO response byte 11";
BA_ "SignalDescription" SG_ 121 LRRF1_XCP_DTO_Resp_byte10 "XCP DTO response byte 10";
BA_ "SignalDescription" SG_ 121 LRRF1_XCP_DTO_Resp_byte9 "XCP DTO response byte 9";
BA_ "SignalDescription" SG_ 121 LRRF1_XCP_DTO_Resp_byte8 "XCP DTO response byte 8";
BA_ "SignalDescription" SG_ 121 LRRF1_XCP_DTO_Resp_byte7 "XCP DTO response byte 7";
BA_ "SignalDescription" SG_ 121 LRRF1_XCP_DTO_Resp_byte6 "XCP DTO response byte 6";
BA_ "SignalDescription" SG_ 121 LRRF1_XCP_DTO_Resp_byte5 "XCP DTO response byte 5";
BA_ "SignalDescription" SG_ 121 LRRF1_XCP_DTO_Resp_byte4 "XCP DTO response byte 4";
BA_ "SignalDescription" SG_ 121 LRRF1_XCP_DTO_Resp_byte3 "XCP DTO response byte 3";
BA_ "SignalDescription" SG_ 121 LRRF1_XCP_DTO_Resp_byte2 "XCP DTO response byte 2";
BA_ "SignalDescription" SG_ 121 LRRF1_XCP_DTO_Resp_byte1 "XCP DTO response byte 1";
BA_ "SignalDescription" SG_ 121 LRRF1_XCP_DTO_Resp_byte0 "XCP DTO response byte 0";
BA_ "SignalDescription" SG_ 120 LRRF1_XCP_DTO_CMD_byte63 "XCP DTO request byte 63";
BA_ "GenSigSendType" SG_ 120 LRRF1_XCP_DTO_CMD_byte63 1;
BA_ "SignalDescription" SG_ 120 LRRF1_XCP_DTO_CMD_byte62 "XCP DTO request byte 62";
BA_ "SignalDescription" SG_ 120 LRRF1_XCP_DTO_CMD_byte61 "XCP DTO request byte 61";
BA_ "SignalDescription" SG_ 120 LRRF1_XCP_DTO_CMD_byte60 "XCP DTO request byte 60";
BA_ "SignalDescription" SG_ 120 LRRF1_XCP_DTO_CMD_byte59 "XCP DTO request byte 59";
BA_ "SignalDescription" SG_ 120 LRRF1_XCP_DTO_CMD_byte58 "XCP DTO request byte 58";
BA_ "SignalDescription" SG_ 120 LRRF1_XCP_DTO_CMD_byte57 "XCP DTO request byte 57";
BA_ "SignalDescription" SG_ 120 LRRF1_XCP_DTO_CMD_byte56 "XCP DTO request byte 56";
BA_ "SignalDescription" SG_ 120 LRRF1_XCP_DTO_CMD_byte55 "XCP DTO request byte 55";
BA_ "SignalDescription" SG_ 120 LRRF1_XCP_DTO_CMD_byte54 "XCP DTO request byte 54";
BA_ "SignalDescription" SG_ 120 LRRF1_XCP_DTO_CMD_byte53 "XCP DTO request byte 53";
BA_ "SignalDescription" SG_ 120 LRRF1_XCP_DTO_CMD_byte52 "XCP DTO request byte 52";
BA_ "SignalDescription" SG_ 120 LRRF1_XCP_DTO_CMD_byte51 "XCP DTO request byte 51";
BA_ "SignalDescription" SG_ 120 LRRF1_XCP_DTO_CMD_byte50 "XCP DTO request byte 50";
BA_ "SignalDescription" SG_ 120 LRRF1_XCP_DTO_CMD_byte49 "XCP DTO request byte 49";
BA_ "SignalDescription" SG_ 120 LRRF1_XCP_DTO_CMD_byte48 "XCP DTO request byte 48";
BA_ "SignalDescription" SG_ 120 LRRF1_XCP_DTO_CMD_byte47 "XCP DTO request byte 47";
BA_ "SignalDescription" SG_ 120 LRRF1_XCP_DTO_CMD_byte46 "XCP DTO request byte 46";
BA_ "SignalDescription" SG_ 120 LRRF1_XCP_DTO_CMD_byte45 "XCP DTO request byte 45";
BA_ "SignalDescription" SG_ 120 LRRF1_XCP_DTO_CMD_byte44 "XCP DTO request byte 44";
BA_ "SignalDescription" SG_ 120 LRRF1_XCP_DTO_CMD_byte43 "XCP DTO request byte 43";
BA_ "SignalDescription" SG_ 120 LRRF1_XCP_DTO_CMD_byte42 "XCP DTO request byte 42";
BA_ "SignalDescription" SG_ 120 LRRF1_XCP_DTO_CMD_byte41 "XCP DTO request byte 41";
BA_ "SignalDescription" SG_ 120 LRRF1_XCP_DTO_CMD_byte40 "XCP DTO request byte 40";
BA_ "SignalDescription" SG_ 120 LRRF1_XCP_DTO_CMD_byte39 "XCP DTO request byte 39";
BA_ "SignalDescription" SG_ 120 LRRF1_XCP_DTO_CMD_byte38 "XCP DTO request byte 38";
BA_ "SignalDescription" SG_ 120 LRRF1_XCP_DTO_CMD_byte37 "XCP DTO request byte 37";
BA_ "SignalDescription" SG_ 120 LRRF1_XCP_DTO_CMD_byte36 "XCP DTO request byte 36";
BA_ "SignalDescription" SG_ 120 LRRF1_XCP_DTO_CMD_byte35 "XCP DTO request byte 35";
BA_ "SignalDescription" SG_ 120 LRRF1_XCP_DTO_CMD_byte34 "XCP DTO request byte 34";
BA_ "SignalDescription" SG_ 120 LRRF1_XCP_DTO_CMD_byte33 "XCP DTO request byte 33";
BA_ "SignalDescription" SG_ 120 LRRF1_XCP_DTO_CMD_byte32 "XCP DTO request byte 32";
BA_ "SignalDescription" SG_ 120 LRRF1_XCP_DTO_CMD_byte31 "XCP DTO request byte 31";
BA_ "SignalDescription" SG_ 120 LRRF1_XCP_DTO_CMD_byte30 "XCP DTO request byte 30";
BA_ "SignalDescription" SG_ 120 LRRF1_XCP_DTO_CMD_byte29 "XCP DTO request byte 29";
BA_ "SignalDescription" SG_ 120 LRRF1_XCP_DTO_CMD_byte28 "XCP DTO request byte 28";
BA_ "SignalDescription" SG_ 120 LRRF1_XCP_DTO_CMD_byte27 "XCP DTO request byte 27";
BA_ "SignalDescription" SG_ 120 LRRF1_XCP_DTO_CMD_byte26 "XCP DTO request byte 26";
BA_ "SignalDescription" SG_ 120 LRRF1_XCP_DTO_CMD_byte25 "XCP DTO request byte 25";
BA_ "SignalDescription" SG_ 120 LRRF1_XCP_DTO_CMD_byte24 "XCP DTO request byte 24";
BA_ "SignalDescription" SG_ 120 LRRF1_XCP_DTO_CMD_byte23 "XCP DTO request byte 23";
BA_ "SignalDescription" SG_ 120 LRRF1_XCP_DTO_CMD_byte22 "XCP DTO request byte 22";
BA_ "SignalDescription" SG_ 120 LRRF1_XCP_DTO_CMD_byte21 "XCP DTO request byte 21";
BA_ "SignalDescription" SG_ 120 LRRF1_XCP_DTO_CMD_byte20 "XCP DTO request byte 20";
BA_ "SignalDescription" SG_ 120 LRRF1_XCP_DTO_CMD_byte19 "XCP DTO request byte 19";
BA_ "SignalDescription" SG_ 120 LRRF1_XCP_DTO_CMD_byte18 "XCP DTO request byte 18";
BA_ "SignalDescription" SG_ 120 LRRF1_XCP_DTO_CMD_byte17 "XCP DTO request byte 17";
BA_ "SignalDescription" SG_ 120 LRRF1_XCP_DTO_CMD_byte16 "XCP DTO request byte 16";
BA_ "SignalDescription" SG_ 120 LRRF1_XCP_DTO_CMD_byte15 "XCP DTO request byte 15";
BA_ "SignalDescription" SG_ 120 LRRF1_XCP_DTO_CMD_byte14 "XCP DTO request byte 14";
BA_ "SignalDescription" SG_ 120 LRRF1_XCP_DTO_CMD_byte13 "XCP DTO request byte 13";
BA_ "SignalDescription" SG_ 120 LRRF1_XCP_DTO_CMD_byte12 "XCP DTO request byte 12";
BA_ "SignalDescription" SG_ 120 LRRF1_XCP_DTO_CMD_byte11 "XCP DTO request byte 11";
BA_ "SignalDescription" SG_ 120 LRRF1_XCP_DTO_CMD_byte10 "XCP DTO request byte 10";
BA_ "SignalDescription" SG_ 120 LRRF1_XCP_DTO_CMD_byte9 "XCP DTO request byte 9";
BA_ "SignalDescription" SG_ 120 LRRF1_XCP_DTO_CMD_byte8 "XCP DTO request byte 8";
BA_ "SignalDescription" SG_ 120 LRRF1_XCP_DTO_CMD_byte7 "XCP DTO request byte 7";
BA_ "SignalDescription" SG_ 120 LRRF1_XCP_DTO_CMD_byte6 "XCP DTO request byte 6";
BA_ "SignalDescription" SG_ 120 LRRF1_XCP_DTO_CMD_byte5 "XCP DTO request byte 5";
BA_ "SignalDescription" SG_ 120 LRRF1_XCP_DTO_CMD_byte4 "XCP DTO request byte 4";
BA_ "SignalDescription" SG_ 120 LRRF1_XCP_DTO_CMD_byte3 "XCP DTO request byte 3";
BA_ "SignalDescription" SG_ 120 LRRF1_XCP_DTO_CMD_byte2 "XCP DTO request byte 2";
BA_ "SignalDescription" SG_ 120 LRRF1_XCP_DTO_CMD_byte1 "XCP DTO request byte 1";
BA_ "SignalDescription" SG_ 120 LRRF1_XCP_DTO_CMD_byte0 "XCP DTO request byte 0";
BA_ "SignalDescription" SG_ 119 LRRF1_XCP_CTO_Resp_byte63 "XCP CTO response byte 63";
BA_ "GenSigSendType" SG_ 119 LRRF1_XCP_CTO_Resp_byte63 1;
BA_ "SignalDescription" SG_ 119 LRRF1_XCP_CTO_Resp_byte62 "XCP CTO response byte 62";
BA_ "SignalDescription" SG_ 119 LRRF1_XCP_CTO_Resp_byte61 "XCP CTO response byte 61";
BA_ "SignalDescription" SG_ 119 LRRF1_XCP_CTO_Resp_byte60 "XCP CTO response byte 60";
BA_ "SignalDescription" SG_ 119 LRRF1_XCP_CTO_Resp_byte59 "XCP CTO response byte 59";
BA_ "SignalDescription" SG_ 119 LRRF1_XCP_CTO_Resp_byte58 "XCP CTO response byte 58";
BA_ "SignalDescription" SG_ 119 LRRF1_XCP_CTO_Resp_byte57 "XCP CTO response byte 57";
BA_ "SignalDescription" SG_ 119 LRRF1_XCP_CTO_Resp_byte56 "XCP CTO response byte 56";
BA_ "SignalDescription" SG_ 119 LRRF1_XCP_CTO_Resp_byte55 "XCP CTO response byte 55";
BA_ "SignalDescription" SG_ 119 LRRF1_XCP_CTO_Resp_byte54 "XCP CTO response byte 54";
BA_ "SignalDescription" SG_ 119 LRRF1_XCP_CTO_Resp_byte53 "XCP CTO response byte 53";
BA_ "SignalDescription" SG_ 119 LRRF1_XCP_CTO_Resp_byte52 "XCP CTO response byte 52";
BA_ "SignalDescription" SG_ 119 LRRF1_XCP_CTO_Resp_byte51 "XCP CTO response byte 51";
BA_ "SignalDescription" SG_ 119 LRRF1_XCP_CTO_Resp_byte50 "XCP CTO response byte 50";
BA_ "SignalDescription" SG_ 119 LRRF1_XCP_CTO_Resp_byte49 "XCP CTO response byte 49";
BA_ "SignalDescription" SG_ 119 LRRF1_XCP_CTO_Resp_byte48 "XCP CTO response byte 48";
BA_ "SignalDescription" SG_ 119 LRRF1_XCP_CTO_Resp_byte47 "XCP CTO response byte 47";
BA_ "SignalDescription" SG_ 119 LRRF1_XCP_CTO_Resp_byte46 "XCP CTO response byte 46";
BA_ "SignalDescription" SG_ 119 LRRF1_XCP_CTO_Resp_byte45 "XCP CTO response byte 45";
BA_ "SignalDescription" SG_ 119 LRRF1_XCP_CTO_Resp_byte44 "XCP CTO response byte 44";
BA_ "SignalDescription" SG_ 119 LRRF1_XCP_CTO_Resp_byte43 "XCP CTO response byte 43";
BA_ "SignalDescription" SG_ 119 LRRF1_XCP_CTO_Resp_byte42 "XCP CTO response byte 42";
BA_ "SignalDescription" SG_ 119 LRRF1_XCP_CTO_Resp_byte41 "XCP CTO response byte 41";
BA_ "SignalDescription" SG_ 119 LRRF1_XCP_CTO_Resp_byte40 "XCP CTO response byte 40";
BA_ "SignalDescription" SG_ 119 LRRF1_XCP_CTO_Resp_byte39 "XCP CTO response byte 39";
BA_ "SignalDescription" SG_ 119 LRRF1_XCP_CTO_Resp_byte38 "XCP CTO response byte 38";
BA_ "SignalDescription" SG_ 119 LRRF1_XCP_CTO_Resp_byte37 "XCP CTO response byte 37";
BA_ "SignalDescription" SG_ 119 LRRF1_XCP_CTO_Resp_byte36 "XCP CTO response byte 36";
BA_ "SignalDescription" SG_ 119 LRRF1_XCP_CTO_Resp_byte35 "XCP CTO response byte 35";
BA_ "SignalDescription" SG_ 119 LRRF1_XCP_CTO_Resp_byte34 "XCP CTO response byte 34";
BA_ "SignalDescription" SG_ 119 LRRF1_XCP_CTO_Resp_byte33 "XCP CTO response byte 33";
BA_ "SignalDescription" SG_ 119 LRRF1_XCP_CTO_Resp_byte32 "XCP CTO response byte 32";
BA_ "SignalDescription" SG_ 119 LRRF1_XCP_CTO_Resp_byte31 "XCP CTO response byte 31";
BA_ "SignalDescription" SG_ 119 LRRF1_XCP_CTO_Resp_byte30 "XCP CTO response byte 30";
BA_ "SignalDescription" SG_ 119 LRRF1_XCP_CTO_Resp_byte29 "XCP CTO response byte 29";
BA_ "SignalDescription" SG_ 119 LRRF1_XCP_CTO_Resp_byte28 "XCP CTO response byte 28";
BA_ "SignalDescription" SG_ 119 LRRF1_XCP_CTO_Resp_byte27 "XCP CTO response byte 27";
BA_ "SignalDescription" SG_ 119 LRRF1_XCP_CTO_Resp_byte26 "XCP CTO response byte 26";
BA_ "SignalDescription" SG_ 119 LRRF1_XCP_CTO_Resp_byte25 "XCP CTO response byte 25";
BA_ "SignalDescription" SG_ 119 LRRF1_XCP_CTO_Resp_byte24 "XCP CTO response byte 24";
BA_ "SignalDescription" SG_ 119 LRRF1_XCP_CTO_Resp_byte23 "XCP CTO response byte 23";
BA_ "SignalDescription" SG_ 119 LRRF1_XCP_CTO_Resp_byte22 "XCP CTO response byte 22";
BA_ "SignalDescription" SG_ 119 LRRF1_XCP_CTO_Resp_byte21 "XCP CTO response byte 21";
BA_ "SignalDescription" SG_ 119 LRRF1_XCP_CTO_Resp_byte20 "XCP CTO response byte 20";
BA_ "SignalDescription" SG_ 119 LRRF1_XCP_CTO_Resp_byte19 "XCP CTO response byte 19";
BA_ "SignalDescription" SG_ 119 LRRF1_XCP_CTO_Resp_byte18 "XCP CTO response byte 18";
BA_ "SignalDescription" SG_ 119 LRRF1_XCP_CTO_Resp_byte17 "XCP CTO response byte 17";
BA_ "SignalDescription" SG_ 119 LRRF1_XCP_CTO_Resp_byte16 "XCP CTO response byte 16";
BA_ "SignalDescription" SG_ 119 LRRF1_XCP_CTO_Resp_byte15 "XCP CTO response byte 15";
BA_ "SignalDescription" SG_ 119 LRRF1_XCP_CTO_Resp_byte14 "XCP CTO response byte 14";
BA_ "SignalDescription" SG_ 119 LRRF1_XCP_CTO_Resp_byte13 "XCP CTO response byte 13";
BA_ "SignalDescription" SG_ 119 LRRF1_XCP_CTO_Resp_byte12 "XCP CTO response byte 12";
BA_ "SignalDescription" SG_ 119 LRRF1_XCP_CTO_Resp_byte11 "XCP CTO response byte 11";
BA_ "SignalDescription" SG_ 119 LRRF1_XCP_CTO_Resp_byte10 "XCP CTO response byte 10";
BA_ "SignalDescription" SG_ 119 LRRF1_XCP_CTO_Resp_byte9 "XCP CTO response byte 9";
BA_ "SignalDescription" SG_ 119 LRRF1_XCP_CTO_Resp_byte8 "XCP CTO response byte 8";
BA_ "SignalDescription" SG_ 119 LRRF1_XCP_CTO_Resp_byte7 "XCP CTO response byte 7";
BA_ "SignalDescription" SG_ 119 LRRF1_XCP_CTO_Resp_byte6 "XCP CTO response byte 6";
BA_ "SignalDescription" SG_ 119 LRRF1_XCP_CTO_Resp_byte5 "XCP CTO response byte 5";
BA_ "SignalDescription" SG_ 119 LRRF1_XCP_CTO_Resp_byte4 "XCP CTO response byte 4";
BA_ "SignalDescription" SG_ 119 LRRF1_XCP_CTO_Resp_byte3 "XCP CTO response byte 3";
BA_ "SignalDescription" SG_ 119 LRRF1_XCP_CTO_Resp_byte2 "XCP CTO response byte 2";
BA_ "SignalDescription" SG_ 119 LRRF1_XCP_CTO_Resp_byte1 "XCP CTO response byte 1";
BA_ "SignalDescription" SG_ 119 LRRF1_XCP_CTO_Resp_byte0 "XCP CTO response byte 0";
BA_ "GenSigSendType" SG_ 118 LRRF1_XCP_CTO_CMD_byte63 1;
BA_ "SignalDescription" SG_ 118 LRRF1_XCP_CTO_CMD_byte63 "XCP CTO request byte 63";
BA_ "SignalDescription" SG_ 118 LRRF1_XCP_CTO_CMD_byte62 "XCP CTO request byte 62";
BA_ "SignalDescription" SG_ 118 LRRF1_XCP_CTO_CMD_byte61 "XCP CTO request byte 61";
BA_ "SignalDescription" SG_ 118 LRRF1_XCP_CTO_CMD_byte60 "XCP CTO request byte 60";
BA_ "SignalDescription" SG_ 118 LRRF1_XCP_CTO_CMD_byte59 "XCP CTO request byte 59";
BA_ "SignalDescription" SG_ 118 LRRF1_XCP_CTO_CMD_byte58 "XCP CTO request byte 58";
BA_ "SignalDescription" SG_ 118 LRRF1_XCP_CTO_CMD_byte57 "XCP CTO request byte 57";
BA_ "SignalDescription" SG_ 118 LRRF1_XCP_CTO_CMD_byte56 "XCP CTO request byte 56";
BA_ "SignalDescription" SG_ 118 LRRF1_XCP_CTO_CMD_byte55 "XCP CTO request byte 55";
BA_ "SignalDescription" SG_ 118 LRRF1_XCP_CTO_CMD_byte54 "XCP CTO request byte 54";
BA_ "SignalDescription" SG_ 118 LRRF1_XCP_CTO_CMD_byte53 "XCP CTO request byte 53";
BA_ "SignalDescription" SG_ 118 LRRF1_XCP_CTO_CMD_byte52 "XCP CTO request byte 52";
BA_ "SignalDescription" SG_ 118 LRRF1_XCP_CTO_CMD_byte51 "XCP CTO request byte 51";
BA_ "SignalDescription" SG_ 118 LRRF1_XCP_CTO_CMD_byte50 "XCP CTO request byte 50";
BA_ "SignalDescription" SG_ 118 LRRF1_XCP_CTO_CMD_byte49 "XCP CTO request byte 49";
BA_ "SignalDescription" SG_ 118 LRRF1_XCP_CTO_CMD_byte48 "XCP CTO request byte 48";
BA_ "SignalDescription" SG_ 118 LRRF1_XCP_CTO_CMD_byte47 "XCP CTO request byte 47";
BA_ "SignalDescription" SG_ 118 LRRF1_XCP_CTO_CMD_byte46 "XCP CTO request byte 46";
BA_ "SignalDescription" SG_ 118 LRRF1_XCP_CTO_CMD_byte45 "XCP CTO request byte 45";
BA_ "SignalDescription" SG_ 118 LRRF1_XCP_CTO_CMD_byte44 "XCP CTO request byte 44";
BA_ "SignalDescription" SG_ 118 LRRF1_XCP_CTO_CMD_byte43 "XCP CTO request byte 43";
BA_ "SignalDescription" SG_ 118 LRRF1_XCP_CTO_CMD_byte42 "XCP CTO request byte 42";
BA_ "SignalDescription" SG_ 118 LRRF1_XCP_CTO_CMD_byte41 "XCP CTO request byte 41";
BA_ "SignalDescription" SG_ 118 LRRF1_XCP_CTO_CMD_byte40 "XCP CTO request byte 40";
BA_ "SignalDescription" SG_ 118 LRRF1_XCP_CTO_CMD_byte39 "XCP CTO request byte 39";
BA_ "SignalDescription" SG_ 118 LRRF1_XCP_CTO_CMD_byte38 "XCP CTO request byte 38";
BA_ "SignalDescription" SG_ 118 LRRF1_XCP_CTO_CMD_byte37 "XCP CTO request byte 37";
BA_ "SignalDescription" SG_ 118 LRRF1_XCP_CTO_CMD_byte36 "XCP CTO request byte 36";
BA_ "SignalDescription" SG_ 118 LRRF1_XCP_CTO_CMD_byte35 "XCP CTO request byte 35";
BA_ "SignalDescription" SG_ 118 LRRF1_XCP_CTO_CMD_byte34 "XCP CTO request byte 34";
BA_ "SignalDescription" SG_ 118 LRRF1_XCP_CTO_CMD_byte33 "XCP CTO request byte 33";
BA_ "SignalDescription" SG_ 118 LRRF1_XCP_CTO_CMD_byte32 "XCP CTO request byte 32";
BA_ "SignalDescription" SG_ 118 LRRF1_XCP_CTO_CMD_byte31 "XCP CTO request byte 31";
BA_ "SignalDescription" SG_ 118 LRRF1_XCP_CTO_CMD_byte30 "XCP CTO request byte 30";
BA_ "SignalDescription" SG_ 118 LRRF1_XCP_CTO_CMD_byte29 "XCP CTO request byte 29";
BA_ "SignalDescription" SG_ 118 LRRF1_XCP_CTO_CMD_byte28 "XCP CTO request byte 28";
BA_ "SignalDescription" SG_ 118 LRRF1_XCP_CTO_CMD_byte27 "XCP CTO request byte 27";
BA_ "SignalDescription" SG_ 118 LRRF1_XCP_CTO_CMD_byte26 "XCP CTO request byte 26";
BA_ "SignalDescription" SG_ 118 LRRF1_XCP_CTO_CMD_byte25 "XCP CTO request byte 25";
BA_ "SignalDescription" SG_ 118 LRRF1_XCP_CTO_CMD_byte24 "XCP CTO request byte 24";
BA_ "SignalDescription" SG_ 118 LRRF1_XCP_CTO_CMD_byte23 "XCP CTO request byte 23";
BA_ "SignalDescription" SG_ 118 LRRF1_XCP_CTO_CMD_byte22 "XCP CTO request byte 22";
BA_ "SignalDescription" SG_ 118 LRRF1_XCP_CTO_CMD_byte21 "XCP CTO request byte 21";
BA_ "SignalDescription" SG_ 118 LRRF1_XCP_CTO_CMD_byte20 "XCP CTO request byte 20";
BA_ "SignalDescription" SG_ 118 LRRF1_XCP_CTO_CMD_byte19 "XCP CTO request byte 19";
BA_ "SignalDescription" SG_ 118 LRRF1_XCP_CTO_CMD_byte18 "XCP CTO request byte 18";
BA_ "SignalDescription" SG_ 118 LRRF1_XCP_CTO_CMD_byte17 "XCP CTO request byte 17";
BA_ "SignalDescription" SG_ 118 LRRF1_XCP_CTO_CMD_byte16 "XCP CTO request byte 16";
BA_ "SignalDescription" SG_ 118 LRRF1_XCP_CTO_CMD_byte15 "XCP CTO request byte 15";
BA_ "SignalDescription" SG_ 118 LRRF1_XCP_CTO_CMD_byte14 "XCP CTO request byte 14";
BA_ "SignalDescription" SG_ 118 LRRF1_XCP_CTO_CMD_byte13 "XCP CTO request byte 13";
BA_ "SignalDescription" SG_ 118 LRRF1_XCP_CTO_CMD_byte12 "XCP CTO request byte 12";
BA_ "SignalDescription" SG_ 118 LRRF1_XCP_CTO_CMD_byte11 "XCP CTO request byte 11";
BA_ "SignalDescription" SG_ 118 LRRF1_XCP_CTO_CMD_byte10 "XCP CTO request byte 10";
BA_ "SignalDescription" SG_ 118 LRRF1_XCP_CTO_CMD_byte9 "XCP CTO request byte 9";
BA_ "SignalDescription" SG_ 118 LRRF1_XCP_CTO_CMD_byte8 "XCP CTO request byte 8";
BA_ "SignalDescription" SG_ 118 LRRF1_XCP_CTO_CMD_byte7 "XCP CTO request byte 7";
BA_ "SignalDescription" SG_ 118 LRRF1_XCP_CTO_CMD_byte6 "XCP CTO request byte 6";
BA_ "SignalDescription" SG_ 118 LRRF1_XCP_CTO_CMD_byte5 "XCP CTO request byte 5";
BA_ "SignalDescription" SG_ 118 LRRF1_XCP_CTO_CMD_byte4 "XCP CTO request byte 4";
BA_ "SignalDescription" SG_ 118 LRRF1_XCP_CTO_CMD_byte3 "XCP CTO request byte 3";
BA_ "SignalDescription" SG_ 118 LRRF1_XCP_CTO_CMD_byte2 "XCP CTO request byte 2";
BA_ "SignalDescription" SG_ 118 LRRF1_XCP_CTO_CMD_byte1 "XCP CTO request byte 1";
BA_ "SignalDescription" SG_ 118 LRRF1_XCP_CTO_CMD_byte0 "XCP CTO request byte 0";
BA_ "GenSigSendType" SG_ 1900 LRRF1_TesterPhysicalResLRRF 5;
BA_ "SignalDescription" SG_ 1900 LRRF1_TesterPhysicalResLRRF "Physical response";
BA_ "SignalDescription" SG_ 1892 LRRF1_TesterPhysicalReqLRRF "Physical request";
BA_ "GenSigSendType" SG_ 1892 LRRF1_TesterPhysicalReqLRRF 1;
BA_ "GenSigSendType" SG_ 185 CAN_CADM_Master 0;
BA_ "GenSigCycleTime" SG_ 185 CAN_CADM_Master 10;
BA_ "GenSigSendType" SG_ 185 CAN_STEERING_ANGLE 0;
BA_ "GenSigCycleTime" SG_ 185 CAN_STEERING_ANGLE 10;
BA_ "GenSigSendType" SG_ 185 CAN_WIPER_STATUS 0;
BA_ "GenSigCycleTime" SG_ 185 CAN_WIPER_STATUS 10;
BA_ "GenSigCmt" SG_ 185 CAN_WIPER_STATUS "Windshield wiper status";
BA_ "GenSigSendType" SG_ 185 CAN_VEHICLE_MODE 0;
BA_ "GenSigCycleTime" SG_ 185 CAN_VEHICLE_MODE 10;
BA_ "GenSigSendType" SG_ 185 CAN_YAW_RATE 0;
BA_ "GenSigCycleTime" SG_ 185 CAN_YAW_RATE 10;
BA_ "GenSigSendType" SG_ 185 CAN_YAW_RATE_VALIDITY 0;
BA_ "GenSigCycleTime" SG_ 185 CAN_YAW_RATE_VALIDITY 10;
BA_ "GenSigSendType" SG_ 185 CAN_STEERING_ANGLE_SIGN 0;
BA_ "GenSigCycleTime" SG_ 185 CAN_STEERING_ANGLE_SIGN 10;
BA_ "GenSigSendType" SG_ 185 CAN_VEHICLE_SPEED 0;
BA_ "GenSigCycleTime" SG_ 185 CAN_VEHICLE_SPEED 10;
BA_ "GenSigSendType" SG_ 185 CAN_VEHICLE_SPEED_DIRECTION 0;
BA_ "GenSigCycleTime" SG_ 185 CAN_VEHICLE_SPEED_DIRECTION 10;
BA_ "GenSigSendType" SG_ 185 CAN_VEHICLE_SPEED_VALIDITY 0;
BA_ "GenSigCycleTime" SG_ 185 CAN_VEHICLE_SPEED_VALIDITY 10;
BA_ "GenSigSendType" SG_ 185 CAN_CADM_DrivingDirection 0;
BA_ "GenSigCycleTime" SG_ 185 CAN_CADM_DrivingDirection 10;
BA_ "GenSigSendType" SG_ 185 CAN_VEHICLE_STAT 0;
BA_ "GenSigCycleTime" SG_ 185 CAN_VEHICLE_STAT 10;
BA_ "GenSigSendType" SG_ 185 CAN_VEHICLE_SPEED_CALC 0;
BA_ "GenSigCycleTime" SG_ 185 CAN_VEHICLE_SPEED_CALC 10;
BA_ "GenSigCmt" SG_ 185 CAN_VEHICLE_SPEED_CALC "Contains the compensated vehicle speed used within the FCR";
BA_ "GenSigSendType" SG_ 185 CAN_VEHICLE_SPEED_CALC_QF 0;
BA_ "GenSigCycleTime" SG_ 185 CAN_VEHICLE_SPEED_CALC_QF 10;
BA_ "GenSigCmt" SG_ 185 CAN_VEHICLE_SPEED_CALC_QF "Quality factor of the CAN_VEHICLE_SPEED_CALC";
BA_ "GenSigStartValue" SG_ 185 CAN_YAW_RATE_CALC 3200;
BA_ "GenSigSendType" SG_ 185 CAN_YAW_RATE_CALC 0;
BA_ "GenSigCycleTime" SG_ 185 CAN_YAW_RATE_CALC 10;
BA_ "GenSigCmt" SG_ 185 CAN_YAW_RATE_CALC "Contains the bias-compensated yaw rate";
BA_ "GenSigSendType" SG_ 185 CAN_YAW_RATE_CALC_QF 0;
BA_ "GenSigCycleTime" SG_ 185 CAN_YAW_RATE_CALC_QF 10;
BA_ "GenSigCmt" SG_ 185 CAN_YAW_RATE_CALC_QF "Quality factor of the CAN_YAW_RATE_CALC signal";
BA_ "GenSigSendType" SG_ 185 VEH_STATE_MSG_CRC 0;
BA_ "GenSigCycleTime" SG_ 185 VEH_STATE_MSG_CRC 10;
BA_ "GenSigSendType" SG_ 185 VEH_STATE_MSG_MC 0;
BA_ "GenSigCycleTime" SG_ 185 VEH_STATE_MSG_MC 10;
BA_ "GenSigSendType" SG_ 185 Yaw_Rate_Reference_Valid 0;
BA_ "GenSigVtEn" SG_ 185 Yaw_Rate_Reference_Valid "TRUE";
BA_ "SignalDescription" SG_ 185 Yaw_Rate_Reference_Valid "yaw rate reference validity";
BA_ "GenSigCycleTime" SG_ 185 Yaw_Rate_Reference_Valid 10;
BA_ "GenSigSendType" SG_ 185 Yaw_Rate_Reference 0;
BA_ "SignalDescription" SG_ 185 Yaw_Rate_Reference "Yaw rate reference";
BA_ "GenSigCycleTime" SG_ 185 Yaw_Rate_Reference 10;
BA_ "GenSigSendType" SG_ 185 CAN_VEH_LONG_ACCEL_QF 0;
BA_ "GenSigVtEn" SG_ 185 CAN_VEH_LONG_ACCEL_QF "TRUE";
BA_ "SignalDescription" SG_ 185 CAN_VEH_LONG_ACCEL_QF "Vehicle longitudinal acceleration quality factor";
BA_ "GenSigCycleTime" SG_ 185 CAN_VEH_LONG_ACCEL_QF 10;
BA_ "GenSigSendType" SG_ 185 CAN_VEH_LONG_ACCEL 0;
BA_ "GenSigStartValue" SG_ 185 CAN_VEH_LONG_ACCEL 4000;
BA_ "SignalDescription" SG_ 185 CAN_VEH_LONG_ACCEL "Vehicle longitudinal acceleration";
BA_ "GenSigCycleTime" SG_ 185 CAN_VEH_LONG_ACCEL 10;
BA_ "GenSigSendType" SG_ 185 CAN_STEERING_WHL_ANGLE 0;
BA_ "GenSigStartValue" SG_ 185 CAN_STEERING_WHL_ANGLE 16000;
BA_ "SignalDescription" SG_ 185 CAN_STEERING_WHL_ANGLE "Steering wheel angle";
BA_ "GenSigCycleTime" SG_ 185 CAN_STEERING_WHL_ANGLE 10;
BA_ "GenSigSendType" SG_ 185 CAN_STEERING_WHL_ANGLE_QF 0;
BA_ "GenSigVtEn" SG_ 185 CAN_STEERING_WHL_ANGLE_QF "TRUE";
BA_ "SignalDescription" SG_ 185 CAN_STEERING_WHL_ANGLE_QF "Steering wheel angle quality factor";
BA_ "GenSigCycleTime" SG_ 185 CAN_STEERING_WHL_ANGLE_QF 10;
BA_ "GenSigSendType" SG_ 185 CAN_BRAKE_PEDAL 0;
BA_ "GenSigVtEn" SG_ 185 CAN_BRAKE_PEDAL "TRUE";
BA_ "SignalDescription" SG_ 185 CAN_BRAKE_PEDAL "Brake pedal";
BA_ "GenSigCycleTime" SG_ 185 CAN_BRAKE_PEDAL 10;
BA_ "GenSigSendType" SG_ 185 CAN_TURN_SIGNAL_STATUS 0;
BA_ "GenSigVtEn" SG_ 185 CAN_TURN_SIGNAL_STATUS "TRUE";
BA_ "SignalDescription" SG_ 185 CAN_TURN_SIGNAL_STATUS "Turn signal status";
BA_ "GenSigCycleTime" SG_ 185 CAN_TURN_SIGNAL_STATUS 10;
BA_ "GenSigCycleTime" SG_ 66 LRRF1_CAN_SEQUENCE_NUMBER 1000;
BA_ "GenSigSendType" SG_ 66 LRRF1_CAN_SEQUENCE_NUMBER 0;
BA_ "SignalDescription" SG_ 66 LRRF1_CAN_SEQUENCE_NUMBER "Sequence number";
BA_ "GenSigCycleTime" SG_ 66 LRRF1_CAN_SERIAL_NUMBER 1000;
BA_ "SignalDescription" SG_ 66 LRRF1_CAN_SERIAL_NUMBER "Serial number in BCD format ";
BA_ "GenSigSendType" SG_ 66 LRRF1_CAN_SERIAL_NUMBER 0;
BA_ "SignalDescription" SG_ 12 LRRF1_CAN_INST_MODE "Instrumentation mode";
BA_ "GenSigVtEn" SG_ 12 LRRF1_CAN_INST_MODE "TRUE";
BA_ "GenSigSendType" SG_ 12 LRRF1_CAN_INST_MODE 1;
BA_ "SignalDescription" SG_ 67 LRRF1_CAN_USC_SECTION_COMPTBLITY "Indicates if the USC calibration is compatible with previous versions";
BA_ "GenSigSendType" SG_ 67 LRRF1_CAN_USC_SECTION_COMPTBLITY 0;
BA_ "GenSigCycleTime" SG_ 67 LRRF1_CAN_USC_SECTION_COMPTBLITY 1000;
BA_ "GenSigCycleTime" SG_ 67 LRRF1_CAN_PCAN_PROMOTE_LRRF1 1000;
BA_ "GenSigSendType" SG_ 67 LRRF1_CAN_PCAN_PROMOTE_LRRF1 0;
BA_ "SignalDescription" SG_ 67 LRRF1_CAN_PCAN_MINOR_LRRF1 "PCAN protocol minor version used by the LRRF1";
BA_ "GenSigCycleTime" SG_ 67 LRRF1_CAN_PCAN_MINOR_LRRF1 1000;
BA_ "GenSigSendType" SG_ 67 LRRF1_CAN_PCAN_MINOR_LRRF1 0;
BA_ "SignalDescription" SG_ 67 LRRF1_CAN_PCAN_MAJOR_LRRF1 "PCAN protocol major version used by the LRRF1";
BA_ "GenSigCycleTime" SG_ 67 LRRF1_CAN_PCAN_MAJOR_LRRF1 1000;
BA_ "GenSigSendType" SG_ 67 LRRF1_CAN_PCAN_MAJOR_LRRF1 0;
BA_ "GenSigCycleTime" SG_ 67 LRRF1_Core_Radar_BB_Version_Majo 1000;
BA_ "GenSigSendType" SG_ 67 LRRF1_Core_Radar_BB_Version_Majo 0;
BA_ "SystemSignalLongSymbol" SG_ 67 LRRF1_Core_Radar_BB_Version_Majo "LRRF1_Core_Radar_BB_Version_Major";
BA_ "GenSigCycleTime" SG_ 67 LRRF1_CAN_Dyn_Align_Algorithm_Ve 1000;
BA_ "GenSigSendType" SG_ 67 LRRF1_CAN_Dyn_Align_Algorithm_Ve 0;
BA_ "SystemSignalLongSymbol" SG_ 67 LRRF1_CAN_Dyn_Align_Algorithm_Ve "LRRF1_CAN_Dyn_Align_Algorithm_Version_Promote";
BA_ "GenSigCycleTime" SG_ 67 LRRF1_CAN_Dyn_Align_Algorit_0000 1000;
BA_ "GenSigSendType" SG_ 67 LRRF1_CAN_Dyn_Align_Algorit_0000 0;
BA_ "SystemSignalLongSymbol" SG_ 67 LRRF1_CAN_Dyn_Align_Algorit_0000 "LRRF1_CAN_Dyn_Align_Algorithm_Version_Minor";
BA_ "GenSigCycleTime" SG_ 67 LRRF1_CAN_Dyn_Align_Algorit_0001 1000;
BA_ "GenSigSendType" SG_ 67 LRRF1_CAN_Dyn_Align_Algorit_0001 0;
BA_ "SystemSignalLongSymbol" SG_ 67 LRRF1_CAN_Dyn_Align_Algorit_0001 "LRRF1_CAN_Dyn_Align_Algorithm_Version_Major";
BA_ "GenSigSendType" SG_ 67 LRRF1_Core_Radar_BB_Version_Fiel 0;
BA_ "GenSigCycleTime" SG_ 67 LRRF1_Core_Radar_BB_Version_Fiel 1000;
BA_ "SystemSignalLongSymbol" SG_ 67 LRRF1_Core_Radar_BB_Version_Fiel "LRRF1_Core_Radar_BB_Version_Field";
BA_ "GenSigCycleTime" SG_ 67 LRRF1_Core_Radar_BB_Version_Prom 1000;
BA_ "GenSigSendType" SG_ 67 LRRF1_Core_Radar_BB_Version_Prom 0;
BA_ "SystemSignalLongSymbol" SG_ 67 LRRF1_Core_Radar_BB_Version_Prom "LRRF1_Core_Radar_BB_Version_Promote";
BA_ "GenSigCycleTime" SG_ 67 LRRF1_Core_Radar_BB_Version_Mino 1000;
BA_ "GenSigSendType" SG_ 67 LRRF1_Core_Radar_BB_Version_Mino 0;
BA_ "SystemSignalLongSymbol" SG_ 67 LRRF1_Core_Radar_BB_Version_Mino "LRRF1_Core_Radar_BB_Version_Minor";
BA_ "GenSigCycleTime" SG_ 67 LRRF1_CAN_USC_Field 1000;
BA_ "GenSigSendType" SG_ 67 LRRF1_CAN_USC_Field 0;
BA_ "GenSigCycleTime" SG_ 67 LRRF1_CAN_SMC_Field 1000;
BA_ "GenSigSendType" SG_ 67 LRRF1_CAN_SMC_Field 0;
BA_ "GenSigCycleTime" SG_ 67 LRRF1_CAN_USC_Major 1000;
BA_ "GenSigSendType" SG_ 67 LRRF1_CAN_USC_Major 0;
BA_ "GenSigCycleTime" SG_ 67 LRRF1_CAN_USC_Minor 1000;
BA_ "GenSigSendType" SG_ 67 LRRF1_CAN_USC_Minor 0;
BA_ "GenSigCycleTime" SG_ 67 LRRF1_CAN_USC_Promote 1000;
BA_ "GenSigSendType" SG_ 67 LRRF1_CAN_USC_Promote 0;
BA_ "GenSigCycleTime" SG_ 67 LRRF1_CAN_SMC_Major 1000;
BA_ "GenSigSendType" SG_ 67 LRRF1_CAN_SMC_Major 0;
BA_ "GenSigCycleTime" SG_ 67 LRRF1_CAN_SMC_Minor 1000;
BA_ "GenSigSendType" SG_ 67 LRRF1_CAN_SMC_Minor 0;
BA_ "GenSigCycleTime" SG_ 67 LRRF1_CAN_SMC_Promote 1000;
BA_ "GenSigSendType" SG_ 67 LRRF1_CAN_SMC_Promote 0;
BA_ "GenSigCycleTime" SG_ 67 LRRF1_CAN_PBL_Field_Revision 1000;
BA_ "GenSigSendType" SG_ 67 LRRF1_CAN_PBL_Field_Revision 0;
BA_ "GenSigCycleTime" SG_ 67 LRRF1_CAN_PBL_Promote_Revision 1000;
BA_ "GenSigSendType" SG_ 67 LRRF1_CAN_PBL_Promote_Revision 0;
BA_ "GenSigCycleTime" SG_ 67 LRRF1_CAN_SW_Field_Revision 1000;
BA_ "GenSigSendType" SG_ 67 LRRF1_CAN_SW_Field_Revision 0;
BA_ "GenSigCycleTime" SG_ 67 LRRF1_CAN_SW_Promote_Revision 1000;
BA_ "GenSigSendType" SG_ 67 LRRF1_CAN_SW_Promote_Revision 0;
BA_ "GenSigCycleTime" SG_ 67 LRRF1_CAN_SW_Field 1000;
BA_ "GenSigSendType" SG_ 67 LRRF1_CAN_SW_Field 0;
BA_ "GenSigCycleTime" SG_ 67 LRRF1_CAN_SW_Release_Revision 1000;
BA_ "GenSigSendType" SG_ 67 LRRF1_CAN_SW_Release_Revision 0;
BA_ "GenSigCycleTime" SG_ 67 LRRF1_CAN_PBL_Release_Revision 1000;
BA_ "GenSigSendType" SG_ 67 LRRF1_CAN_PBL_Release_Revision 0;
BA_ "GenSigCycleTime" SG_ 15 LRRF1_CAN_NUMBER_OF_TRACKS_STAT 25;
BA_ "GenSigSendType" SG_ 15 LRRF1_CAN_NUMBER_OF_TRACKS_STAT 0;
BA_ "SignalDescription" SG_ 15 LRRF1_CAN_NUMBER_OF_TRACKS_STAT "Number of tracks sent stationary";
BA_ "GenSigCycleTime" SG_ 15 LRRF1_CAN_NUMBER_OF_TRACKS_MOV 25;
BA_ "GenSigSendType" SG_ 15 LRRF1_CAN_NUMBER_OF_TRACKS_MOV 0;
BA_ "SignalDescription" SG_ 15 LRRF1_CAN_NUMBER_OF_TRACKS_MOV "Number of tracks sent moving";
BA_ "GenSigCycleTime" SG_ 15 LRRF1_CAN_TD_SCAN_COUNTER 25;
BA_ "SignalDescription" SG_ 15 LRRF1_CAN_TD_SCAN_COUNTER "Track drop scan counter";
BA_ "GenSigSendType" SG_ 15 LRRF1_CAN_TD_SCAN_COUNTER 0;
BA_ "GenSigCycleTime" SG_ 15 LRRF1_CAN_FOUND_TARGET 25;
BA_ "SignalDescription" SG_ 15 LRRF1_CAN_FOUND_TARGET "Found target flag";
BA_ "GenSigSendType" SG_ 15 LRRF1_CAN_FOUND_TARGET 0;
BA_ "GenSigVtEn" SG_ 15 LRRF1_CAN_FOUND_TARGET "TRUE";
BA_ "GenSigCycleTime" SG_ 15 LRRF1_CAN_BLOCKAGE_TD 25;
BA_ "GenSigSendType" SG_ 15 LRRF1_CAN_BLOCKAGE_TD 0;
BA_ "SignalDescription" SG_ 15 LRRF1_CAN_BLOCKAGE_TD "TD blockage flag";
BA_ "GenSigVtEn" SG_ 15 LRRF1_CAN_BLOCKAGE_TD "TRUE";
BA_ "GenSigSendType" SG_ 1795 k_radar_azimuth_polarity 0;
BA_ "GenSigCycleTime" SG_ 1795 k_radar_azimuth_polarity 1000;
BA_ "GenSigSendType" SG_ 1795 CAN_FA_VERT_UPPER_LIMIT 0;
BA_ "GenSigCycleTime" SG_ 1795 CAN_FA_VERT_UPPER_LIMIT 1000;
BA_ "SignalDescription" SG_ 1795 CAN_FA_VERT_UPPER_LIMIT "Upper limit of LRRF1 FA is in degrees";
BA_ "GenSigSendType" SG_ 1795 CAN_FA_VERT_LOWER_LIMIT 0;
BA_ "GenSigCycleTime" SG_ 1795 CAN_FA_VERT_LOWER_LIMIT 1000;
BA_ "SignalDescription" SG_ 1795 CAN_FA_VERT_LOWER_LIMIT "Lower limit of LRRF1 FA is in degrees";
BA_ "GenSigSendType" SG_ 1795 CAN_FA_VERT_GROUND_OFFSET 0;
BA_ "GenSigCycleTime" SG_ 1795 CAN_FA_VERT_GROUND_OFFSET 1000;
BA_ "SignalDescription" SG_ 1795 CAN_FA_VERT_GROUND_OFFSET "Ground Offset for LRRF1 FA is in degrees";
BA_ "GenSigSendType" SG_ 1795 SAT_CAN_ODOMETER 0;
BA_ "GenSigCycleTime" SG_ 1795 SAT_CAN_ODOMETER 1000;
BA_ "GenSigCycleTime" SG_ 1795 SAT_VIN_part3 1000;
BA_ "SignalDescription" SG_ 1795 SAT_VIN_part3 "Vehicle Identification Number Part 3";
BA_ "GenSigSendType" SG_ 1795 SAT_VIN_part3 0;
BA_ "GenSigCycleTime" SG_ 1795 SAT_VIN_part2 1000;
BA_ "SignalDescription" SG_ 1795 SAT_VIN_part2 "Vehicle Identification Number Part 2";
BA_ "GenSigSendType" SG_ 1795 SAT_VIN_part2 0;
BA_ "GenSigCycleTime" SG_ 1795 SAT_VIN_part1 1000;
BA_ "SignalDescription" SG_ 1795 SAT_VIN_part1 "Vehicle Identification Number Part 1";
BA_ "GenSigSendType" SG_ 1795 SAT_VIN_part1 0;
BA_ "GenSigSendType" SG_ 48 VehOverGnd_V_Est 0;
BA_ "GenSigCycleTime" SG_ 48 VehOverGnd_V_Est 25;
BA_ "GenSigSendType" SG_ 48 CAN_sigactualvalues_CRC 0;
BA_ "GenSigCycleTime" SG_ 48 CAN_sigactualvalues_CRC 25;
BA_ "GenSigSendType" SG_ 48 CAN_sigactualvalues_MC 0;
BA_ "GenSigCycleTime" SG_ 48 CAN_sigactualvalues_MC 25;
BA_ "GenSigTimeoutTime_ABS_ESC" SG_ 48 CAN_VEH_BATT_VOLT 300;
BA_ "GenSigCycleTime" SG_ 48 CAN_VEH_BATT_VOLT 25;
BA_ "GenSigSendType" SG_ 48 CAN_VEH_BATT_VOLT 0;
BA_ "GenSigVtEn" SG_ 48 CAN_VEH_BATT_VOLT "TRUE";
BA_ "SignalDescription" SG_ 48 CAN_VEH_BATT_VOLT "Battery Voltage";
BA_ "GenSigCycleTime" SG_ 48 CAN_PRND_POSITION 25;
BA_ "GenSigSendType" SG_ 48 CAN_PRND_POSITION 0;
BA_ "GenSigVtEn" SG_ 48 CAN_PRND_POSITION "TRUE";
BA_ "SignalDescription" SG_ 48 CAN_PRND_POSITION "Gear Position";
BA_ "GenSigCmt" SG_ 48 CAN_PRND_POSITION "Gear Position";
BA_ "GenSigCycleTime" SG_ 48 CAN_Outside_Air_Temp 25;
BA_ "GenSigSendType" SG_ 48 CAN_Outside_Air_Temp 0;
BA_ "GenSigStartValue" SG_ 48 CAN_Outside_Air_Temp 254;
BA_ "SignalDescription" SG_ 48 CAN_Outside_Air_Temp "Ambient Temperature";
BA_ "GenSigCycleTime" SG_ 48 CAN_IGN_STATUS 25;
BA_ "GenSigSendType" SG_ 48 CAN_IGN_STATUS 0;
BA_ "GenSigVtEn" SG_ 48 CAN_IGN_STATUS "TRUE";
BA_ "SignalDescription" SG_ 48 CAN_IGN_STATUS "Ignition Status";
BA_ "SignalDescription" SG_ 72 LRRF1_CAN_SENSOR_FOV_VER "Sensor vertical field of view";
BA_ "GenSigSendType" SG_ 72 LRRF1_CAN_SENSOR_FOV_HOR 1;
BA_ "SignalDescription" SG_ 72 LRRF1_CAN_SENSOR_FOV_HOR "Sensor azimuth field of view";
BA_ "SignalDescription" SG_ 72 LRRF1_CAN_DOPPLER_COVERAGE "Doppler coverage area";
BA_ "SignalDescription" SG_ 72 LRRF1_CAN_RANGE_COVERAGE "Range coverage distance";
BA_ "SystemSignalLongSymbol" SG_ 70 LRRF1_CAN_VRTCL_ALIGN_UPDATES_Nb "LRRF1_CAN_VRTCL_ALIGN_UPDATES_Nbr";
BA_ "GenSigSendType" SG_ 70 LRRF1_CAN_HRZNTL_ALIGN_UPDATES_N 1;
BA_ "SystemSignalLongSymbol" SG_ 70 LRRF1_CAN_HRZNTL_ALIGN_UPDATES_N "LRRF1_CAN_HRZNTL_ALIGN_UPDATES_Nbr";
BA_ "SystemSignalLongSymbol" SG_ 70 LRRF1_Horizontal_Alignment_Statu "LRRF1_Horizontal_Alignment_Status";
BA_ "GenSigStartValue" SG_ 70 LRRF1_Align_Vertical_Ref 511;
BA_ "GenSigStartValue" SG_ 70 LRRF1_Align_Vertical_Angle 511;
BA_ "GenSigStartValue" SG_ 70 LRRF1_Align_Horizontal_Angle 511;
BA_ "GenSigStartValue" SG_ 70 LRRF1_Align_Horizontal_Ref 511;
BA_ "GenSigSendType" SG_ 71 LRRF1_CAN_NUMBER_OF_DET 1;
BA_ "SignalDescription" SG_ 71 LRRF1_CAN_DET_TIME_SINCE_MEAS "Relative time from when the radar measurement was taken until the detection data is sent on CAN";
BA_ "SignalDescription" SG_ 71 LRRF1_CAN_SENSOR_TIME_STAMP "LRRF1 sensor absolute time when the radar measurement was taken";
BA_ "GenSigCycleTime" SG_ 68 LRRF1_CAN_Dolphin_AFC 100;
BA_ "GenSigSendType" SG_ 68 LRRF1_CAN_Dolphin_AFC 0;
BA_ "GenSigSendType" SG_ 68 LRRF1_CAN_Dolphin_Tx3 0;
BA_ "GenSigCycleTime" SG_ 68 LRRF1_CAN_Dolphin_Tx3 100;
BA_ "GenSigSendType" SG_ 68 LRRF1_CAN_Dolphin_Tx2 0;
BA_ "GenSigCycleTime" SG_ 68 LRRF1_CAN_Dolphin_Tx2 100;
BA_ "GenSigSendType" SG_ 68 LRRF1_CAN_1_8_V 0;
BA_ "GenSigCycleTime" SG_ 68 LRRF1_CAN_1_8_V 100;
BA_ "GenSigSendType" SG_ 68 LRRF1_CAN_BATT_VOLTS 0;
BA_ "GenSigCycleTime" SG_ 68 LRRF1_CAN_BATT_VOLTS 100;
BA_ "GenSigSendType" SG_ 68 LRRF1_CAN_1_25_V 0;
BA_ "GenSigCycleTime" SG_ 68 LRRF1_CAN_1_25_V 100;
BA_ "GenSigSendType" SG_ 68 LRRF1_CAN_5_V 0;
BA_ "GenSigCycleTime" SG_ 68 LRRF1_CAN_5_V 100;
BA_ "GenSigSendType" SG_ 68 LRRF1_CAN_1_1_V 0;
BA_ "GenSigCycleTime" SG_ 68 LRRF1_CAN_1_1_V 100;
BA_ "GenSigSendType" SG_ 68 LRRF1_CAN_2_3_V 0;
BA_ "GenSigCycleTime" SG_ 68 LRRF1_CAN_2_3_V 100;
BA_ "GenSigSendType" SG_ 68 LRRF1_CAN_Dolphin_Tx1 0;
BA_ "GenSigCycleTime" SG_ 68 LRRF1_CAN_Dolphin_Tx1 100;
BA_ "GenSigStartValue" SG_ 68 LRRF1_CAN_Dolphin_Tx1 50;
BA_ "GenSigSendType" SG_ 68 LRRF1_CAN_RRU_Temp1 0;
BA_ "GenSigCycleTime" SG_ 68 LRRF1_CAN_RRU_Temp1 100;
BA_ "GenSigSendType" SG_ 92 LRRF1_CAN_DET_Near_TARGET_128 1;
BA_ "SignalDescription" SG_ 92 LRRF1_CAN_DET_Near_TARGET_128 "Near_Target_Discrimination";
BA_ "SignalDescription" SG_ 92 LRRF1_CAN_DET_Near_TARGET_127 "Near_Target_Discrimination";
BA_ "SignalDescription" SG_ 92 LRRF1_Det_CRC_19 "Cyclic Redundancy Check for Detection Message Number 19";
BA_ "SignalDescription" SG_ 92 LRRF1_Det_MC_19 "Message Count for Detection Message Number 19";
BA_ "GenSigStartValue" SG_ 92 LRRF1_CAN_DET_ELEVATION_128 63.8646288209607;
BA_ "SignalDescription" SG_ 92 LRRF1_CAN_DET_ELEVATION_128 "Detected object elevation position 128";
BA_ "SignalDescription" SG_ 92 LRRF1_CAN_DET_SUPER_RES_TARGET_1 "Super resolution target 128";
BA_ "SystemSignalLongSymbol" SG_ 92 LRRF1_CAN_DET_SUPER_RES_TARGET_1 "LRRF1_CAN_DET_SUPER_RES_TARGET_128";
BA_ "GenSigStartValue" SG_ 92 LRRF1_CAN_DET_AZIMUTH_128 8194.05320813772;
BA_ "SignalDescription" SG_ 92 LRRF1_CAN_DET_AZIMUTH_128 "Detected object azimuth position 128";
BA_ "SignalDescription" SG_ 92 LRRF1_CAN_DET_HOST_VEH_CLUTTER_1 "Host vehicle clutter 128";
BA_ "SystemSignalLongSymbol" SG_ 92 LRRF1_CAN_DET_HOST_VEH_CLUTTER_1 "LRRF1_CAN_DET_HOST_VEH_CLUTTER_128";
BA_ "SignalDescription" SG_ 92 LRRF1_CAN_DET_CONFID_ELEVATION_1 "Elevation Angle Confidence 128";
BA_ "SystemSignalLongSymbol" SG_ 92 LRRF1_CAN_DET_CONFID_ELEVATION_1 "LRRF1_CAN_DET_CONFID_ELEVATION_128";
BA_ "SignalDescription" SG_ 92 LRRF1_CAN_DET_RANGE_128 "Detected object range 128";
BA_ "GenSigVtEn" SG_ 92 LRRF1_CAN_DET_CONFID_AZIMUTH_128 "TRUE";
BA_ "SignalDescription" SG_ 92 LRRF1_CAN_DET_CONFID_AZIMUTH_128 "Signal to noise level 128";
BA_ "GenSigStartValue" SG_ 92 LRRF1_CAN_DET_RANGE_RATE_128 8192;
BA_ "SignalDescription" SG_ 92 LRRF1_CAN_DET_RANGE_RATE_128 "Detected object range rate 128";
BA_ "SignalDescription" SG_ 92 LRRF1_CAN_SCAN_INDEX_2LSB_128 "The two LSB of scan index 128";
BA_ "SignalDescription" SG_ 92 LRRF1_CAN_DET_AMPLITUDE_128 "Detected object amplitude 128";
BA_ "SignalDescription" SG_ 92 LRRF1_CAN_DET_VALID_LEVEL_128 "Detected object valid level 128";
BA_ "GenSigStartValue" SG_ 92 LRRF1_CAN_DET_ELEVATION_127 63.8646288209607;
BA_ "SignalDescription" SG_ 92 LRRF1_CAN_DET_ELEVATION_127 "Detected object elevation position 127";
BA_ "GenSigVtEn" SG_ 92 LRRF1_CAN_DET_CONFID_AZIMUTH_127 "TRUE";
BA_ "SignalDescription" SG_ 92 LRRF1_CAN_DET_CONFID_AZIMUTH_127 "Signal to noise level 127";
BA_ "SignalDescription" SG_ 92 LRRF1_CAN_DET_SUPER_RES_TAR_0006 "Super resolution target 127";
BA_ "SystemSignalLongSymbol" SG_ 92 LRRF1_CAN_DET_SUPER_RES_TAR_0006 "LRRF1_CAN_DET_SUPER_RES_TARGET_127";
BA_ "SignalDescription" SG_ 92 LRRF1_CAN_DET_CONFID_ELEVAT_0006 "Elevation Angle Confidence 127";
BA_ "SystemSignalLongSymbol" SG_ 92 LRRF1_CAN_DET_CONFID_ELEVAT_0006 "LRRF1_CAN_DET_CONFID_ELEVATION_127";
BA_ "SignalDescription" SG_ 92 LRRF1_CAN_DET_HOST_VEH_CLUT_0006 "Host vehicle clutter 127";
BA_ "SystemSignalLongSymbol" SG_ 92 LRRF1_CAN_DET_HOST_VEH_CLUT_0006 "LRRF1_CAN_DET_HOST_VEH_CLUTTER_127";
BA_ "SignalDescription" SG_ 92 LRRF1_CAN_DET_VALID_LEVEL_127 "Detected object valid level 127";
BA_ "GenSigStartValue" SG_ 92 LRRF1_CAN_DET_AZIMUTH_127 8194.05320813772;
BA_ "SignalDescription" SG_ 92 LRRF1_CAN_DET_AZIMUTH_127 "Detected object azimuth position 127";
BA_ "SignalDescription" SG_ 92 LRRF1_CAN_DET_RANGE_127 "Detected object range 127";
BA_ "GenSigStartValue" SG_ 92 LRRF1_CAN_DET_RANGE_RATE_127 8192;
BA_ "SignalDescription" SG_ 92 LRRF1_CAN_DET_RANGE_RATE_127 "Detected object range rate 127";
BA_ "SignalDescription" SG_ 92 LRRF1_CAN_DET_AMPLITUDE_127 "Detected object amplitude 127";
BA_ "SignalDescription" SG_ 92 LRRF1_CAN_SCAN_INDEX_2LSB_127 "The two LSB of scan index 127";
VAL_ 954 MRR_RL_Radar_Reset 1 "Logic high  - Normal Operaton/Deafult " 0 "Reset Pending" ;
VAL_ 1978 MRR_RR_Radar_Reset 1 "Normal Operation/Default " 0 "Reset Pending" ;
VAL_ 93 LRRF1_Radar_Reset 1 "Normal Operaton/Deafult " 0 "Reset Pending" ;
VAL_ 35 LRRF1_Dolphin_Fault_Detection 2 "Dolphin Sensor Dead" 1 "Dolphin Start_up Error" 0 "No Faults" ;
VAL_ 1797 LRRF1_Radar_CfgType 2 "CADM L2+: 5 Radar" 1 "CADM Lo: 5 Radar" 0 "CADM Lo: 3 Radar" ;
VAL_ 1797 SensorCfg_LRRF_Orientation 255 "-1 connector up (Upside Down)" 1 "+1 connector down (Normal Orientation)" ;
VAL_ 81 LRRF1_CAN_DET_CONFID_AZIMUTH_51 3 "Low" 2 "Medium_Low" 1 "Medium_High" 0 "High" ;
VAL_ 81 LRRF1_CAN_DET_CONFID_AZIMUTH_52 3 "Low" 2 "Medium_Low" 1 "Medium_High" 0 "High" ;
VAL_ 81 LRRF1_CAN_DET_CONFID_AZIMUTH_53 3 "Low" 2 "Medium_Low" 1 "Medium_High" 0 "High" ;
VAL_ 81 LRRF1_CAN_DET_CONFID_AZIMUTH_54 3 "Low" 2 "Medium_Low" 1 "Medium_High" 0 "High" ;
VAL_ 81 LRRF1_CAN_DET_CONFID_AZIMUTH_55 3 "Low" 2 "Medium_Low" 1 "Medium_High" 0 "High" ;
VAL_ 81 LRRF1_CAN_DET_CONFID_AZIMUTH_56 3 "Low" 2 "Medium_Low" 1 "Medium_High" 0 "High" ;
VAL_ 81 LRRF1_CAN_DET_CONFID_AZIMUTH_50 3 "Low" 2 "Medium_Low" 1 "Medium_High" 0 "High" ;
VAL_ 117 LRRF1_CAN_VEHICLE_SPEED_CALC_QF_ 3 "Accurate" 2 "Inaccurate" 1 "Temporarily Undefined" 0 "Undefined" ;
VAL_ 117 LRRF1_CAN_YAW_RATE_CALC_QF_ECHO 3 "Accurate" 2 "Inaccurate" 1 "Temporarily Undefined" 0 "Undefined" ;
VAL_ 126 LRRF1_f_Radar_Unreasonable 1 "Flag set" 0 "No Flag " ;
VAL_ 33 LRRF2_SgnlRationalityCk_Flt 1 "Fault Present" 0 "No Fault" ;
VAL_ 33 LRRF2_PCANDataRangeChk_Flt 1 "Fault Present" 0 "No Fault" ;
VAL_ 33 LRRF1_TO_SystemTDBlockage_Flt 1 "Fault Present" 0 "No Fault" ;
VAL_ 33 LRRF1_TO_CADMSgnlActlVal_Flt 1 "Fault Present" 0 "No Fault" ;
VAL_ 33 LRRF1_TO_TrigControl_Flt 1 "Fault Present" 0 "No Fault" ;
VAL_ 33 LRRF1_TO_VehicleState_Flt 1 "Fault Present" 0 "No Fault" ;
VAL_ 33 LRRF1_RRUBIST_Flt 1 "Fault Present" 0 "No Fault" ;
VAL_ 33 LRRF1_Dolphin_Flt 1 "Fault Present" 0 "No Fault" ;
VAL_ 33 LRRF1_RRUCore_Flt 1 "Fault Present" 0 "No Fault" ;
VAL_ 33 LRRF1_PCANDataRangeChk_Flt 1 "Fault Present" 0 "No Fault" ;
VAL_ 33 LRRF1_VINSignalCompare_Flt 1 "Fault Present" 0 "No Fault" ;
VAL_ 33 LRRF1_BatteryLow_Flt 1 "Fault Present" 0 "No Fault" ;
VAL_ 33 LRRF1_BatteryHigh_Flt 1 "Fault Present" 0 "No Fault" ;
VAL_ 33 LRRF1_Core1_To_Core0_IPC_Flt 1 "Fault Present" 0 "No Fault" ;
VAL_ 33 LRRF1_Core0_To_Core1_IPC_Flt 1 "Fault Present" 0 "No Fault " ;
VAL_ 33 LRRF1_Core1_To_Core2_IPC_Flt 1 "Fault Present" 0 "No Fault" ;
VAL_ 33 LRRF1_Core2_To_Core1_IPC_Flt 1 "Fault Present" 0 "No Fault" ;
VAL_ 33 LRRF1_Core2_To_Core0_IPC_Flt 1 "Fault Present" 0 "No Fault" ;
VAL_ 33 LRRF1_Core2Halted_Flt 1 "Fault Present" 0 "No Fault" ;
VAL_ 33 LRRF1_Core1Halted_Flt 1 "Fault Present" 0 "No Fault" ;
VAL_ 33 LRRF1_LocalOscPower_Flt 1 "Fault Present" 0 "No Fault" ;
VAL_ 33 LRRF1_DSPLoopOverrun_Flt 1 "Fault Present" 0 "No Fault" ;
VAL_ 33 LRRF1_TransmitterPower_Flt 1 "Fault Present" 0 "No Fault" ;
VAL_ 33 LRRF1_Core0_To_Core2_IPC_Flt 1 "Fault Present" 0 "No Fault" ;
VAL_ 33 LRRF1_XCVRDeviceSPI_Flt 1 "Fault Present" 0 "No Fault" ;
VAL_ 33 LRRF1_SidelobeBlockage_Flt 1 "Fault Present" 0 "No Fault" ;
VAL_ 33 LRRF1_MNRBlockage_Flt 1 "Fault Present" 0 "No Fault" ;
VAL_ 33 LRRF1_TransmitterTempHigh_Flt 1 "Fault Present" 0 "No Fault" ;
VAL_ 33 LRRF1_AlignRoutineFailed_Flt 1 "Fault Present" 0 "No Fault" ;
VAL_ 33 LRRF1_MicroTempHigh_Flt 1 "Fault Present" 0 "No Fault" ;
VAL_ 33 LRRF1_FactoryAlignmentMode_Flt 1 "Fault Present" 0 "No Fault" ;
VAL_ 33 LRRF1_VAlignOutofRange_Flt 1 "Fault Present" 0 "No Fault" ;
VAL_ 33 LRRF1_HAlignOutofRange_Flt 1 "Fault Present" 0 "No Fault" ;
VAL_ 33 LRRF1_v1p1_SupplyOutOfRange_Flt 1 "Fault Present" 0 "No Fault" ;
VAL_ 33 LRRF1_v1p25_SupplyOutOfRange_Flt 1 "Fault Present" 0 "No Fault" ;
VAL_ 33 LRRF1_v1p8_SupplyOutOfRange_Flt 1 "Fault Present" 0 "No Fault" ;
VAL_ 33 LRRF1_v2p3_SupplyOutOfRange_Flt 1 "Fault Present" 0 "No Fault" ;
VAL_ 33 LRRF1_v_5_SupplyOutOfRange_Flt 1 "Fault Present" 0 "No Fault" ;
VAL_ 33 LRRF1_TransmitterID_Flt 1 "Fault Present" 0 "No Fault" ;
VAL_ 33 LRRF1_PCANBusOff_Flt 1 "Fault Present" 0 "No Fault" ;
VAL_ 33 LRRF1_InstructionSetCheck_Flt 1 "Fault Present" 0 "No Fault" ;
VAL_ 33 LRRF1_StackOverflow_Flt 1 "Fault Present" 0 "No Fault" ;
VAL_ 33 LRRF1_Watchdog_Flt 0 "No Fault" 1 "Fault Present" ;
VAL_ 33 LRRF1_PLLLock_Flt 1 "Fault Present" 0 "No Fault" ;
VAL_ 33 LRRF1_RAMMemoryTest_Flt 1 "Fault Present" 0 "No Fault" ;
VAL_ 33 LRRF1_USCValidation_Flt 1 "Fault Present" 0 "No Fault" ;
VAL_ 33 LRRF1_SMC_Checksum_Flt 1 "Fault Present" 0 "No Fault" ;
VAL_ 33 LRRF1_KeepAliveChecksum_Flt 1 "Fault Present" 0 "No Fault" ;
VAL_ 33 LRRF1_ApplicationFlashChksum_Flt 1 "Fault Present" 0 "No Fault" ;
VAL_ 185 CAN_CADM_Master 3 "Error" 2 "CADM MAP" 1 "CADM MID" 0 "No request - (Default MID or  LO in single CADM)" ;
VAL_ 185 CAN_WIPER_STATUS 1 "On" 0 "Off" ;
VAL_ 185 CAN_VEHICLE_MODE 1 "MODE_ROLLING " 0 "STANDARD_MODE " ;
VAL_ 185 CAN_YAW_RATE_VALIDITY 1 "Veh Yaw Rate Available or Valid" 0 "No Vehicle Yaw Rate or Invalid" ;
VAL_ 185 CAN_VEHICLE_SPEED_DIRECTION 1 "Reverse" 0 "Forward" ;
VAL_ 185 CAN_VEHICLE_SPEED_VALIDITY 1 "Valid" 0 "Invalid" ;
VAL_ 185 CAN_CADM_DrivingDirection 3 "Unknown/Error" 2 "Forward" 1 "Backward" 0 "Standstill" ;
VAL_ 185 CAN_VEHICLE_STAT 1 "Yes" 0 "No" ;
VAL_ 185 CAN_VEHICLE_SPEED_CALC_QF 3 "Accurate" 2 "Innaccurate" 1 "Temporarily Undefined" 0 "Undefined" ;
VAL_ 185 CAN_YAW_RATE_CALC_QF 3 "Accurate" 2 "Innaccurate" 1 "Temporarily Undefined" 0 "Undefined" ;
VAL_ 185 Yaw_Rate_Reference_Valid 1 "Valid" 0 "Invalid" ;
VAL_ 185 CAN_VEH_LONG_ACCEL_QF 3 "Accurate" 2 "Innacurate" 1 "Temporarily Undefined" 0 "Undefined (faulty)" ;
VAL_ 185 CAN_STEERING_WHL_ANGLE_QF 1 "Valid" 0 "Invalid" ;
VAL_ 185 CAN_BRAKE_PEDAL 2 "Pressed" 1 "Not Pressed" 0 "Unknown" ;
VAL_ 185 CAN_TURN_SIGNAL_STATUS 3 "Left and Rigth, both on" 2 "Right" 1 "Left" 0 "None" ;
VAL_ 12 LRRF1_CAN_INST_MODE 43605 "Instrumentation mode is set" ;
VAL_ 15 LRRF1_CAN_FOUND_TARGET 1 "Target found" 0 "Target not found" ;
VAL_ 15 LRRF1_CAN_BLOCKAGE_TD 1 "TD blockage" 0 "No blockage" ;
VAL_ 1795 SAT_CAN_ODOMETER 16777216 "Description for the value '0x1000000'" 16777215 "Invalid" ;
VAL_ 48 VehOverGnd_V_Est 65535 "Invalid" 65534 "Unknown" ;
VAL_ 48 CAN_VEH_BATT_VOLT 255 "Fault" ;
VAL_ 48 CAN_PRND_POSITION 15 "Fault" 14 "Unknown_Position" 13 "NotUsed_2" 12 "NotUsed_1" 11 "sixth" 10 "fifth" 9 "fourth" 8 "third" 7 "second" 6 "first" 5 "Low" 4 "Sport_DriveSport" 3 "Drive" 2 "Neutral" 1 "Reverse" 0 "Park" ;
VAL_ 48 CAN_IGN_STATUS 15 "Invalid" 8 "Start" 4 "Run" 2 "Accessory" 1 "Off" 0 "Unknown" ;
VAL_ 70 LRRF1_Horizontal_Alignment_Statu 15 "Undefined" 14 "Undefined" 13 "Low Amplitude (Flat-plate only)" 12 "No Peak (Flat-plate only)" 11 "Fail Ver and Hor OutOfRange" 10 "Fail Vertical Align OutOfRange" 9 "Fail Horizontal Align OutOfRange" 8 "Fail Time Out" 7 "Fail Only Right Target Found" 6 "Fail Only Left Target Found" 5 "Fail Variance Too Large" 4 "Fail Deviation Too Large" 3 "Fail No Target" 2 "Success" 1 "Busy" 0 "Off" ;
VAL_ 70 LRRF1_Vertical_Alignment_Status 15 "Undefined" 14 "Undefined" 13 "Low Amplitude (Flat-plate only)" 12 "No Peak (Flat-plate only)" 11 "Fail Ver and Hor OutOfRange" 10 "Fail Vertical Align OutOfRange" 9 "Fail Horizontal Align OutOfRange" 8 "Fail Time Out" 7 "Fail Only Right Target Found" 6 "Fail Only Left Target Found" 5 "Fail Variance Too Large" 4 "Fail Deviation Too Large" 3 "Fail No Target" 2 "Success" 1 "Busy" 0 "Off" ;
VAL_ 70 LRRF1_Vertical_Alignment_State 6 "Static alignment flat-plate" 5 "Static alignment 2-target" 4 "Static alignment 1-target" 3 "Service alignment" 2 "Short track alignment" 1 "Auto alignment" 0 "Off" ;
VAL_ 70 LRRF1_Horizontal_Alignment_State 6 "Static alignment flat-plate" 5 "Static alignment 2-target" 4 "Static alignment 1-target" 3 "Service alignment" 2 "Short track alignment" 1 "Auto alignment" 0 "Off" ;
VAL_ 70 LRRF1_Align_Vertical_QF 3 "Accurate" 2 "Innacurate" 1 "Temporarily undefined (Faulty)" 0 "Undefined" ;
VAL_ 70 LRRF1_Align_Horizontal_QF 3 "Accurate" 2 "Innacurate" 1 "Temporarily undefined (Faulty)" 0 "Undefined" ;
VAL_ 71 LRRF1_CAN_LOOK_ID 4 "DIAGNOSTIC_LOOK" 3 "RADAR_CTRL_MR_ML" 2 "RADAR_CTRL_MR_LL" 1 "RADAR_CTRL_LR_ML" 0 "RADAR_CTRL_LR_LL" ;
VAL_ 92 LRRF1_CAN_DET_CONFID_AZIMUTH_128 3 "Low" 2 "Medium_Low" 1 "Medium_High" 0 "High" ;
VAL_ 92 LRRF1_CAN_DET_CONFID_AZIMUTH_127 3 "Low" 2 "Medium_Low" 1 "Medium_High" 0 "High" ;
SIG_GROUP_ 39 MRR_RR_Angle_Adjustment_Table 1 : MRR_RR_AAT_CRC MRR_RR_AAT_MC MRR_RR_POS_80 MRR_RR_POS_70 MRR_RR_POS_60 MRR_RR_POS_50 MRR_RR_POS_40 MRR_RR_POS_30 MRR_RR_POS_20 MRR_RR_POS_10 MRR_RR_0 MRR_RR_NEG_10 MRR_RR_NEG_20 MRR_RR_NEG_30 MRR_RR_NEG_40 MRR_RR_NEG_50 MRR_RR_NEG_60 MRR_RR_NEG_70 MRR_RR_NEG_80;
SIG_GROUP_ 38 MRR_RL_Angle_Adjustment_Table 1 : MRR_RL_AAT_CRC MRR_RL_AAT_MC MRR_RL_POS_80 MRR_RL_POS_70 MRR_RL_POS_60 MRR_RL_POS_50 MRR_RL_POS_40 MRR_RL_POS_30 MRR_RL_POS_20 MRR_RL_POS_10 MRR_RL_0 MRR_RL_NEG_10 MRR_RL_NEG_20 MRR_RL_NEG_30 MRR_RL_NEG_40 MRR_RL_NEG_50 MRR_RL_NEG_60 MRR_RL_NEG_70 MRR_RL_NEG_80;
SIG_GROUP_ 1797 LRRF1_Radar_Cfg_Parameters 1 : LRRF1_FA_TstTolerancePlateAngNeg LRRF1_FA_TstTolerancePlateAng0 LRRF1_FA_TstTolerancePlateAngPos LRRF1_FA_HorizMisalignLim SensorCfg_LRRF_Orientation LRRF1_FA_Bdgt_Fascia_Attenuation SensorCfg_LRRF_Yaw SensorCfg_LRRF_Pitch SensorCfg_LRRF_VertPos SensorCfg_LRRF_LongPos SensorCfg_LRRF_LatPos LRRF1_SENSR_CFG_CRC SensorCfg_LRRF_AlignRngTolHorz SensorCfg_LRRF_AlignRngTolVert LRRF1_Radar_CfgType LRRF1_FA_Target_Range2Mirror LRRF1_FA_Positive_Angle LRRF1_FA_Negative_Angle;
SIG_GROUP_ 81 LRRF1_Detection_050_056 1 : LRRF1_CAN_DET_Near_TARGET_56 LRRF1_CAN_DET_Near_TARGET_55 LRRF1_CAN_DET_Near_TARGET_54 LRRF1_CAN_DET_Near_TARGET_53 LRRF1_CAN_DET_Near_TARGET_52 LRRF1_CAN_DET_Near_TARGET_51 LRRF1_CAN_DET_Near_TARGET_50 LRRF1_CAN_DET_RANGE_50 LRRF1_CAN_DET_VALID_LEVEL_52 LRRF1_CAN_DET_VALID_LEVEL_51 LRRF1_CAN_DET_AMPLITUDE_51 LRRF1_CAN_DET_VALID_LEVEL_54 LRRF1_CAN_SCAN_INDEX_2LSB_52 LRRF1_CAN_DET_VALID_LEVEL_53 LRRF1_CAN_SCAN_INDEX_2LSB_56 LRRF1_CAN_DET_RANGE_RATE_50 LRRF1_CAN_DET_ELEVATION_50 LRRF1_CAN_DET_SUPER_RES_TAR_0005 LRRF1_CAN_DET_AZIMUTH_50 LRRF1_CAN_DET_CONFID_AZIMUTH_50 LRRF1_CAN_DET_AMPLITUDE_50 LRRF1_CAN_DET_VALID_LEVEL_55 LRRF1_CAN_DET_VALID_LEVEL_56 LRRF1_CAN_DET_AMPLITUDE_52 LRRF1_CAN_SCAN_INDEX_2LSB_51 LRRF1_CAN_DET_RANGE_51 LRRF1_CAN_DET_AMPLITUDE_54 LRRF1_CAN_DET_RANGE_RATE_54 LRRF1_CAN_DET_SUPER_RES_TAR_0004 LRRF1_CAN_DET_SUPER_RES_TAR_0003 LRRF1_CAN_DET_SUPER_RES_TAR_0001 LRRF1_CAN_DET_RANGE_54 LRRF1_CAN_DET_VALID_LEVEL_50 LRRF1_CAN_SCAN_INDEX_2LSB_55 LRRF1_CAN_DET_RANGE_56 LRRF1_CAN_DET_CONFID_ELEVAT_0005 LRRF1_CAN_SCAN_INDEX_2LSB_54 LRRF1_CAN_DET_HOST_VEH_CLUT_0005 LRRF1_CAN_DET_RANGE_53 LRRF1_CAN_SCAN_INDEX_2LSB_50 LRRF1_Det_MC_08 LRRF1_Det_CRC_08 LRRF1_CAN_DET_SUPER_RES_TAR_0002 LRRF1_CAN_DET_AMPLITUDE_53 LRRF1_CAN_DET_ELEVATION_53 LRRF1_CAN_DET_HOST_VEH_CLUT_0003 LRRF1_CAN_DET_HOST_VEH_CLUT_0001 LRRF1_CAN_DET_SUPER_RES_TARGET_5 LRRF1_CAN_DET_HOST_VEH_CLUT_0004 LRRF1_CAN_DET_SUPER_RES_TAR_0000 LRRF1_CAN_DET_RANGE_RATE_56 LRRF1_CAN_DET_RANGE_RATE_52 LRRF1_CAN_DET_HOST_VEH_CLUT_0000 LRRF1_CAN_DET_AZIMUTH_51 LRRF1_CAN_DET_RANGE_RATE_55 LRRF1_CAN_DET_HOST_VEH_CLUT_0002 LRRF1_CAN_DET_RANGE_RATE_51 LRRF1_CAN_DET_HOST_VEH_CLUTTER_5 LRRF1_CAN_DET_AZIMUTH_53 LRRF1_CAN_DET_AMPLITUDE_55 LRRF1_CAN_DET_RANGE_55 LRRF1_CAN_DET_AZIMUTH_52 LRRF1_CAN_DET_AMPLITUDE_56 LRRF1_CAN_SCAN_INDEX_2LSB_53 LRRF1_CAN_DET_ELEVATION_56 LRRF1_CAN_DET_AZIMUTH_54 LRRF1_CAN_DET_ELEVATION_54 LRRF1_CAN_DET_ELEVATION_55 LRRF1_CAN_DET_RANGE_RATE_53 LRRF1_CAN_DET_CONFID_ELEVAT_0003 LRRF1_CAN_DET_AZIMUTH_55 LRRF1_CAN_DET_CONFID_ELEVAT_0000 LRRF1_CAN_DET_CONFID_ELEVAT_0001 LRRF1_CAN_DET_ELEVATION_52 LRRF1_CAN_DET_ELEVATION_51 LRRF1_CAN_DET_CONFID_ELEVAT_0004 LRRF1_CAN_DET_CONFID_ELEVAT_0002 LRRF1_CAN_DET_RANGE_52 LRRF1_CAN_DET_AZIMUTH_56 LRRF1_CAN_DET_CONFID_AZIMUTH_51 LRRF1_CAN_DET_CONFID_ELEVATION_5 LRRF1_CAN_DET_CONFID_AZIMUTH_56 LRRF1_CAN_DET_CONFID_AZIMUTH_52 LRRF1_CAN_DET_CONFID_AZIMUTH_55 LRRF1_CAN_DET_CONFID_AZIMUTH_53 LRRF1_CAN_DET_CONFID_AZIMUTH_54;
SIG_GROUP_ 117 LRRF1_Header_EchoedSysStatus 1 : LRRF1_CAN_COMPENSATED_SIGNALS_US LRRF1_CAN_VEHICLE_SPEED_CALC_ECH LRRF1_CAN_YAW_RATE_CALC_ECHO LRRF1_CAN_YAW_RATE_CALC_QF_ECHO LRRF1_CAN_VEHICLE_SPEED_CALC_QF_ LRRF1_Header_EchoedSysStatus_MC LRRF1_Header_EchoedSysStatus_CRC;
SIG_GROUP_ 33 LRRF1_Active_Faults_Status 1 : LRRF2_SgnlRationalityCk_Flt LRRF2_PCANDataRangeChk_Flt LRRF1_TO_CADMSWVersion_Flt LRRF2_TO_RADARCfgParameter_Flt LRRF2_CRC_VehicleState_Flt LRRF1_SidelobeBlockage_Flt LRRF1_MNRBlockage_Flt LRRF1_TransmitterTempHigh_Flt LRRF1_AlignRoutineFailed_Flt LRRF1_MicroTempHigh_Flt LRRF1_FactoryAlignmentMode_Flt LRRF1_VAlignOutofRange_Flt LRRF1_HAlignOutofRange_Flt LRRF1_v1p1_SupplyOutOfRange_Flt LRRF1_v1p25_SupplyOutOfRange_Flt LRRF1_v1p8_SupplyOutOfRange_Flt LRRF1_v2p3_SupplyOutOfRange_Flt LRRF1_v_5_SupplyOutOfRange_Flt LRRF1_TransmitterID_Flt LRRF1_PCANBusOff_Flt LRRF1_InstructionSetCheck_Flt LRRF1_StackOverflow_Flt LRRF1_Watchdog_Flt LRRF1_PLLLock_Flt LRRF1_RAMMemoryTest_Flt LRRF1_USCValidation_Flt LRRF1_SMC_Checksum_Flt LRRF1_KeepAliveChecksum_Flt LRRF1_ApplicationFlashChksum_Flt LRRF2_MC_CADMSgnlActlVal_Flt LRRF1_TO_RADARCfgParameter_Flt LRRF1_XCVRDeviceSPI_Flt LRRF1_TO_SystemTDBlockage_Flt LRRF1_Core0_To_Core2_IPC_Flt LRRF1_TO_CADMSgnlActlVal_Flt LRRF1_CRC_TrigControl_Flt LRRF1_Core2Halted_Flt LRRF1_TransmitterPower_Flt LRRF1_Core2_To_Core1_IPC_Flt LRRF1_TO_TrigControl_Flt LRRF1_RRUBIST_Flt LRRF1_Core1_To_Core2_IPC_Flt LRRF1_Core1_To_Core0_IPC_Flt LRRF1_Dolphin_Flt LRRF1_TO_VehicleState_Flt LRRF1_MC_CADMSgnlActlVal_Flt LRRF1_MC_VehicleState_Flt LRRF1_MC_TrigControl_Flt LRRF1_CRC_VehicleState_Flt LRRF1_CRC_RadarCfgParameter_Flt LRRF1_BatteryHigh_Flt LRRF1_RRUCore_Flt LRRF1_VINSignalCompare_Flt LRRF1_BatteryLow_Flt LRRF1_LocalOscPower_Flt LRRF1_DSPLoopOverrun_Flt LRRF1_Core1Halted_Flt LRRF1_Core2_To_Core0_IPC_Flt LRRF1_Core0_To_Core1_IPC_Flt LRRF1_PCANDataRangeChk_Flt LRRF1_CRC_CADMSgnlActlVal_Flt LRRF1_TO_SATCADMVIN_Flt LRRF1_TO_CADMTracksChange_Flt LRRF2_CRC_CADMSgnlActlVal_Flt LRRF1_Active_Fault_Status_CRC LRRF2_TO_TDBlockage_Flt LRRF1_Active_Fault_Status_MC LRRF2_TO_CADMTracksChange_Flt LRRF2_TO_CADMSWVersion_Flt LRRF2_MC_VehicleState_Flt LRRF2_TO_TrigControl_Flt LRRF2_TO_VehicleState_Flt LRRF2_CRC_TrigControl_Flt LRRF2_CRC_RadarCfgParameter_Flt LRRF2_MC_TrigControl_Flt LRRF2_TO_CADMSgnlActlVal_Flt LRRF2_TO_SATCADMVIN_Flt LRRF2_PCANBusOff_Flt;
SIG_GROUP_ 185 VEHICLE_STATE_MSG 1 : CAN_CADM_Master CAN_STEERING_ANGLE CAN_WIPER_STATUS CAN_VEHICLE_MODE CAN_YAW_RATE CAN_YAW_RATE_VALIDITY CAN_STEERING_ANGLE_SIGN CAN_VEHICLE_SPEED CAN_VEHICLE_SPEED_DIRECTION CAN_VEHICLE_SPEED_VALIDITY CAN_CADM_DrivingDirection CAN_VEHICLE_STAT CAN_VEHICLE_SPEED_CALC CAN_VEHICLE_SPEED_CALC_QF CAN_YAW_RATE_CALC CAN_YAW_RATE_CALC_QF VEH_STATE_MSG_CRC VEH_STATE_MSG_MC Yaw_Rate_Reference_Valid CAN_VEH_LONG_ACCEL_QF Yaw_Rate_Reference CAN_VEH_LONG_ACCEL CAN_STEERING_WHL_ANGLE CAN_STEERING_WHL_ANGLE_QF CAN_BRAKE_PEDAL CAN_TURN_SIGNAL_STATUS;
SIG_GROUP_ 48 CADM_SignalsActualValues 1 : VehOverGnd_V_Est CAN_sigactualvalues_CRC CAN_sigactualvalues_MC CAN_VEH_BATT_VOLT CAN_PRND_POSITION CAN_Outside_Air_Temp CAN_IGN_STATUS;
SIG_GROUP_ 72 LRRF1_Header_SensorCoverage 1 : LRRF1_Header_SensorCoverage_CRC LRRF1_Header_SensorCoverage_MC LRRF1_CAN_SENSOR_FOV_VER LRRF1_CAN_SENSOR_FOV_HOR LRRF1_CAN_DOPPLER_COVERAGE LRRF1_CAN_RANGE_COVERAGE;
SIG_GROUP_ 70 LRRF1_Header_AlignmentState 1 : LRRF1_CAN_HRZNTL_ALIGN_UPDATES_N LRRF1_CAN_VRTCL_ALIGN_UPDATES_Nb LRRF1_Header_AlignmentState_CRC LRRF1_Header_AlignmentState_MC LRRF1_Horizontal_Alignment_Statu LRRF1_Vertical_Alignment_Status LRRF1_Vertical_Alignment_State LRRF1_Horizontal_Alignment_State LRRF1_Align_Vertical_Ref LRRF1_Align_Vertical_QF LRRF1_Align_Vertical_Angle LRRF1_Align_Horizontal_Angle LRRF1_Align_Horizontal_Ref LRRF1_Align_Horizontal_QF;
SIG_GROUP_ 71 LRRF1_Header_Timestamps 1 : LRRF1_CAN_NUMBER_OF_DET LRRF1_LRRF1_CAN_SCAN_INDEX LRRF1_CAN_LOOK_INDEX LRRF1_CAN_LOOK_ID LRRF1_Header_Timestamps_CRC LRRF1_Header_Timestamps_MC LRRF1_CAN_ReSync_counter LRRF1_CAN_DET_TIME_SINCE_MEAS LRRF1_CAN_SENSOR_TIME_STAMP;
SIG_GROUP_ 92 LRRF1_Detection_127_128 1 : LRRF1_CAN_DET_Near_TARGET_128 LRRF1_CAN_DET_Near_TARGET_127 LRRF1_Det_CRC_19 LRRF1_Det_MC_19 LRRF1_CAN_DET_RANGE_127 LRRF1_CAN_DET_AZIMUTH_127 LRRF1_CAN_DET_ELEVATION_128 LRRF1_CAN_SCAN_INDEX_2LSB_128 LRRF1_CAN_DET_RANGE_128 LRRF1_CAN_DET_SUPER_RES_TARGET_1 LRRF1_CAN_DET_AZIMUTH_128 LRRF1_CAN_DET_CONFID_ELEVATION_1 LRRF1_CAN_DET_HOST_VEH_CLUTTER_1 LRRF1_CAN_DET_RANGE_RATE_128 LRRF1_CAN_DET_CONFID_AZIMUTH_128 LRRF1_CAN_DET_CONFID_ELEVAT_0006 LRRF1_CAN_DET_VALID_LEVEL_128 LRRF1_CAN_DET_AMPLITUDE_128 LRRF1_CAN_DET_CONFID_AZIMUTH_127 LRRF1_CAN_DET_ELEVATION_127 LRRF1_CAN_DET_SUPER_RES_TAR_0006 LRRF1_CAN_DET_VALID_LEVEL_127 LRRF1_CAN_SCAN_INDEX_2LSB_127 LRRF1_CAN_DET_AMPLITUDE_127 LRRF1_CAN_DET_RANGE_RATE_127 LRRF1_CAN_DET_HOST_VEH_CLUT_0006;
